VERSION ""

NS_ :

BS_:

BU_: VMCU TECU OBDScanT2 IC3 HPCU EMS ECUspare2 ECUspare1 DACU CIOM BBM

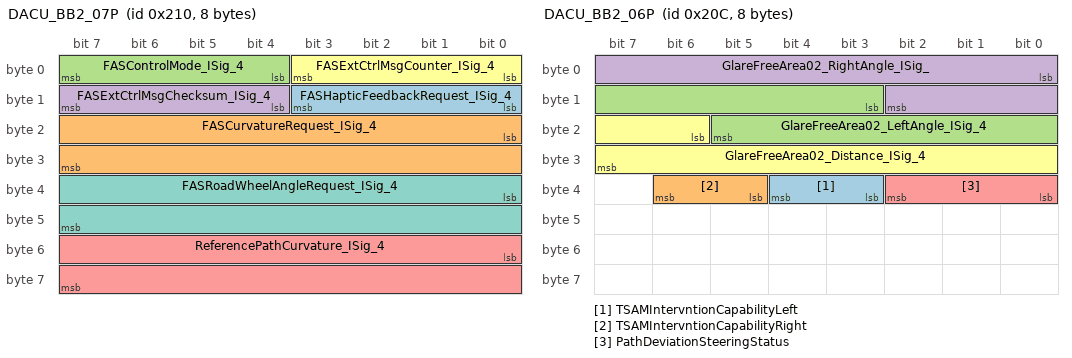
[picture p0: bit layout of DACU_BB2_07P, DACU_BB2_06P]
BO_ 528 DACU_BB2_07P: 8 DACU
 SG_ FASHapticFeedbackRequest_ISig_4 : 8|4@1+ (1,0) [0|0] ""  VMCU
 SG_ FASCurvatureRequest_ISig_4 : 16|16@1+ (7.62939E-006,-0.2472) [-0.2472|0.25279207365] "per_meter"  VMCU
 SG_ FASControlMode_ISig_4 : 4|4@1+ (0.1,0) [0|1.5] ""  VMCU
 SG_ FASExtCtrlMsgChecksum_ISig_4 : 12|4@1+ (1,0) [0|0] ""  VMCU
 SG_ ReferencePathCurvature_ISig_4 : 48|16@1+ (7.62939E-006,-0.2472) [-0.2472|0.25279207365] "per_meter"  VMCU
 SG_ FASExtCtrlMsgCounter_ISig_4 : 0|4@1+ (1,0) [0|0] ""  VMCU
 SG_ FASRoadWheelAngleRequest_ISig_4 : 32|16@1+ (5E-005,-1.6) [-1.6|1.67675] "rad"  VMCU

BO_ 524 DACU_BB2_06P: 8 DACU
 SG_ TSAMIntervntionCapabilityLeft : 35|2@1+ (1,0) [0|0] ""  IC3
 SG_ TSAMIntervntionCapabilityRight : 37|2@1+ (1,0) [0|0] ""  IC3
 SG_ GlareFreeArea02_LeftAngle_ISig_4 : 11|11@1+ (0.0494,-31.65) [-31.65|69.4718] "deg"  VMCU
 SG_ GlareFreeArea02_RightAngle_ISig_ : 0|11@1+ (0.0494,-31.65) [-31.65|69.4718] "deg"  VMCU
 SG_ PathDeviationSteeringStatus : 32|3@1+ (1,0) [0|0] ""  IC3
 SG_ GlareFreeArea02_Distance_ISig_4 : 22|10@1+ (0.5,0) [0|511.5] "m"  VMCU

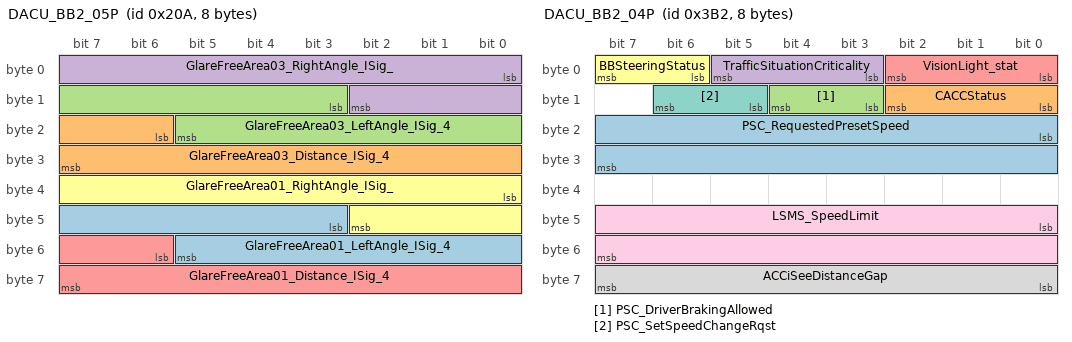
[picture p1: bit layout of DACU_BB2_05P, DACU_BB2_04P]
BO_ 522 DACU_BB2_05P: 8 DACU
 SG_ GlareFreeArea01_LeftAngle_ISig_4 : 43|11@1+ (0.0494,-31.65) [-31.65|69.4718] "deg"  VMCU
 SG_ GlareFreeArea03_Distance_ISig_4 : 22|10@1+ (0.5,0) [0|511.5] "m"  VMCU
 SG_ GlareFreeArea03_LeftAngle_ISig_4 : 11|11@1+ (0.0494,-31.65) [-31.65|69.4718] "deg"  VMCU
 SG_ GlareFreeArea03_RightAngle_ISig_ : 0|11@1+ (0.0494,-31.65) [-31.65|69.4718] "deg"  VMCU
 SG_ GlareFreeArea01_Distance_ISig_4 : 54|10@1+ (0.5,0) [0|511.5] "m"  VMCU
 SG_ GlareFreeArea01_RightAngle_ISig_ : 32|11@1+ (0.0494,-31.65) [-31.65|69.4718] "deg"  VMCU

BO_ 946 DACU_BB2_04P: 8 DACU
 SG_ PSC_RequestedPresetSpeed : 16|16@1+ (0.00390625,0) [0|255.99609375] "Km_per_h"  VMCU
 SG_ CACCStatus : 8|3@1+ (1,0) [0|0] ""  IC3,TECU
 SG_ PSC_DriverBrakingAllowed : 11|2@1+ (1,0) [0|0] ""  VMCU
 SG_ TrafficSituationCriticality : 3|3@1+ (1,0) [0|7] ""  IC3
 SG_ VisionLight_stat : 0|3@1+ (1,0) [0|0] ""  VMCU
 SG_ BBSteeringStatus : 6|2@1+ (1,0) [0|0] ""  BBM
 SG_ PSC_SetSpeedChangeRqst : 13|2@1+ (1,0) [0|0] ""  VMCU
 SG_ ACCiSeeDistanceGap : 56|8@1+ (1,-127) [-127|128] "m"  TECU
 SG_ LSMS_SpeedLimit : 40|16@1+ (0.00390625,0) [0|255.99609375] "Km_per_h"  VMCU

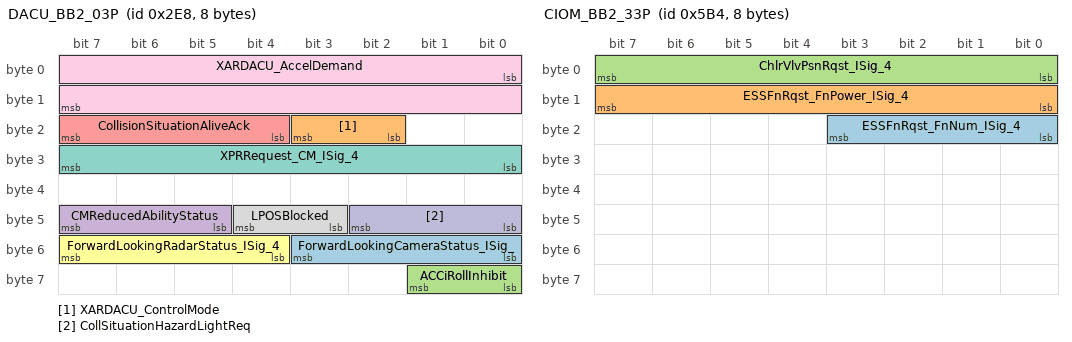
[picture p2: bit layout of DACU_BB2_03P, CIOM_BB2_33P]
BO_ 744 DACU_BB2_03P: 8 DACU
 SG_ ForwardLookingCameraStatus_ISig_ : 48|4@1+ (1,0) [0|0] ""  IC3
 SG_ XARDACU_ControlMode : 18|2@1+ (1,0) [0|0] ""  EMS,TECU
 SG_ ACCiRollInhibit : 56|2@1+ (1,0) [0|0] ""  TECU
 SG_ CMReducedAbilityStatus : 45|3@1+ (1,0) [0|0] ""  IC3
 SG_ CollisionSituationAliveAck : 20|4@1+ (1,0) [0|15] "Count"  VMCU
 SG_ ForwardLookingRadarStatus_ISig_4 : 52|4@1+ (1,0) [0|0] ""  IC3
 SG_ XPRRequest_CM_ISig_4 : 24|8@1+ (1,0) [0|255] "NotApplicable"  VMCU
 SG_ LPOSBlocked : 43|2@1+ (1,0) [0|0] ""  IC3
 SG_ XARDACU_AccelDemand : 0|16@1+ (0.00048828125,-15.687) [-15.687|16.31251171875] "m_per_s_squared"  EMS,TECU
 SG_ CollSituationHazardLightReq : 40|3@1+ (1,0) [0|0] ""  VMCU

BO_ 560 DACU_BB2_02P: 8 DACU
 SG_ PathDeviationDriverAlert : 24|3@1+ (1,0) [0|0] ""  IC3,VMCU
 SG_ CM_DisengageDrivelineRequest : 51|2@1+ (1,0) [0|0] ""  TECU
 SG_ ACCBrakeRequestStatus : 30|2@1+ (1,0) [0|0] ""  VMCU
 SG_ FrontalCollisionDriverAlert_ISig : 19|3@1+ (1,0) [0|0] ""  IC3,VMCU
 SG_ ACC_SGOFaultCondStat_SeatBelt : 59|1@1+ (1,0) [0|0] ""  IC3
 SG_ CM_Status_ISig_4 : 43|3@1+ (1,0) [0|0] ""  CIOM,VMCU,IC3
 SG_ DASApplicationStatus_ISig_4 : 40|3@1+ (1,0) [0|0] ""  IC3,VMCU,CIOM
 SG_ ACC_Status : 16|3@1+ (1,0) [0|0] ""  VMCU,IC3,TECU
 SG_ LKSApplicationStatus_ISig_4 : 27|3@1+ (1,0) [0|0] ""  CIOM,VMCU,IC3
 SG_ LCSSystemStatus : 48|3@1+ (1,0) [0|0] ""  IC3,CIOM
 SG_ ACC_SGOFaultCondStat_SigStat : 60|1@1+ (1,0) [0|0] ""  IC3
 SG_ ACC_SGOFaultCondStat_Target : 58|1@1+ (1,0) [0|0] ""  IC3
 SG_ FCW_Status : 46|2@1+ (1,0) [0|0] ""  IC3,CIOM,VMCU
 SG_ DriverImpairedDriverAlert_ISig_4 : 32|3@1+ (1,0) [0|0] ""  IC3,VMCU
 SG_ DriverVigilanceLevel : 35|3@1+ (1,0) [0|0] ""  IC3,VMCU
 SG_ ACCForwardVehicleSpeed_ISig_4 : 8|8@1+ (1,0) [0|255] "Km_per_h"  TECU,IC3
 SG_ ACC_SGOFaultCondStat_Door : 57|1@1+ (1,0) [0|0] ""  IC3
 SG_ ACCTargetDetected : 22|2@1+ (1,0) [0|0] ""  IC3
 SG_ ACCForwardVehicleDistance_ISig_4 : 0|8@1+ (1,0) [0|255] "m"  IC3,TECU
 SG_ LKSCorrectiveSteeringStatus : 61|3@1+ (1,0) [0|0] ""  IC3,VMCU,CIOM
 SG_ ACC_SGOFaultCondStat_Other : 55|1@1+ (1,0) [0|0] ""  IC3
 SG_ LCSSoundSettingStatus : 53|2@1+ (1,0) [0|0] ""  IC3
 SG_ ACC_SGOFaultCondStat_Speed : 56|1@1+ (1,0) [0|0] ""  IC3

BO_ 1460 CIOM_BB2_33P: 8 CIOM
 SG_ ESSFnRqst_FnNum_ISig_4 : 16|4@1+ (1,0) [0|15] "NotApplicable"  HPCU
 SG_ ESSFnRqst_FnPower_ISig_4 : 8|8@1+ (1,0) [0|255] "Percent"  HPCU
 SG_ ChlrVlvPsnRqst_ISig_4 : 0|8@1+ (1,0) [0|255] "Percent"  HPCU

BO_ 936 CIOM_BB2_32S_FCM: 8 TECU
 SG_ CIOM_BB2_32S_FCS : 0|64@1+ (1,0) [0|0] ""  CIOM

BO_ 935 CIOM_BB2_32S: 16 CIOM
 SG_ EncryptedGBUnlockAuth_stat : 0|128@1+ (1,0) [0|0] ""  TECU

BO_ 1369 CIOM_BB2_31S: 8 CIOM
 SG_ ParkClimTimerStat_Tue_ISig_4 : 15|1@1+ (1,0) [0|0] ""  IC3
 SG_ ParkClimTimerStat_Mon_ISig_4 : 17|1@1+ (1,0) [0|0] ""  IC3
 SG_ ParkClimTimerStat_Hrs_ISig_4 : 31|8@1+ (1,0) [0|255] "h"  IC3
 SG_ ParkClimTimerStat_TotalNoTimers_ : 23|8@1+ (1,0) [0|0] ""  IC3
 SG_ ParkClimTimerStat_Thu_ISig_4 : 16|1@1+ (1,0) [0|0] ""  IC3
 SG_ ParkClimTimerStat_MinRes_ISig_4 : 7|3@1+ (1,0) [0|0] ""  IC3
 SG_ ParkClimTimerStat_Status_ISig_4 : 13|2@1+ (1,0) [0|0] ""  IC3
 SG_ ParkClimTimerStat_Sun_ISig_4 : 20|1@1+ (1,0) [0|0] ""  IC3
 SG_ ParkClimTimerStat_sg_UB_ISig_4 : 63|1@1+ (1,0) [0|0] ""  IC3
 SG_ ParkClimTimerStat_TimerNr_ISig_4 : 39|8@1+ (1,0) [0|0] ""  IC3
 SG_ ParkClimTimerStat_Rec_ISig_4 : 19|1@1+ (1,0) [0|0] ""  IC3
 SG_ ParkClimTimerStat_Wed_ISig_4 : 22|1@1+ (1,0) [0|0] ""  IC3
 SG_ ParkClimTimerStat_Min_ISig_4 : 55|8@1+ (1,0) [0|255] "min"  IC3
 SG_ ParkClimTimerStat_Type_ISig_4 : 10|3@1+ (1,0) [0|0] ""  IC3
 SG_ ParkClimTimerStat_Sat_ISig_4 : 21|1@1+ (1,0) [0|0] ""  IC3
 SG_ ParkClimTimerStat_Temp_ISig_4 : 47|8@1+ (0.5,0) [0|127.5] "DegreeC"  IC3
 SG_ ParkClimTimerStat_Dur_ISig_4 : 0|7@1+ (1,0) [0|127] "min"  IC3
 SG_ ParkClimTimerStat_Fri_ISig_4 : 18|1@1+ (1,0) [0|0] ""  IC3

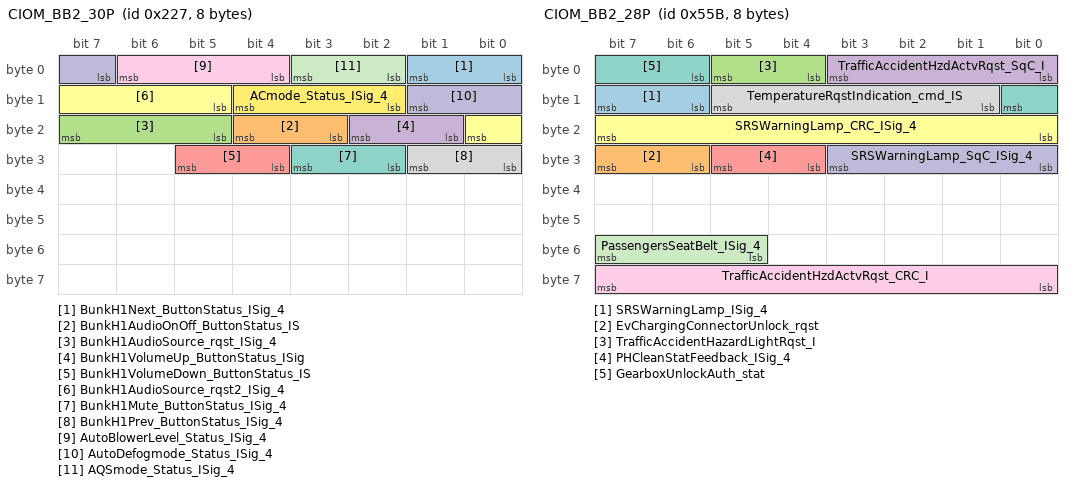
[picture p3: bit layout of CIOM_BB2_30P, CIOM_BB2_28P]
BO_ 551 CIOM_BB2_30P: 8 CIOM
 SG_ BunkH1Next_ButtonStatus_ISig_4 : 0|2@1+ (1,0) [0|0] ""  IC3
 SG_ BunkH1AudioOnOff_ButtonStatus_IS : 19|2@1+ (1,0) [0|0] ""  IC3
 SG_ BunkH1AudioSource_rqst_ISig_4 : 21|3@1+ (1,0) [0|0] ""  IC3
 SG_ BunkH1VolumeUp_ButtonStatus_ISig : 17|2@1+ (1,0) [0|0] ""  IC3
 SG_ BunkH1VolumeDown_ButtonStatus_IS : 28|2@1+ (1,0) [0|0] ""  IC3
 SG_ BunkH1AudioSource_rqst2_ISig_4 : 13|4@1+ (1,0) [0|0] ""  IC3
 SG_ BunkH1Mute_ButtonStatus_ISig_4 : 26|2@1+ (1,0) [0|0] ""  IC3
 SG_ BunkH1Prev_ButtonStatus_ISig_4 : 24|2@1+ (1,0) [0|0] ""  IC3
 SG_ AutoBlowerLevel_Status_ISig_4 : 4|3@1+ (1,0) [0|0] ""  IC3
 SG_ AutoDefogmode_Status_ISig_4 : 7|3@1+ (1,0) [0|0] ""  IC3
 SG_ AQSmode_Status_ISig_4 : 2|2@1+ (1,0) [0|0] ""  IC3
 SG_ ACmode_Status_ISig_4 : 10|3@1+ (1,0) [0|0] ""  IC3

BO_ 550 CIOM_BB2_29P: 8 CIOM
 SG_ LKSCSEnableSwitch_rqst : 0|2@1+ (1,0) [0|0] ""  DACU

BO_ 1371 CIOM_BB2_28P: 8 CIOM
 SG_ SRSWarningLamp_ISig_4 : 14|2@1+ (1,0) [0|0] ""  IC3
 SG_ EvChargingConnectorUnlock_rqst : 30|2@1+ (1,0) [0|0] ""  HPCU
 SG_ TrafficAccidentHazardLightRqst_I : 4|2@1+ (1,0) [0|0] ""  VMCU
 SG_ TrafficAccidentHzdActvRqst_SqC_I : 0|4@1+ (1,0) [0|15] "Count"  VMCU
 SG_ PHCleanStatFeedback_ISig_4 : 28|2@1+ (1,0) [0|0] ""  IC3
 SG_ SRSWarningLamp_CRC_ISig_4 : 16|8@1+ (1,0) [0|255] ""  IC3
 SG_ GearboxUnlockAuth_stat : 6|3@1+ (1,0) [0|0] ""  TECU
 SG_ TemperatureRqstIndication_cmd_IS : 9|5@1+ (1,0) [0|0] ""  IC3
 SG_ TrafficAccidentHzdActvRqst_CRC_I : 56|8@1+ (1,0) [0|255] ""  VMCU
 SG_ SRSWarningLamp_SqC_ISig_4 : 24|4@1+ (1,0) [0|15] "Count"  IC3
 SG_ PassengersSeatBelt_ISig_4 : 53|3@1+ (1,0) [0|0] ""  IC3,BBM,DACU

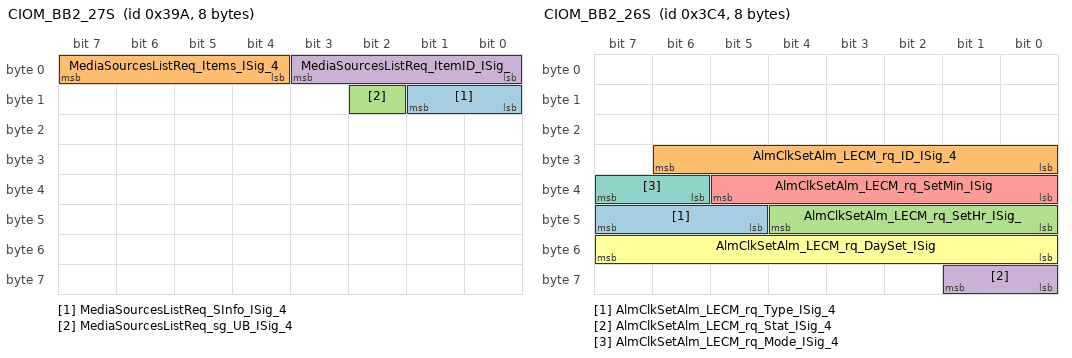
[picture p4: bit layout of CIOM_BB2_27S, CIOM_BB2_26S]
BO_ 922 CIOM_BB2_27S: 8 CIOM
 SG_ MediaSourcesListReq_SInfo_ISig_4 : 8|2@1+ (1,0) [0|0] ""  IC3
 SG_ MediaSourcesListReq_Items_ISig_4 : 4|4@1+ (1,0) [0|0] ""  IC3
 SG_ MediaSourcesListReq_sg_UB_ISig_4 : 10|1@1+ (1,0) [0|0] ""  IC3
 SG_ MediaSourcesListReq_ItemID_ISig_ : 0|4@1+ (1,0) [0|0] ""  IC3

BO_ 964 CIOM_BB2_26S: 8 CIOM
 SG_ AlmClkSetAlm_LECM_rq_Type_ISig_4 : 45|3@1+ (1,0) [0|0] ""  IC3
 SG_ AlmClkSetAlm_LECM_rq_ID_ISig_4 : 24|7@1+ (1,0) [0|0] ""  IC3
 SG_ AlmClkSetAlm_LECM_rq_SetHr_ISig_ : 40|5@1+ (1,0) [0|31] "h"  IC3
 SG_ AlmClkSetAlm_LECM_rq_Stat_ISig_4 : 56|2@1+ (1,0) [0|0] ""  IC3
 SG_ AlmClkSetAlm_LECM_rq_SetMin_ISig : 32|6@1+ (1,0) [0|63] "min"  IC3
 SG_ AlmClkSetAlm_LECM_rq_DaySet_ISig : 48|8@1+ (1,0) [0|255] ""  IC3
 SG_ AlmClkSetAlm_LECM_rq_Mode_ISig_4 : 38|2@1+ (1,0) [0|0] ""  IC3

BO_ 845 CIOM_BB2_25P: 8 CIOM
 SG_ TipperTailGateRequest_UB_ISig_4 : 23|1@1+ (1,0) [0|0] ""  BBM
 SG_ TrafficAccShutDownReq_CRC_ISig_4 : 48|8@1+ (1,0) [0|255] ""  VMCU
 SG_ ExtraHeating_status_ISig_4 : 32|2@1+ (1,0) [0|0] ""  IC3
 SG_ FrontalCollisionAccidentStatus_I : 39|2@1+ (1,0) [0|0] ""  DACU
 SG_ LoadDistributionRequested_UB_ISi : 36|1@1+ (1,0) [0|0] ""  VMCU
 SG_ TipperUpDownRequest_ISig_4 : 17|3@1+ (1,0) [0|0] ""  BBM
 SG_ TipperTarpaulinRequest_UB_ISig_4 : 27|1@1+ (1,0) [0|0] ""  BBM
 SG_ LoadDistributionRequested_ISig_4 : 28|4@1+ (1,0) [0|0] ""  VMCU
 SG_ TipperShakerRequest_UB_ISig_4 : 21|1@1+ (1,0) [0|0] ""  BBM
 SG_ TailLiftMotionRequest_UB_ISig_4 : 20|1@1+ (1,0) [0|0] ""  BBM
 SG_ TipperTailGateRequest_ISig_4 : 8|3@1+ (1,0) [0|0] ""  BBM
 SG_ TipperTippingBodySelection_ISig_ : 6|2@1+ (1,0) [0|0] ""  BBM
 SG_ TipperEmergencyStop_ISig_4 : 0|2@1+ (1,0) [0|0] ""  BBM
 SG_ TipperTippingBodySelection_UB_IS : 26|1@1+ (1,0) [0|0] ""  BBM
 SG_ ExtraBbWrcWatchdog_ISig_4 : 2|2@1+ (1,0) [0|0] ""  BBM
 SG_ TipperEmergencyStop_UB_ISig_4 : 25|1@1+ (1,0) [0|0] ""  BBM
 SG_ AutoFrontWheelDriveDrvReq : 37|2@1+ (1,0) [0|0] ""  VMCU
 SG_ ShortStopHeater_cmd_ISig_4 : 34|2@1+ (1,0) [0|0] ""  VMCU
 SG_ TipperUpDownRequest_UB_ISig_4 : 24|1@1+ (1,0) [0|0] ""  BBM
 SG_ TailLiftMotionRequest_ISig_4 : 14|3@1+ (1,0) [0|0] ""  BBM
 SG_ TipperShakerRequest_ISig_4 : 4|2@1+ (1,0) [0|0] ""  BBM
 SG_ TrafficAccShutDownReq_Rqst_ISig_ : 60|2@1+ (1,0) [0|0] ""  VMCU
 SG_ TipperTarpaulinRequest_ISig_4 : 11|3@1+ (1,0) [0|0] ""  BBM
 SG_ TrafficAccShutDownReq_SqC_ISig_4 : 56|4@1+ (1,0) [0|0] ""  VMCU
 SG_ ExtraBbWrcWatchdog_UB_ISig_4 : 22|1@1+ (1,0) [0|0] ""  BBM
 SG_ ABSInhibitRqstDenied : 41|2@1+ (1,0) [0|0] ""  IC3

BO_ 1074 CIOM_BB2_21S: 8 CIOM
 SG_ DynamicCode_value : 0|32@1+ (1,0) [0|4294967295] "NotApplicable"  IC3

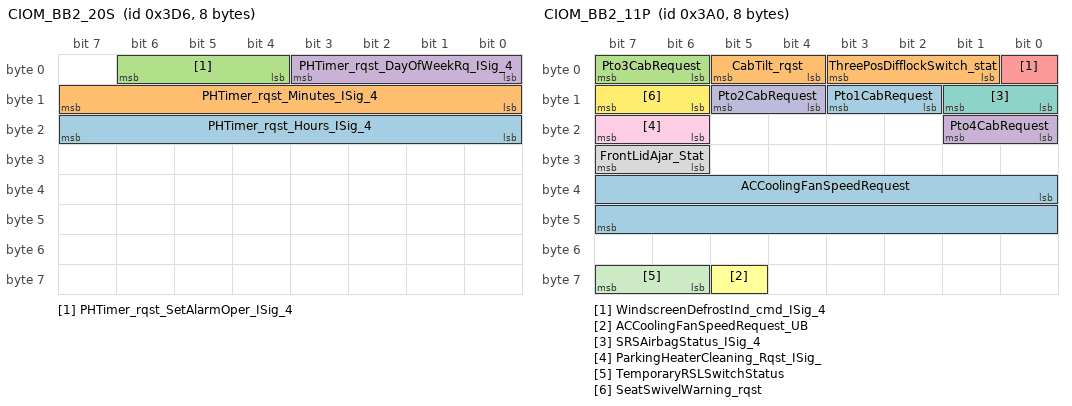
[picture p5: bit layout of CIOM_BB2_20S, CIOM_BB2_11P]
BO_ 982 CIOM_BB2_20S: 8 CIOM
 SG_ PHTimer_rqst_Hours_ISig_4 : 16|8@1+ (1,0) [0|255] "h"  VMCU
 SG_ PHTimer_rqst_Minutes_ISig_4 : 8|8@1+ (1,0) [0|255] "min"  VMCU
 SG_ PHTimer_rqst_SetAlarmOper_ISig_4 : 4|3@1+ (1,0) [0|0] ""  VMCU
 SG_ PHTimer_rqst_DayOfWeekRq_ISig_4 : 0|4@1+ (1,0) [0|0] ""  VMCU

BO_ 943 CIOM_BB2_13S_FCM: 8 EMS
 SG_ CIOM_BB2_13S_FCS : 0|64@1+ (1,0) [0|0] ""  CIOM

BO_ 940 CIOM_BB2_13S: 16 CIOM
 SG_ EngineStartAuth_stat : 0|128@1+ (1,0) [0|0] ""  EMS

BO_ 937 CIOM_BB2_12S_FCM: 8 VMCU
 SG_ CIOM_BB2_12S_FCS : 0|64@1+ (1,0) [0|0] ""  CIOM

BO_ 934 CIOM_BB2_12S: 16 CIOM
 SG_ KeyAuthEncrypted_stat : 0|128@1+ (1,0) [0|0] ""  VMCU

BO_ 928 CIOM_BB2_11P: 8 CIOM
 SG_ ACCoolingFanSpeedRequest : 32|16@1+ (1,0) [0|65535] "rpm"  EMS
 SG_ CabTilt_rqst : 4|2@1+ (1,0) [0|0] ""  VMCU
 SG_ Pto3CabRequest : 6|2@1+ (1,0) [0|0] ""  BBM,VMCU
 SG_ Pto4CabRequest : 16|2@1+ (1,0) [0|0] ""  VMCU,BBM
 SG_ WindscreenDefrostInd_cmd_ISig_4 : 0|1@1+ (1,0) [0|0] ""  BBM
 SG_ ACCoolingFanSpeedRequest_UB : 61|1@1+ (1,0) [0|0] ""  EMS
 SG_ SRSAirbagStatus_ISig_4 : 8|2@1+ (1,0) [0|0] ""  DACU,IC3,VMCU
 SG_ FrontLidAjar_Stat : 30|2@1+ (1,0) [0|0] ""  VMCU
 SG_ ParkingHeaterCleaning_Rqst_ISig_ : 22|2@1+ (1,0) [0|0] ""  IC3
 SG_ Pto2CabRequest : 12|2@1+ (1,0) [0|0] ""  BBM,VMCU
 SG_ TemporaryRSLSwitchStatus : 62|2@1+ (1,0) [0|0] ""  IC3
 SG_ SeatSwivelWarning_rqst : 14|2@1+ (1,0) [0|0] ""  IC3
 SG_ Pto1CabRequest : 10|2@1+ (1,0) [0|0] ""  VMCU,BBM
 SG_ ThreePosDifflockSwitch_stat : 1|3@1+ (1,0) [0|0] ""  IC3

BO_ 857 CIOM_BB2_10P: 8 CIOM
 SG_ LCS_EnableSwitch_rqst : 40|2@1+ (1,0) [0|0] ""  DACU
 SG_ EscCrossCountryActivation_rqst : 52|2@1+ (1,0) [0|0] ""  VMCU
 SG_ StaticCornerLightMode : 54|2@1+ (1,0) [0|0] ""  VMCU
 SG_ SplitBoxDifflockActvnDrvrRqst_IS : 48|2@1+ (1,0) [0|0] ""  EMS,VMCU,IC3,TECU
 SG_ ATCFrontWheelDriveRequest : 61|2@1+ (1,0) [0|0] ""  VMCU
 SG_ ConstructionSwitch_stat : 50|2@1+ (1,0) [0|0] ""  TECU
 SG_ EscCabActionRequest : 8|3@1+ (1,0) [0|0] ""  VMCU
 SG_ AdjustRequestForIdle : 58|3@1+ (1,0) [0|0] ""  VMCU
 SG_ SCL_LogicPowerOutput_stat : 36|2@1+ (1,0) [0|0] ""  VMCU
 SG_ PinCode_validity_time : 0|8@1+ (1,1) [1|256] "h"  IC3
 SG_ StatTrailerBrakeSwitchStatus : 14|2@1+ (1,0) [0|0] ""  VMCU
 SG_ SplitBoxDifflockActvnDrvrRqst_UB : 32|1@1+ (1,0) [0|0] ""  EMS,TECU,VMCU,IC3
 SG_ RoofHatch_HMI_rqst : 16|3@1+ (1,0) [0|0] ""  VMCU
 SG_ EscCabEnable : 38|2@1+ (1,0) [0|0] ""  VMCU
 SG_ ExtraSideMarkers_Rqst : 19|2@1+ (1,0) [0|0] ""  VMCU
 SG_ LevelingThumbwheel_stat : 24|5@1+ (1,0) [0|0] ""  VMCU
 SG_ DASActivation_rqst : 44|2@1+ (1,0) [0|0] ""  DACU
 SG_ DriverSeatBeltSwitch_ISig_4 : 22|2@1+ (1,0) [0|0] ""  VMCU,DACU,BBM,IC3
 SG_ PinCode_stat : 29|3@1+ (1,0) [0|0] ""  IC3
 SG_ WarmUp_Request : 56|2@1+ (1,0) [0|0] ""  EMS
 SG_ LKSEnableSwitch_rqst : 46|2@1+ (1,0) [0|0] ""  DACU

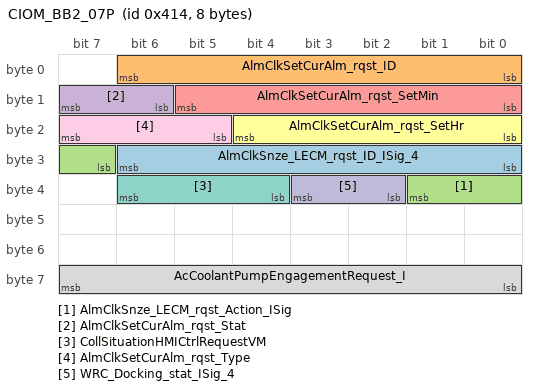
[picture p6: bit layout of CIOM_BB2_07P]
BO_ 1044 CIOM_BB2_07P: 8 CIOM
 SG_ AlmClkSnze_LECM_rqst_ID_ISig_4 : 24|7@1+ (1,0) [0|0] ""  IC3
 SG_ AlmClkSetCurAlm_rqst_ID : 0|7@1+ (1,0) [0|0] ""  VMCU
 SG_ AlmClkSnze_LECM_rqst_Action_ISig : 31|3@1+ (1,0) [0|0] ""  IC3
 SG_ AlmClkSetCurAlm_rqst_Stat : 14|2@1+ (1,0) [0|0] ""  VMCU
 SG_ AlmClkSetCurAlm_rqst_SetMin : 8|6@1+ (1,0) [0|63] "min"  VMCU
 SG_ AlmClkSetCurAlm_rqst_SetHr : 16|5@1+ (1,0) [0|31] "h"  VMCU
 SG_ CollSituationHMICtrlRequestVM : 36|3@1+ (1,0) [0|0] ""  IC3
 SG_ AcCoolantPumpEngagementRequest_I : 56|8@1+ (0.4,0) [0|102] "Percent"  EMS
 SG_ AlmClkSetCurAlm_rqst_Type : 21|3@1+ (1,0) [0|0] ""  VMCU
 SG_ WRC_Docking_stat_ISig_4 : 34|2@1+ (1,0) [0|0] ""  IC3

BO_ 847 CIOM_BB2_06P: 8 CIOM
 SG_ LiftAxle1DirectControl_UB_ISig_4 : 59|1@1+ (1,0) [0|0] ""  VMCU
 SG_ MirrorSelectRightMainBtn_stat_IS : 30|2@1+ (1,0) [0|0] ""  IC3
 SG_ WRCEngineStopRequest_ISig_4 : 38|2@1+ (1,0) [0|0] ""  BBM
 SG_ LiftAxle1DirectControl_ISig_4 : 56|3@1+ (1,0) [0|0] ""  VMCU
 SG_ MirrorSelectRightWideBtn_stat_IS : 6|2@1+ (1,0) [0|0] ""  IC3
 SG_ PanicAlarmFromKeyfob_rqst : 2|2@1+ (1,0) [0|0] ""  VMCU
 SG_ ParkingClimate_IndicationCmd_ISi : 51|3@1+ (1,0) [0|0] ""  IC3
 SG_ MirrorSelectLeftWideBtn_stat_ISi : 4|2@1+ (1,0) [0|0] ""  IC3
 SG_ WRCEngineStartRequest_ISig_4 : 36|2@1+ (1,0) [0|0] ""  BBM
 SG_ PW_Left_DS_SwStatus_ISig_4 : 19|3@1+ (1,0) [0|0] ""  IC3
 SG_ RegenerationSwitchStatus : 48|3@1+ (1,0) [0|0] ""  IC3
 SG_ PW_Right_DS_SwStatus_ISig_4 : 24|3@1+ (1,0) [0|0] ""  IC3
 SG_ DoorLock_stat_ISig_4 : 8|4@1+ (1,0) [0|0] ""  BBM,IC3
 SG_ WRCEngineStartRequest_UB_ISig_4 : 40|1@1+ (1,0) [0|0] ""  BBM
 SG_ LuggageAjar_stat : 32|3@1+ (1,0) [0|0] ""  IC3
 SG_ AlarmStatus_stat_ISig_4 : 44|4@1+ (1,0) [0|0] ""  IC3
 SG_ AlarmTriggeringCause_stat_ISig_4 : 12|4@1+ (1,0) [0|0] ""  BBM,IC3
 SG_ DoorsAjar_stat_UB_ISig_4 : 35|1@1+ (1,0) [0|0] ""  DACU,VMCU,IC3,BBM
 SG_ DoorsAjar_stat_ISig_4 : 16|3@1+ (1,0) [0|0] ""  IC3,VMCU,DACU,BBM
 SG_ WRCEngineStopRequest_UB_ISig_4 : 41|1@1+ (1,0) [0|0] ""  BBM
 SG_ DoorAutoFunction_rqst : 22|2@1+ (1,0) [0|0] ""  VMCU
 SG_ MirrorSelectLeftMainBtn_stat_ISi : 0|2@1+ (1,0) [0|0] ""  IC3

BO_ 841 CIOM_BB2_05P: 8 CIOM
 SG_ FPBRChangeReq_ISig_4 : 52|2@1+ (1,0) [0|0] ""  VMCU
 SG_ HeadLampUpDown_SwitchStatus : 32|3@1+ (1,0) [0|0] ""  VMCU
 SG_ Recirc_ButtonStatus_ISig_4 : 18|2@1+ (1,0) [0|0] ""  IC3
 SG_ Auto_ButtonStatus_ISig_4 : 14|2@1+ (1,0) [0|0] ""  IC3
 SG_ AirFlowSelectionFrontBtn_stat_IS : 35|2@1+ (1,0) [0|0] ""  IC3
 SG_ InteriorLightMode_rqst_IL_Mode : 48|3@1+ (1,0) [0|0] ""  VMCU
 SG_ InteriorLightMode_rqst_EventFlag : 51|1@1+ (1,0) [0|0] ""  VMCU
 SG_ BlackOutConvoyModeSwitchStatus : 24|3@1+ (1,0) [0|0] ""  VMCU
 SG_ Indicator_Lights_Alarm_rqst_ISig : 27|3@1+ (1,0) [0|0] ""  VMCU
 SG_ AirFlowSelectionDownBtn_stat_ISi : 16|2@1+ (1,0) [0|0] ""  IC3
 SG_ ParkingHeater_IndicationCmd_ISig : 39|1@1+ (1,0) [0|0] ""  BBM
 SG_ AirFlowSelectionUpBtn_stat_ISig_ : 10|2@1+ (1,0) [0|0] ""  IC3
 SG_ ApproachLight_HMI_rqst : 44|2@1+ (1,0) [0|0] ""  VMCU
 SG_ Temperature_FreeWheelStatus_ISig : 20|4@1+ (1,0) [0|0] ""  IC3
 SG_ AirBlowerSpeed_FreeWheelStatus_I : 40|4@1+ (1,0) [0|0] ""  IC3
 SG_ CabInteriorTempVentilated_Stat_I : 0|10@1+ (0.125,-40) [-40|87.875] "DegreeC"  BBM
 SG_ PreTrip_ButtonStat3 : 30|2@1+ (1,0) [0|0] ""  IC3
 SG_ ParkHeaterCooler_ButtonStatus_IS : 12|2@1+ (1,0) [0|0] ""  IC3
 SG_ WindscreenDefrost_ButtonStatus_I : 46|2@1+ (1,0) [0|0] ""  IC3
 SG_ AC_ButtonStatus_ISig_4 : 37|2@1+ (1,0) [0|0] ""  IC3

CM_ SG_ 744 XARDACU_AccelDemand "65024 - 65279 Error ; 65280 - 65535 Not available";
CM_ SG_ 560 ACCForwardVehicleSpeed_ISig_4 "254 Error ; 255 Not available";
CM_ SG_ 560 ACCForwardVehicleDistance_ISig_4 "254 Error ; 255 Not Available";
CM_ SG_ 964 AlmClkSetAlm_LECM_rq_SetHr_ISig_ "30 Error ; 31 Not Available";
CM_ SG_ 964 AlmClkSetAlm_LECM_rq_SetMin_ISig "62 Error ; 63 Not Available";
CM_ SG_ 982 PHTimer_rqst_Hours_ISig_4 "254 Error ; 255 Not available";
CM_ SG_ 982 PHTimer_rqst_Minutes_ISig_4 "254 Error ; 255 Not available";
CM_ SG_ 928 ACCoolingFanSpeedRequest "65024 - 65279 Error ; 65280 - 65535 Not available";
CM_ SG_ 841 CabInteriorTempVentilated_Stat_I "1022 Error; 1023 Not Available";
BA_DEF_ BO_  "GenMsgStartDelayTime" INT 0 0;
BA_DEF_ BO_  "GenMsgDelayTime" INT 0 0;
BA_DEF_ BO_  "GenMsgCycleTime" INT 0 0;
BA_DEF_ BO_  "GenMsgSendType" ENUM  "Cyclic","NotUsed","NotUsed","NotUsed","NotUsed","NotUsed","NotUsed","IfActive","NoMsgSendType","NotUsed";
BA_DEF_ SG_  "GenSigStartValue" INT 0 0;
BA_DEF_ SG_  "GenSigCycleTimeActive" INT 0 0;
BA_DEF_ SG_  "GenSigCycleTime" INT 0 0;
BA_DEF_ SG_  "GenSigSendType" ENUM  "Cyclic","OnWrite","OnWriteWithRepetition","OnChange","OnChangeWithRepetition","IfActive","IfActiveWithRepetition","NoSigSendType","NotUsed","NotUsed","NotUsed","NotUsed","NotUsed";
BA_DEF_ BO_  "VFrameFormat" ENUM  "StandardCAN","ExtendedCAN","reserved","J1939PG","reserved","reserved","reserved","reserved","reserved","reserved","reserved","reserved","reserved","reserved","StandardCAN_FD","ExtendedCAN_FD";
BA_DEF_ SG_  "SigType" ENUM  "Default","Range","RangeSigned","ASCII","Discrete","Control","ReferencePGN","DTC","StringDelimiter","StringLength","StringLengthControl";
BA_DEF_ SG_  "SeToolVersion_SIGNAL" STRING ;
BA_DEF_ SG_  "SeToolUniqueID_SIGNAL" STRING ;
BA_DEF_ SG_  "SeToolOwnerSigGroup_SIGNAL" STRING ;
BA_DEF_ SG_  "SeToolOwnerSigGroupID_SIGNAL" STRING ;
BA_DEF_ SG_  "SeToolName_SIGNAL" STRING ;
BA_DEF_ SG_  "SeToolItemID_SIGNAL" STRING ;
BA_DEF_ SG_  "SeToolAncestorID_SIGNAL" STRING ;
BA_DEF_ SG_  "Platform_VMCU1_Sig" ENUM  "No","Yes";
BA_DEF_ SG_  "Platform_FactoryIf_Sig" ENUM  "No","Yes";
BA_DEF_ BO_  "NmAsrMessage" ENUM  "No","Yes";
BA_DEF_ SG_  "NeedsUpdateBit" ENUM  "No","Yes";
BA_DEF_ SG_  "MmAnSignal" ENUM  "No","Yes";
BA_DEF_ SG_  "GenSigMaxLatency" INT 0 65535;
BA_DEF_ SG_  "GenSigILSupport" ENUM  "Yes","No";
BA_DEF_ BO_  "GenMsgILSupport" ENUM  "No","Yes";
BA_DEF_ BO_  "DiagUUDTResponse" ENUM  "No","Yes";
BA_DEF_ BO_  "DiagState" ENUM  "No","Yes";
BA_DEF_ BO_  "DiagResponse" ENUM  "No","Yes";
BA_DEF_ BO_  "DiagRequest" ENUM  "No","Yes";
BA_DEF_ BO_  "DiagConnection" HEX 0 65535;
BA_DEF_ BO_  "CanTpSTmin" INT 0 255;
BA_DEF_ BO_  "CanTpFcFrameId" HEX 0 2147483647;
BA_DEF_ BO_  "CanTpBs" INT 0 255;
BA_DEF_ SG_  "SystemSignalLongSymbol" STRING ;
BA_DEF_REL_ BU_SG_REL_  "GenSigTimeoutTime" INT 0 65535;
BA_DEF_REL_ BU_SG_REL_  "GenSigFirstTimeoutTime" INT 0 65535;
BA_DEF_DEF_  "GenMsgStartDelayTime" 0;
BA_DEF_DEF_  "GenMsgDelayTime" 0;
BA_DEF_DEF_  "GenMsgCycleTime" 0;
BA_DEF_DEF_  "GenMsgSendType" "Cyclic";
BA_DEF_DEF_  "GenSigStartValue" 0;
BA_DEF_DEF_  "GenSigCycleTimeActive" 0;
BA_DEF_DEF_  "GenSigCycleTime" 0;
BA_DEF_DEF_  "GenSigSendType" "Cyclic";
BA_DEF_DEF_  "VFrameFormat" "ExtendedCAN";
BA_DEF_DEF_  "SigType" "Default";
BA_DEF_DEF_  "SeToolVersion_SIGNAL" "";
BA_DEF_DEF_  "SeToolUniqueID_SIGNAL" "";
BA_DEF_DEF_  "SeToolOwnerSigGroup_SIGNAL" "";
BA_DEF_DEF_  "SeToolOwnerSigGroupID_SIGNAL" "";
BA_DEF_DEF_  "SeToolName_SIGNAL" "";
BA_DEF_DEF_  "SeToolItemID_SIGNAL" "";
BA_DEF_DEF_  "SeToolAncestorID_SIGNAL" "";
BA_DEF_DEF_  "Platform_VMCU1_Sig" "No";
BA_DEF_DEF_  "Platform_FactoryIf_Sig" "No";
BA_DEF_DEF_  "NmAsrMessage" "No";
BA_DEF_DEF_  "NeedsUpdateBit" "No";
BA_DEF_DEF_  "MmAnSignal" "No";
BA_DEF_DEF_  "GenSigMaxLatency" 0;
BA_DEF_DEF_  "GenSigILSupport" "Yes";
BA_DEF_DEF_  "GenMsgILSupport" "Yes";
BA_DEF_DEF_  "DiagUUDTResponse" "No";
BA_DEF_DEF_  "DiagState" "No";
BA_DEF_DEF_  "DiagResponse" "No";
BA_DEF_DEF_  "DiagRequest" "No";
BA_DEF_DEF_  "DiagConnection" 0;
BA_DEF_DEF_  "CanTpSTmin" 0;
BA_DEF_DEF_  "CanTpFcFrameId" 2147483647;
BA_DEF_DEF_  "CanTpBs" 255;
BA_DEF_DEF_REL_ "GenSigTimeoutTime" 0;
BA_DEF_DEF_REL_ "GenSigFirstTimeoutTime" 0;
BA_DEF_DEF_  "SystemSignalLongSymbol" "";
BA_ "VFrameFormat" BO_ 528 0;
BA_ "GenMsgCycleTime" BO_ 528 20;
BA_ "GenMsgStartDelayTime" BO_ 528 5;
BA_ "VFrameFormat" BO_ 524 0;
BA_ "GenMsgCycleTime" BO_ 524 20;
BA_ "GenMsgStartDelayTime" BO_ 524 10;
BA_ "VFrameFormat" BO_ 522 0;
BA_ "GenMsgCycleTime" BO_ 522 20;
BA_ "GenMsgStartDelayTime" BO_ 522 10;
BA_ "VFrameFormat" BO_ 946 0;
BA_ "GenMsgCycleTime" BO_ 946 100;
BA_ "GenMsgStartDelayTime" BO_ 946 15;
BA_ "VFrameFormat" BO_ 744 0;
BA_ "GenMsgCycleTime" BO_ 744 40;
BA_ "GenMsgStartDelayTime" BO_ 744 5;
BA_ "VFrameFormat" BO_ 560 0;
BA_ "GenMsgCycleTime" BO_ 560 20;
BA_ "VFrameFormat" BO_ 1460 0;
BA_ "GenMsgCycleTime" BO_ 1460 100;
BA_ "GenMsgStartDelayTime" BO_ 1460 5;
BA_ "GenMsgILSupport" BO_ 936 0;
BA_ "VFrameFormat" BO_ 936 0;
BA_ "GenMsgSendType" BO_ 936 8;
BA_ "CanTpFcFrameId" BO_ 935 936;
BA_ "VFrameFormat" BO_ 935 0;
BA_ "GenMsgSendType" BO_ 935 8;
BA_ "GenMsgDelayTime" BO_ 935 20;
BA_ "VFrameFormat" BO_ 1369 0;
BA_ "GenMsgSendType" BO_ 1369 8;
BA_ "GenMsgDelayTime" BO_ 1369 20;
BA_ "GenMsgStartDelayTime" BO_ 1369 20;
BA_ "VFrameFormat" BO_ 551 0;
BA_ "GenMsgCycleTime" BO_ 551 40;
BA_ "GenMsgStartDelayTime" BO_ 551 30;
BA_ "VFrameFormat" BO_ 550 0;
BA_ "GenMsgCycleTime" BO_ 550 40;
BA_ "GenMsgStartDelayTime" BO_ 550 10;
BA_ "VFrameFormat" BO_ 1371 0;
BA_ "GenMsgCycleTime" BO_ 1371 100;
BA_ "GenMsgStartDelayTime" BO_ 1371 50;
BA_ "VFrameFormat" BO_ 922 0;
BA_ "GenMsgSendType" BO_ 922 8;
BA_ "GenMsgDelayTime" BO_ 922 50;
BA_ "VFrameFormat" BO_ 964 0;
BA_ "GenMsgSendType" BO_ 964 8;
BA_ "GenMsgDelayTime" BO_ 964 75;
BA_ "VFrameFormat" BO_ 845 0;
BA_ "GenMsgCycleTime" BO_ 845 50;
BA_ "GenMsgStartDelayTime" BO_ 845 40;
BA_ "VFrameFormat" BO_ 1074 0;
BA_ "GenMsgSendType" BO_ 1074 8;
BA_ "GenMsgDelayTime" BO_ 1074 100;
BA_ "GenMsgStartDelayTime" BO_ 1074 15;
BA_ "VFrameFormat" BO_ 982 0;
BA_ "GenMsgSendType" BO_ 982 8;
BA_ "GenMsgDelayTime" BO_ 982 75;
BA_ "GenMsgILSupport" BO_ 943 0;
BA_ "VFrameFormat" BO_ 943 0;
BA_ "GenMsgSendType" BO_ 943 8;
BA_ "CanTpFcFrameId" BO_ 940 943;
BA_ "VFrameFormat" BO_ 940 0;
BA_ "GenMsgSendType" BO_ 940 8;
BA_ "GenMsgDelayTime" BO_ 940 20;
BA_ "GenMsgILSupport" BO_ 937 0;
BA_ "VFrameFormat" BO_ 937 0;
BA_ "GenMsgSendType" BO_ 937 8;
BA_ "CanTpFcFrameId" BO_ 934 937;
BA_ "VFrameFormat" BO_ 934 0;
BA_ "GenMsgSendType" BO_ 934 8;
BA_ "GenMsgDelayTime" BO_ 934 20;
BA_ "VFrameFormat" BO_ 928 0;
BA_ "GenMsgCycleTime" BO_ 928 95;
BA_ "GenMsgStartDelayTime" BO_ 928 40;
BA_ "VFrameFormat" BO_ 857 0;
BA_ "GenMsgCycleTime" BO_ 857 55;
BA_ "GenMsgStartDelayTime" BO_ 857 10;
BA_ "VFrameFormat" BO_ 1044 0;
BA_ "GenMsgCycleTime" BO_ 1044 100;
BA_ "GenMsgStartDelayTime" BO_ 1044 15;
BA_ "VFrameFormat" BO_ 847 0;
BA_ "GenMsgCycleTime" BO_ 847 50;
BA_ "GenMsgStartDelayTime" BO_ 847 25;
BA_ "VFrameFormat" BO_ 841 0;
BA_ "GenMsgCycleTime" BO_ 841 20;
BA_ "GenMsgStartDelayTime" BO_ 841 15;
BA_ "GenSigCycleTime" SG_ 528 FASHapticFeedbackRequest_ISig_4 100;
BA_ "GenSigCycleTimeActive" SG_ 528 FASHapticFeedbackRequest_ISig_4 100;
BA_ "GenSigStartValue" SG_ 528 FASHapticFeedbackRequest_ISig_4 15;
BA_ "GenSigMaxLatency" SG_ 528 FASHapticFeedbackRequest_ISig_4 25;
BA_ "GenSigCycleTime" SG_ 528 FASCurvatureRequest_ISig_4 100;
BA_ "GenSigCycleTimeActive" SG_ 528 FASCurvatureRequest_ISig_4 100;
BA_ "GenSigStartValue" SG_ 528 FASCurvatureRequest_ISig_4 65535;
BA_ "GenSigMaxLatency" SG_ 528 FASCurvatureRequest_ISig_4 25;
BA_ "GenSigCycleTime" SG_ 528 FASControlMode_ISig_4 100;
BA_ "GenSigCycleTimeActive" SG_ 528 FASControlMode_ISig_4 100;
BA_ "GenSigStartValue" SG_ 528 FASControlMode_ISig_4 15;
BA_ "GenSigMaxLatency" SG_ 528 FASControlMode_ISig_4 25;
BA_ "GenSigCycleTime" SG_ 528 FASExtCtrlMsgChecksum_ISig_4 100;
BA_ "GenSigCycleTimeActive" SG_ 528 FASExtCtrlMsgChecksum_ISig_4 100;
BA_ "GenSigMaxLatency" SG_ 528 FASExtCtrlMsgChecksum_ISig_4 25;
BA_ "GenSigCycleTime" SG_ 528 ReferencePathCurvature_ISig_4 100;
BA_ "GenSigCycleTimeActive" SG_ 528 ReferencePathCurvature_ISig_4 100;
BA_ "GenSigStartValue" SG_ 528 ReferencePathCurvature_ISig_4 65535;
BA_ "GenSigMaxLatency" SG_ 528 ReferencePathCurvature_ISig_4 25;
BA_ "GenSigCycleTime" SG_ 528 FASExtCtrlMsgCounter_ISig_4 100;
BA_ "GenSigCycleTimeActive" SG_ 528 FASExtCtrlMsgCounter_ISig_4 100;
BA_ "GenSigMaxLatency" SG_ 528 FASExtCtrlMsgCounter_ISig_4 25;
BA_ "GenSigCycleTime" SG_ 528 FASRoadWheelAngleRequest_ISig_4 100;
BA_ "GenSigCycleTimeActive" SG_ 528 FASRoadWheelAngleRequest_ISig_4 100;
BA_ "GenSigStartValue" SG_ 528 FASRoadWheelAngleRequest_ISig_4 65535;
BA_ "GenSigMaxLatency" SG_ 528 FASRoadWheelAngleRequest_ISig_4 25;
BA_ "GenSigCycleTime" SG_ 524 TSAMIntervntionCapabilityLeft 100;
BA_ "GenSigCycleTimeActive" SG_ 524 TSAMIntervntionCapabilityLeft 100;
BA_ "GenSigStartValue" SG_ 524 TSAMIntervntionCapabilityLeft 3;
BA_ "GenSigCycleTime" SG_ 524 TSAMIntervntionCapabilityRight 100;
BA_ "GenSigCycleTimeActive" SG_ 524 TSAMIntervntionCapabilityRight 100;
BA_ "GenSigStartValue" SG_ 524 TSAMIntervntionCapabilityRight 3;
BA_ "GenSigCycleTime" SG_ 524 GlareFreeArea02_LeftAngle_ISig_4 100;
BA_ "GenSigCycleTimeActive" SG_ 524 GlareFreeArea02_LeftAngle_ISig_4 100;
BA_ "GenSigStartValue" SG_ 524 GlareFreeArea02_LeftAngle_ISig_4 2047;
BA_ "GenSigMaxLatency" SG_ 524 GlareFreeArea02_LeftAngle_ISig_4 26;
BA_ "Platform_VMCU1_Sig" SG_ 524 GlareFreeArea02_LeftAngle_ISig_4 1;
BA_ "GenSigCycleTime" SG_ 524 GlareFreeArea02_RightAngle_ISig_ 100;
BA_ "GenSigCycleTimeActive" SG_ 524 GlareFreeArea02_RightAngle_ISig_ 100;
BA_ "GenSigStartValue" SG_ 524 GlareFreeArea02_RightAngle_ISig_ 2047;
BA_ "GenSigMaxLatency" SG_ 524 GlareFreeArea02_RightAngle_ISig_ 26;
BA_ "Platform_VMCU1_Sig" SG_ 524 GlareFreeArea02_RightAngle_ISig_ 1;
BA_ "SystemSignalLongSymbol" SG_ 524 GlareFreeArea02_RightAngle_ISig_ "GlareFreeArea02_RightAngle_ISig_4";
BA_ "GenSigCycleTime" SG_ 524 PathDeviationSteeringStatus 100;
BA_ "GenSigCycleTimeActive" SG_ 524 PathDeviationSteeringStatus 100;
BA_ "GenSigStartValue" SG_ 524 PathDeviationSteeringStatus 7;
BA_ "GenSigCycleTime" SG_ 524 GlareFreeArea02_Distance_ISig_4 100;
BA_ "GenSigCycleTimeActive" SG_ 524 GlareFreeArea02_Distance_ISig_4 100;
BA_ "GenSigStartValue" SG_ 524 GlareFreeArea02_Distance_ISig_4 1023;
BA_ "GenSigMaxLatency" SG_ 524 GlareFreeArea02_Distance_ISig_4 26;
BA_ "Platform_VMCU1_Sig" SG_ 524 GlareFreeArea02_Distance_ISig_4 1;
BA_ "GenSigCycleTime" SG_ 522 GlareFreeArea01_LeftAngle_ISig_4 100;
BA_ "GenSigCycleTimeActive" SG_ 522 GlareFreeArea01_LeftAngle_ISig_4 100;
BA_ "GenSigStartValue" SG_ 522 GlareFreeArea01_LeftAngle_ISig_4 2047;
BA_ "GenSigMaxLatency" SG_ 522 GlareFreeArea01_LeftAngle_ISig_4 25;
BA_ "Platform_VMCU1_Sig" SG_ 522 GlareFreeArea01_LeftAngle_ISig_4 1;
BA_ "GenSigCycleTime" SG_ 522 GlareFreeArea03_Distance_ISig_4 100;
BA_ "GenSigCycleTimeActive" SG_ 522 GlareFreeArea03_Distance_ISig_4 100;
BA_ "GenSigStartValue" SG_ 522 GlareFreeArea03_Distance_ISig_4 1023;
BA_ "GenSigMaxLatency" SG_ 522 GlareFreeArea03_Distance_ISig_4 25;
BA_ "Platform_VMCU1_Sig" SG_ 522 GlareFreeArea03_Distance_ISig_4 1;
BA_ "GenSigCycleTime" SG_ 522 GlareFreeArea03_LeftAngle_ISig_4 100;
BA_ "GenSigCycleTimeActive" SG_ 522 GlareFreeArea03_LeftAngle_ISig_4 100;
BA_ "GenSigStartValue" SG_ 522 GlareFreeArea03_LeftAngle_ISig_4 2047;
BA_ "GenSigMaxLatency" SG_ 522 GlareFreeArea03_LeftAngle_ISig_4 25;
BA_ "Platform_VMCU1_Sig" SG_ 522 GlareFreeArea03_LeftAngle_ISig_4 1;
BA_ "GenSigCycleTime" SG_ 522 GlareFreeArea03_RightAngle_ISig_ 100;
BA_ "GenSigCycleTimeActive" SG_ 522 GlareFreeArea03_RightAngle_ISig_ 100;
BA_ "GenSigStartValue" SG_ 522 GlareFreeArea03_RightAngle_ISig_ 2047;
BA_ "GenSigMaxLatency" SG_ 522 GlareFreeArea03_RightAngle_ISig_ 25;
BA_ "Platform_VMCU1_Sig" SG_ 522 GlareFreeArea03_RightAngle_ISig_ 1;
BA_ "SystemSignalLongSymbol" SG_ 522 GlareFreeArea03_RightAngle_ISig_ "GlareFreeArea03_RightAngle_ISig_4";
BA_ "GenSigCycleTime" SG_ 522 GlareFreeArea01_Distance_ISig_4 100;
BA_ "GenSigCycleTimeActive" SG_ 522 GlareFreeArea01_Distance_ISig_4 100;
BA_ "GenSigStartValue" SG_ 522 GlareFreeArea01_Distance_ISig_4 1023;
BA_ "GenSigMaxLatency" SG_ 522 GlareFreeArea01_Distance_ISig_4 25;
BA_ "Platform_VMCU1_Sig" SG_ 522 GlareFreeArea01_Distance_ISig_4 1;
BA_ "GenSigCycleTime" SG_ 522 GlareFreeArea01_RightAngle_ISig_ 100;
BA_ "GenSigCycleTimeActive" SG_ 522 GlareFreeArea01_RightAngle_ISig_ 100;
BA_ "GenSigStartValue" SG_ 522 GlareFreeArea01_RightAngle_ISig_ 2047;
BA_ "GenSigMaxLatency" SG_ 522 GlareFreeArea01_RightAngle_ISig_ 25;
BA_ "Platform_VMCU1_Sig" SG_ 522 GlareFreeArea01_RightAngle_ISig_ 1;
BA_ "SystemSignalLongSymbol" SG_ 522 GlareFreeArea01_RightAngle_ISig_ "GlareFreeArea01_RightAngle_ISig_4";
BA_ "GenSigCycleTime" SG_ 946 PSC_RequestedPresetSpeed 100;
BA_ "GenSigCycleTimeActive" SG_ 946 PSC_RequestedPresetSpeed 100;
BA_ "GenSigStartValue" SG_ 946 PSC_RequestedPresetSpeed 65535;
BA_ "GenSigCycleTime" SG_ 946 CACCStatus 100;
BA_ "GenSigCycleTimeActive" SG_ 946 CACCStatus 100;
BA_ "GenSigStartValue" SG_ 946 CACCStatus 7;
BA_ "GenSigCycleTime" SG_ 946 PSC_DriverBrakingAllowed 100;
BA_ "GenSigCycleTimeActive" SG_ 946 PSC_DriverBrakingAllowed 100;
BA_ "GenSigStartValue" SG_ 946 PSC_DriverBrakingAllowed 3;
BA_ "GenSigCycleTime" SG_ 946 TrafficSituationCriticality 100;
BA_ "GenSigCycleTimeActive" SG_ 946 TrafficSituationCriticality 100;
BA_ "GenSigStartValue" SG_ 946 TrafficSituationCriticality 7;
BA_ "GenSigCycleTime" SG_ 946 VisionLight_stat 100;
BA_ "GenSigCycleTimeActive" SG_ 946 VisionLight_stat 100;
BA_ "GenSigStartValue" SG_ 946 VisionLight_stat 7;
BA_ "Platform_VMCU1_Sig" SG_ 946 VisionLight_stat 1;
BA_ "GenSigCycleTime" SG_ 946 BBSteeringStatus 100;
BA_ "GenSigCycleTimeActive" SG_ 946 BBSteeringStatus 100;
BA_ "GenSigStartValue" SG_ 946 BBSteeringStatus 3;
BA_ "GenSigCycleTime" SG_ 946 PSC_SetSpeedChangeRqst 100;
BA_ "GenSigCycleTimeActive" SG_ 946 PSC_SetSpeedChangeRqst 100;
BA_ "GenSigStartValue" SG_ 946 PSC_SetSpeedChangeRqst 3;
BA_ "GenSigCycleTime" SG_ 946 ACCiSeeDistanceGap 100;
BA_ "GenSigCycleTimeActive" SG_ 946 ACCiSeeDistanceGap 100;
BA_ "GenSigStartValue" SG_ 946 ACCiSeeDistanceGap 255;
BA_ "Platform_VMCU1_Sig" SG_ 946 ACCiSeeDistanceGap 1;
BA_ "GenSigCycleTime" SG_ 946 LSMS_SpeedLimit 100;
BA_ "GenSigCycleTimeActive" SG_ 946 LSMS_SpeedLimit 100;
BA_ "GenSigStartValue" SG_ 946 LSMS_SpeedLimit 65535;
BA_ "GenSigCycleTime" SG_ 744 ForwardLookingCameraStatus_ISig_ 100;
BA_ "GenSigCycleTimeActive" SG_ 744 ForwardLookingCameraStatus_ISig_ 100;
BA_ "GenSigStartValue" SG_ 744 ForwardLookingCameraStatus_ISig_ 15;
BA_ "GenSigMaxLatency" SG_ 744 ForwardLookingCameraStatus_ISig_ 40;
BA_ "Platform_VMCU1_Sig" SG_ 744 ForwardLookingCameraStatus_ISig_ 1;
BA_ "SystemSignalLongSymbol" SG_ 744 ForwardLookingCameraStatus_ISig_ "ForwardLookingCameraStatus_ISig_4";
BA_ "GenSigCycleTime" SG_ 744 XARDACU_ControlMode 100;
BA_ "GenSigCycleTimeActive" SG_ 744 XARDACU_ControlMode 100;
BA_ "GenSigStartValue" SG_ 744 XARDACU_ControlMode 3;
BA_ "GenSigMaxLatency" SG_ 744 XARDACU_ControlMode 50;
BA_ "Platform_VMCU1_Sig" SG_ 744 XARDACU_ControlMode 1;
BA_ "SeToolAncestorID_SIGNAL" SG_ 744 XARDACU_ControlMode "x0000001D0425403E";
BA_ "SeToolItemID_SIGNAL" SG_ 744 XARDACU_ControlMode "x0000001D0425403E";
BA_ "SeToolName_SIGNAL" SG_ 744 XARDACU_ControlMode "ControlMode";
BA_ "SeToolOwnerSigGroupID_SIGNAL" SG_ 744 XARDACU_ControlMode "x0000001D043FB722";
BA_ "SeToolOwnerSigGroup_SIGNAL" SG_ 744 XARDACU_ControlMode "XARDACU";
BA_ "SeToolVersion_SIGNAL" SG_ 744 XARDACU_ControlMode "1";
BA_ "GenSigCycleTime" SG_ 744 ACCiRollInhibit 100;
BA_ "GenSigCycleTimeActive" SG_ 744 ACCiRollInhibit 100;
BA_ "GenSigStartValue" SG_ 744 ACCiRollInhibit 3;
BA_ "Platform_VMCU1_Sig" SG_ 744 ACCiRollInhibit 1;
BA_ "GenSigCycleTime" SG_ 744 CMReducedAbilityStatus 100;
BA_ "GenSigCycleTimeActive" SG_ 744 CMReducedAbilityStatus 100;
BA_ "GenSigStartValue" SG_ 744 CMReducedAbilityStatus 7;
BA_ "Platform_VMCU1_Sig" SG_ 744 CMReducedAbilityStatus 1;
BA_ "GenSigCycleTime" SG_ 744 CollisionSituationAliveAck 100;
BA_ "GenSigCycleTimeActive" SG_ 744 CollisionSituationAliveAck 100;
BA_ "GenSigStartValue" SG_ 744 CollisionSituationAliveAck 15;
BA_ "Platform_VMCU1_Sig" SG_ 744 CollisionSituationAliveAck 1;
BA_ "GenSigCycleTime" SG_ 744 ForwardLookingRadarStatus_ISig_4 100;
BA_ "GenSigCycleTimeActive" SG_ 744 ForwardLookingRadarStatus_ISig_4 100;
BA_ "GenSigStartValue" SG_ 744 ForwardLookingRadarStatus_ISig_4 15;
BA_ "GenSigMaxLatency" SG_ 744 ForwardLookingRadarStatus_ISig_4 40;
BA_ "Platform_VMCU1_Sig" SG_ 744 ForwardLookingRadarStatus_ISig_4 1;
BA_ "GenSigCycleTime" SG_ 744 XPRRequest_CM_ISig_4 100;
BA_ "GenSigCycleTimeActive" SG_ 744 XPRRequest_CM_ISig_4 100;
BA_ "GenSigStartValue" SG_ 744 XPRRequest_CM_ISig_4 255;
BA_ "Platform_VMCU1_Sig" SG_ 744 XPRRequest_CM_ISig_4 1;
BA_ "GenSigCycleTime" SG_ 744 LPOSBlocked 100;
BA_ "GenSigCycleTimeActive" SG_ 744 LPOSBlocked 100;
BA_ "GenSigStartValue" SG_ 744 LPOSBlocked 3;
BA_ "GenSigCycleTime" SG_ 744 XARDACU_AccelDemand 100;
BA_ "GenSigCycleTimeActive" SG_ 744 XARDACU_AccelDemand 100;
BA_ "GenSigStartValue" SG_ 744 XARDACU_AccelDemand 65535;
BA_ "GenSigMaxLatency" SG_ 744 XARDACU_AccelDemand 50;
BA_ "Platform_VMCU1_Sig" SG_ 744 XARDACU_AccelDemand 1;
BA_ "SeToolAncestorID_SIGNAL" SG_ 744 XARDACU_AccelDemand "x0000001D04254042";
BA_ "SeToolItemID_SIGNAL" SG_ 744 XARDACU_AccelDemand "x0000001D04254042";
BA_ "SeToolName_SIGNAL" SG_ 744 XARDACU_AccelDemand "AccelDemand";
BA_ "SeToolOwnerSigGroupID_SIGNAL" SG_ 744 XARDACU_AccelDemand "x0000001D043FB722";
BA_ "SeToolOwnerSigGroup_SIGNAL" SG_ 744 XARDACU_AccelDemand "XARDACU";
BA_ "SeToolVersion_SIGNAL" SG_ 744 XARDACU_AccelDemand "1";
BA_ "GenSigCycleTime" SG_ 744 CollSituationHazardLightReq 100;
BA_ "GenSigCycleTimeActive" SG_ 744 CollSituationHazardLightReq 100;
BA_ "GenSigStartValue" SG_ 744 CollSituationHazardLightReq 7;
BA_ "Platform_VMCU1_Sig" SG_ 744 CollSituationHazardLightReq 1;
BA_ "GenSigCycleTime" SG_ 560 PathDeviationDriverAlert 100;
BA_ "GenSigCycleTimeActive" SG_ 560 PathDeviationDriverAlert 100;
BA_ "GenSigStartValue" SG_ 560 PathDeviationDriverAlert 7;
BA_ "GenSigMaxLatency" SG_ 560 PathDeviationDriverAlert 48;
BA_ "Platform_VMCU1_Sig" SG_ 560 PathDeviationDriverAlert 1;
BA_ "SeToolAncestorID_SIGNAL" SG_ 560 PathDeviationDriverAlert "x0000001D04168B9E";
BA_ "SeToolItemID_SIGNAL" SG_ 560 PathDeviationDriverAlert "x0000001D043EF492";
BA_ "SeToolName_SIGNAL" SG_ 560 PathDeviationDriverAlert "LKSDepartureWarningStatus";
BA_ "SeToolVersion_SIGNAL" SG_ 560 PathDeviationDriverAlert "2";
BA_ "GenSigCycleTime" SG_ 560 CM_DisengageDrivelineRequest 100;
BA_ "GenSigCycleTimeActive" SG_ 560 CM_DisengageDrivelineRequest 100;
BA_ "GenSigStartValue" SG_ 560 CM_DisengageDrivelineRequest 3;
BA_ "GenSigMaxLatency" SG_ 560 CM_DisengageDrivelineRequest 48;
BA_ "Platform_VMCU1_Sig" SG_ 560 CM_DisengageDrivelineRequest 1;
BA_ "SeToolAncestorID_SIGNAL" SG_ 560 CM_DisengageDrivelineRequest "x0000001D0417E893";
BA_ "SeToolItemID_SIGNAL" SG_ 560 CM_DisengageDrivelineRequest "x0000001D0435A0FF";
BA_ "SeToolName_SIGNAL" SG_ 560 CM_DisengageDrivelineRequest "CM_DisengageDrivelineRequest";
BA_ "SeToolVersion_SIGNAL" SG_ 560 CM_DisengageDrivelineRequest "2";
BA_ "GenSigCycleTime" SG_ 560 ACCBrakeRequestStatus 100;
BA_ "GenSigCycleTimeActive" SG_ 560 ACCBrakeRequestStatus 100;
BA_ "GenSigStartValue" SG_ 560 ACCBrakeRequestStatus 3;
BA_ "GenSigMaxLatency" SG_ 560 ACCBrakeRequestStatus 48;
BA_ "Platform_VMCU1_Sig" SG_ 560 ACCBrakeRequestStatus 1;
BA_ "GenSigCycleTime" SG_ 560 FrontalCollisionDriverAlert_ISig 100;
BA_ "GenSigCycleTimeActive" SG_ 560 FrontalCollisionDriverAlert_ISig 100;
BA_ "GenSigStartValue" SG_ 560 FrontalCollisionDriverAlert_ISig 7;
BA_ "GenSigMaxLatency" SG_ 560 FrontalCollisionDriverAlert_ISig 48;
BA_ "Platform_VMCU1_Sig" SG_ 560 FrontalCollisionDriverAlert_ISig 1;
BA_ "SeToolAncestorID_SIGNAL" SG_ 560 FrontalCollisionDriverAlert_ISig "x0000001D0416642E";
BA_ "SeToolItemID_SIGNAL" SG_ 560 FrontalCollisionDriverAlert_ISig "x0000001D0428BE70";
BA_ "SeToolName_SIGNAL" SG_ 560 FrontalCollisionDriverAlert_ISig "FCW_Warning";
BA_ "SeToolVersion_SIGNAL" SG_ 560 FrontalCollisionDriverAlert_ISig "2";
BA_ "SystemSignalLongSymbol" SG_ 560 FrontalCollisionDriverAlert_ISig "FrontalCollisionDriverAlert_ISig_4";
BA_ "GenSigCycleTime" SG_ 560 ACC_SGOFaultCondStat_SeatBelt 100;
BA_ "GenSigCycleTimeActive" SG_ 560 ACC_SGOFaultCondStat_SeatBelt 100;
BA_ "Platform_VMCU1_Sig" SG_ 560 ACC_SGOFaultCondStat_SeatBelt 1;
BA_ "GenSigCycleTime" SG_ 560 CM_Status_ISig_4 100;
BA_ "GenSigCycleTimeActive" SG_ 560 CM_Status_ISig_4 100;
BA_ "GenSigStartValue" SG_ 560 CM_Status_ISig_4 7;
BA_ "GenSigMaxLatency" SG_ 560 CM_Status_ISig_4 48;
BA_ "Platform_VMCU1_Sig" SG_ 560 CM_Status_ISig_4 1;
BA_ "SeToolAncestorID_SIGNAL" SG_ 560 CM_Status_ISig_4 "x0000001D0417D4DA";
BA_ "SeToolItemID_SIGNAL" SG_ 560 CM_Status_ISig_4 "x0000001D0428BE35";
BA_ "SeToolName_SIGNAL" SG_ 560 CM_Status_ISig_4 "CM_Status";
BA_ "SeToolVersion_SIGNAL" SG_ 560 CM_Status_ISig_4 "2";
BA_ "GenSigCycleTime" SG_ 560 DASApplicationStatus_ISig_4 100;
BA_ "GenSigCycleTimeActive" SG_ 560 DASApplicationStatus_ISig_4 100;
BA_ "GenSigStartValue" SG_ 560 DASApplicationStatus_ISig_4 7;
BA_ "GenSigMaxLatency" SG_ 560 DASApplicationStatus_ISig_4 48;
BA_ "Platform_VMCU1_Sig" SG_ 560 DASApplicationStatus_ISig_4 1;
BA_ "SeToolAncestorID_SIGNAL" SG_ 560 DASApplicationStatus_ISig_4 "x0000001D04169A83";
BA_ "SeToolItemID_SIGNAL" SG_ 560 DASApplicationStatus_ISig_4 "x0000001D04253A46";
BA_ "SeToolName_SIGNAL" SG_ 560 DASApplicationStatus_ISig_4 "DASSystemStatus";
BA_ "SeToolVersion_SIGNAL" SG_ 560 DASApplicationStatus_ISig_4 "2";
BA_ "GenSigCycleTime" SG_ 560 ACC_Status 100;
BA_ "GenSigCycleTimeActive" SG_ 560 ACC_Status 100;
BA_ "GenSigStartValue" SG_ 560 ACC_Status 7;
BA_ "GenSigMaxLatency" SG_ 560 ACC_Status 48;
BA_ "Platform_VMCU1_Sig" SG_ 560 ACC_Status 1;
BA_ "SeToolAncestorID_SIGNAL" SG_ 560 ACC_Status "x0000001D041F8BDE";
BA_ "SeToolItemID_SIGNAL" SG_ 560 ACC_Status "x0000001D0427537B";
BA_ "SeToolName_SIGNAL" SG_ 560 ACC_Status "ACC_Status";
BA_ "SeToolVersion_SIGNAL" SG_ 560 ACC_Status "2";
BA_ "GenSigCycleTime" SG_ 560 LKSApplicationStatus_ISig_4 100;
BA_ "GenSigCycleTimeActive" SG_ 560 LKSApplicationStatus_ISig_4 100;
BA_ "GenSigStartValue" SG_ 560 LKSApplicationStatus_ISig_4 7;
BA_ "GenSigMaxLatency" SG_ 560 LKSApplicationStatus_ISig_4 48;
BA_ "Platform_VMCU1_Sig" SG_ 560 LKSApplicationStatus_ISig_4 1;
BA_ "SeToolAncestorID_SIGNAL" SG_ 560 LKSApplicationStatus_ISig_4 "x0000001D04168BAE";
BA_ "SeToolItemID_SIGNAL" SG_ 560 LKSApplicationStatus_ISig_4 "x0000001D043BCC5C";
BA_ "SeToolName_SIGNAL" SG_ 560 LKSApplicationStatus_ISig_4 "LKSStatus";
BA_ "SeToolVersion_SIGNAL" SG_ 560 LKSApplicationStatus_ISig_4 "3";
BA_ "GenSigCycleTime" SG_ 560 LCSSystemStatus 100;
BA_ "GenSigCycleTimeActive" SG_ 560 LCSSystemStatus 100;
BA_ "GenSigStartValue" SG_ 560 LCSSystemStatus 7;
BA_ "GenSigMaxLatency" SG_ 560 LCSSystemStatus 48;
BA_ "Platform_VMCU1_Sig" SG_ 560 LCSSystemStatus 1;
BA_ "SeToolAncestorID_SIGNAL" SG_ 560 LCSSystemStatus "x0000001D043A89E4";
BA_ "SeToolItemID_SIGNAL" SG_ 560 LCSSystemStatus "x0000001D043A89E4";
BA_ "SeToolName_SIGNAL" SG_ 560 LCSSystemStatus "LCSSystemStatus";
BA_ "SeToolVersion_SIGNAL" SG_ 560 LCSSystemStatus "1";
BA_ "GenSigCycleTime" SG_ 560 ACC_SGOFaultCondStat_SigStat 100;
BA_ "GenSigCycleTimeActive" SG_ 560 ACC_SGOFaultCondStat_SigStat 100;
BA_ "Platform_VMCU1_Sig" SG_ 560 ACC_SGOFaultCondStat_SigStat 1;
BA_ "GenSigCycleTime" SG_ 560 ACC_SGOFaultCondStat_Target 100;
BA_ "GenSigCycleTimeActive" SG_ 560 ACC_SGOFaultCondStat_Target 100;
BA_ "Platform_VMCU1_Sig" SG_ 560 ACC_SGOFaultCondStat_Target 1;
BA_ "GenSigCycleTime" SG_ 560 FCW_Status 100;
BA_ "GenSigCycleTimeActive" SG_ 560 FCW_Status 100;
BA_ "GenSigStartValue" SG_ 560 FCW_Status 3;
BA_ "GenSigMaxLatency" SG_ 560 FCW_Status 48;
BA_ "Platform_VMCU1_Sig" SG_ 560 FCW_Status 1;
BA_ "SeToolAncestorID_SIGNAL" SG_ 560 FCW_Status "x0000001D04166451";
BA_ "SeToolItemID_SIGNAL" SG_ 560 FCW_Status "x0000001D04166451";
BA_ "SeToolName_SIGNAL" SG_ 560 FCW_Status "FCW_Status";
BA_ "SeToolVersion_SIGNAL" SG_ 560 FCW_Status "1";
BA_ "GenSigCycleTime" SG_ 560 DriverImpairedDriverAlert_ISig_4 100;
BA_ "GenSigCycleTimeActive" SG_ 560 DriverImpairedDriverAlert_ISig_4 100;
BA_ "GenSigStartValue" SG_ 560 DriverImpairedDriverAlert_ISig_4 7;
BA_ "GenSigMaxLatency" SG_ 560 DriverImpairedDriverAlert_ISig_4 48;
BA_ "Platform_VMCU1_Sig" SG_ 560 DriverImpairedDriverAlert_ISig_4 1;
BA_ "SeToolAncestorID_SIGNAL" SG_ 560 DriverImpairedDriverAlert_ISig_4 "x0000001D04169AB3";
BA_ "SeToolItemID_SIGNAL" SG_ 560 DriverImpairedDriverAlert_ISig_4 "x0000001D04169AB3";
BA_ "SeToolName_SIGNAL" SG_ 560 DriverImpairedDriverAlert_ISig_4 "DASImpairmentWarningStatus";
BA_ "SeToolVersion_SIGNAL" SG_ 560 DriverImpairedDriverAlert_ISig_4 "1";
BA_ "GenSigCycleTime" SG_ 560 DriverVigilanceLevel 100;
BA_ "GenSigCycleTimeActive" SG_ 560 DriverVigilanceLevel 100;
BA_ "GenSigStartValue" SG_ 560 DriverVigilanceLevel 7;
BA_ "GenSigMaxLatency" SG_ 560 DriverVigilanceLevel 48;
BA_ "Platform_VMCU1_Sig" SG_ 560 DriverVigilanceLevel 1;
BA_ "SeToolAncestorID_SIGNAL" SG_ 560 DriverVigilanceLevel "x0000001D04169ABA";
BA_ "SeToolItemID_SIGNAL" SG_ 560 DriverVigilanceLevel "x0000001D043EBF2F";
BA_ "SeToolName_SIGNAL" SG_ 560 DriverVigilanceLevel "DASVigilanceLevelStatus";
BA_ "SeToolVersion_SIGNAL" SG_ 560 DriverVigilanceLevel "2";
BA_ "GenSigCycleTime" SG_ 560 ACCForwardVehicleSpeed_ISig_4 100;
BA_ "GenSigCycleTimeActive" SG_ 560 ACCForwardVehicleSpeed_ISig_4 100;
BA_ "GenSigStartValue" SG_ 560 ACCForwardVehicleSpeed_ISig_4 255;
BA_ "GenSigMaxLatency" SG_ 560 ACCForwardVehicleSpeed_ISig_4 48;
BA_ "Platform_VMCU1_Sig" SG_ 560 ACCForwardVehicleSpeed_ISig_4 1;
BA_ "SeToolAncestorID_SIGNAL" SG_ 560 ACCForwardVehicleSpeed_ISig_4 "x0000001D04147192";
BA_ "SeToolItemID_SIGNAL" SG_ 560 ACCForwardVehicleSpeed_ISig_4 "x0000001D04147192";
BA_ "SeToolName_SIGNAL" SG_ 560 ACCForwardVehicleSpeed_ISig_4 "ACCForwardVehicleSpeed";
BA_ "SeToolVersion_SIGNAL" SG_ 560 ACCForwardVehicleSpeed_ISig_4 "1";
BA_ "GenSigCycleTime" SG_ 560 ACC_SGOFaultCondStat_Door 100;
BA_ "GenSigCycleTimeActive" SG_ 560 ACC_SGOFaultCondStat_Door 100;
BA_ "Platform_VMCU1_Sig" SG_ 560 ACC_SGOFaultCondStat_Door 1;
BA_ "GenSigCycleTime" SG_ 560 ACCTargetDetected 100;
BA_ "GenSigCycleTimeActive" SG_ 560 ACCTargetDetected 100;
BA_ "GenSigStartValue" SG_ 560 ACCTargetDetected 3;
BA_ "GenSigMaxLatency" SG_ 560 ACCTargetDetected 48;
BA_ "Platform_VMCU1_Sig" SG_ 560 ACCTargetDetected 1;
BA_ "SeToolAncestorID_SIGNAL" SG_ 560 ACCTargetDetected "x0000001D04146FC9";
BA_ "SeToolItemID_SIGNAL" SG_ 560 ACCTargetDetected "x0000001D04146FC9";
BA_ "SeToolName_SIGNAL" SG_ 560 ACCTargetDetected "ACCTargetDetected";
BA_ "SeToolVersion_SIGNAL" SG_ 560 ACCTargetDetected "1";
BA_ "GenSigCycleTime" SG_ 560 ACCForwardVehicleDistance_ISig_4 100;
BA_ "GenSigCycleTimeActive" SG_ 560 ACCForwardVehicleDistance_ISig_4 100;
BA_ "GenSigStartValue" SG_ 560 ACCForwardVehicleDistance_ISig_4 255;
BA_ "GenSigMaxLatency" SG_ 560 ACCForwardVehicleDistance_ISig_4 48;
BA_ "Platform_VMCU1_Sig" SG_ 560 ACCForwardVehicleDistance_ISig_4 1;
BA_ "SeToolAncestorID_SIGNAL" SG_ 560 ACCForwardVehicleDistance_ISig_4 "x0000001D04147189";
BA_ "SeToolItemID_SIGNAL" SG_ 560 ACCForwardVehicleDistance_ISig_4 "x0000001D04147189";
BA_ "SeToolName_SIGNAL" SG_ 560 ACCForwardVehicleDistance_ISig_4 "ACCForwardVehicleDistance";
BA_ "SeToolVersion_SIGNAL" SG_ 560 ACCForwardVehicleDistance_ISig_4 "1";
BA_ "GenSigCycleTime" SG_ 560 LKSCorrectiveSteeringStatus 100;
BA_ "GenSigCycleTimeActive" SG_ 560 LKSCorrectiveSteeringStatus 100;
BA_ "GenSigStartValue" SG_ 560 LKSCorrectiveSteeringStatus 7;
BA_ "GenSigMaxLatency" SG_ 560 LKSCorrectiveSteeringStatus 48;
BA_ "GenSigCycleTime" SG_ 560 ACC_SGOFaultCondStat_Other 100;
BA_ "GenSigCycleTimeActive" SG_ 560 ACC_SGOFaultCondStat_Other 100;
BA_ "Platform_VMCU1_Sig" SG_ 560 ACC_SGOFaultCondStat_Other 1;
BA_ "GenSigCycleTime" SG_ 560 LCSSoundSettingStatus 100;
BA_ "GenSigCycleTimeActive" SG_ 560 LCSSoundSettingStatus 100;
BA_ "GenSigStartValue" SG_ 560 LCSSoundSettingStatus 3;
BA_ "Platform_VMCU1_Sig" SG_ 560 LCSSoundSettingStatus 1;
BA_ "GenSigCycleTime" SG_ 560 ACC_SGOFaultCondStat_Speed 100;
BA_ "GenSigCycleTimeActive" SG_ 560 ACC_SGOFaultCondStat_Speed 100;
BA_ "Platform_VMCU1_Sig" SG_ 560 ACC_SGOFaultCondStat_Speed 1;
BA_ "GenSigCycleTime" SG_ 1460 ESSFnRqst_FnNum_ISig_4 100;
BA_ "GenSigCycleTimeActive" SG_ 1460 ESSFnRqst_FnNum_ISig_4 100;
BA_ "GenSigStartValue" SG_ 1460 ESSFnRqst_FnNum_ISig_4 15;
BA_ "GenSigCycleTime" SG_ 1460 ESSFnRqst_FnPower_ISig_4 100;
BA_ "GenSigCycleTimeActive" SG_ 1460 ESSFnRqst_FnPower_ISig_4 100;
BA_ "GenSigStartValue" SG_ 1460 ESSFnRqst_FnPower_ISig_4 255;
BA_ "GenSigCycleTime" SG_ 1460 ChlrVlvPsnRqst_ISig_4 100;
BA_ "GenSigCycleTimeActive" SG_ 1460 ChlrVlvPsnRqst_ISig_4 100;
BA_ "GenSigStartValue" SG_ 1460 ChlrVlvPsnRqst_ISig_4 255;
BA_ "GenSigSendType" SG_ 936 CIOM_BB2_32S_FCS 7;
BA_ "GenSigSendType" SG_ 935 EncryptedGBUnlockAuth_stat 1;
BA_ "GenSigMaxLatency" SG_ 935 EncryptedGBUnlockAuth_stat 1000;
BA_ "GenSigSendType" SG_ 1369 ParkClimTimerStat_Tue_ISig_4 1;
BA_ "NeedsUpdateBit" SG_ 1369 ParkClimTimerStat_Tue_ISig_4 1;
BA_ "GenSigSendType" SG_ 1369 ParkClimTimerStat_Mon_ISig_4 1;
BA_ "NeedsUpdateBit" SG_ 1369 ParkClimTimerStat_Mon_ISig_4 1;
BA_ "GenSigSendType" SG_ 1369 ParkClimTimerStat_Hrs_ISig_4 1;
BA_ "GenSigStartValue" SG_ 1369 ParkClimTimerStat_Hrs_ISig_4 255;
BA_ "NeedsUpdateBit" SG_ 1369 ParkClimTimerStat_Hrs_ISig_4 1;
BA_ "GenSigSendType" SG_ 1369 ParkClimTimerStat_TotalNoTimers_ 1;
BA_ "GenSigStartValue" SG_ 1369 ParkClimTimerStat_TotalNoTimers_ 255;
BA_ "NeedsUpdateBit" SG_ 1369 ParkClimTimerStat_TotalNoTimers_ 1;
BA_ "SystemSignalLongSymbol" SG_ 1369 ParkClimTimerStat_TotalNoTimers_ "ParkClimTimerStat_TotalNoTimers_ISig_4";
BA_ "GenSigSendType" SG_ 1369 ParkClimTimerStat_Thu_ISig_4 1;
BA_ "NeedsUpdateBit" SG_ 1369 ParkClimTimerStat_Thu_ISig_4 1;
BA_ "GenSigSendType" SG_ 1369 ParkClimTimerStat_MinRes_ISig_4 1;
BA_ "GenSigStartValue" SG_ 1369 ParkClimTimerStat_MinRes_ISig_4 7;
BA_ "NeedsUpdateBit" SG_ 1369 ParkClimTimerStat_MinRes_ISig_4 1;
BA_ "GenSigSendType" SG_ 1369 ParkClimTimerStat_Status_ISig_4 1;
BA_ "GenSigStartValue" SG_ 1369 ParkClimTimerStat_Status_ISig_4 3;
BA_ "NeedsUpdateBit" SG_ 1369 ParkClimTimerStat_Status_ISig_4 1;
BA_ "GenSigSendType" SG_ 1369 ParkClimTimerStat_Sun_ISig_4 1;
BA_ "NeedsUpdateBit" SG_ 1369 ParkClimTimerStat_Sun_ISig_4 1;
BA_ "GenSigSendType" SG_ 1369 ParkClimTimerStat_sg_UB_ISig_4 7;
BA_ "GenSigSendType" SG_ 1369 ParkClimTimerStat_TimerNr_ISig_4 1;
BA_ "GenSigStartValue" SG_ 1369 ParkClimTimerStat_TimerNr_ISig_4 255;
BA_ "NeedsUpdateBit" SG_ 1369 ParkClimTimerStat_TimerNr_ISig_4 1;
BA_ "GenSigSendType" SG_ 1369 ParkClimTimerStat_Rec_ISig_4 1;
BA_ "NeedsUpdateBit" SG_ 1369 ParkClimTimerStat_Rec_ISig_4 1;
BA_ "GenSigSendType" SG_ 1369 ParkClimTimerStat_Wed_ISig_4 1;
BA_ "NeedsUpdateBit" SG_ 1369 ParkClimTimerStat_Wed_ISig_4 1;
BA_ "GenSigSendType" SG_ 1369 ParkClimTimerStat_Min_ISig_4 1;
BA_ "GenSigStartValue" SG_ 1369 ParkClimTimerStat_Min_ISig_4 255;
BA_ "NeedsUpdateBit" SG_ 1369 ParkClimTimerStat_Min_ISig_4 1;
BA_ "GenSigSendType" SG_ 1369 ParkClimTimerStat_Type_ISig_4 1;
BA_ "GenSigStartValue" SG_ 1369 ParkClimTimerStat_Type_ISig_4 7;
BA_ "NeedsUpdateBit" SG_ 1369 ParkClimTimerStat_Type_ISig_4 1;
BA_ "GenSigSendType" SG_ 1369 ParkClimTimerStat_Sat_ISig_4 1;
BA_ "NeedsUpdateBit" SG_ 1369 ParkClimTimerStat_Sat_ISig_4 1;
BA_ "GenSigSendType" SG_ 1369 ParkClimTimerStat_Temp_ISig_4 1;
BA_ "GenSigStartValue" SG_ 1369 ParkClimTimerStat_Temp_ISig_4 255;
BA_ "NeedsUpdateBit" SG_ 1369 ParkClimTimerStat_Temp_ISig_4 1;
BA_ "GenSigSendType" SG_ 1369 ParkClimTimerStat_Dur_ISig_4 1;
BA_ "GenSigStartValue" SG_ 1369 ParkClimTimerStat_Dur_ISig_4 127;
BA_ "NeedsUpdateBit" SG_ 1369 ParkClimTimerStat_Dur_ISig_4 1;
BA_ "GenSigSendType" SG_ 1369 ParkClimTimerStat_Fri_ISig_4 1;
BA_ "NeedsUpdateBit" SG_ 1369 ParkClimTimerStat_Fri_ISig_4 1;
BA_ "GenSigCycleTime" SG_ 551 BunkH1Next_ButtonStatus_ISig_4 100;
BA_ "GenSigCycleTimeActive" SG_ 551 BunkH1Next_ButtonStatus_ISig_4 100;
BA_ "GenSigStartValue" SG_ 551 BunkH1Next_ButtonStatus_ISig_4 3;
BA_ "GenSigCycleTime" SG_ 551 BunkH1AudioOnOff_ButtonStatus_IS 100;
BA_ "GenSigCycleTimeActive" SG_ 551 BunkH1AudioOnOff_ButtonStatus_IS 100;
BA_ "GenSigStartValue" SG_ 551 BunkH1AudioOnOff_ButtonStatus_IS 3;
BA_ "SystemSignalLongSymbol" SG_ 551 BunkH1AudioOnOff_ButtonStatus_IS "BunkH1AudioOnOff_ButtonStatus_ISig_4";
BA_ "GenSigCycleTime" SG_ 551 BunkH1AudioSource_rqst_ISig_4 100;
BA_ "GenSigCycleTimeActive" SG_ 551 BunkH1AudioSource_rqst_ISig_4 100;
BA_ "GenSigStartValue" SG_ 551 BunkH1AudioSource_rqst_ISig_4 7;
BA_ "GenSigCycleTime" SG_ 551 BunkH1VolumeUp_ButtonStatus_ISig 100;
BA_ "GenSigCycleTimeActive" SG_ 551 BunkH1VolumeUp_ButtonStatus_ISig 100;
BA_ "GenSigStartValue" SG_ 551 BunkH1VolumeUp_ButtonStatus_ISig 3;
BA_ "SystemSignalLongSymbol" SG_ 551 BunkH1VolumeUp_ButtonStatus_ISig "BunkH1VolumeUp_ButtonStatus_ISig_4";
BA_ "GenSigCycleTime" SG_ 551 BunkH1VolumeDown_ButtonStatus_IS 100;
BA_ "GenSigCycleTimeActive" SG_ 551 BunkH1VolumeDown_ButtonStatus_IS 100;
BA_ "GenSigStartValue" SG_ 551 BunkH1VolumeDown_ButtonStatus_IS 3;
BA_ "SystemSignalLongSymbol" SG_ 551 BunkH1VolumeDown_ButtonStatus_IS "BunkH1VolumeDown_ButtonStatus_ISig_4";
BA_ "GenSigCycleTime" SG_ 551 BunkH1AudioSource_rqst2_ISig_4 100;
BA_ "GenSigCycleTimeActive" SG_ 551 BunkH1AudioSource_rqst2_ISig_4 100;
BA_ "GenSigStartValue" SG_ 551 BunkH1AudioSource_rqst2_ISig_4 15;
BA_ "GenSigCycleTime" SG_ 551 BunkH1Mute_ButtonStatus_ISig_4 100;
BA_ "GenSigCycleTimeActive" SG_ 551 BunkH1Mute_ButtonStatus_ISig_4 100;
BA_ "GenSigStartValue" SG_ 551 BunkH1Mute_ButtonStatus_ISig_4 3;
BA_ "GenSigCycleTime" SG_ 551 BunkH1Prev_ButtonStatus_ISig_4 100;
BA_ "GenSigCycleTimeActive" SG_ 551 BunkH1Prev_ButtonStatus_ISig_4 100;
BA_ "GenSigStartValue" SG_ 551 BunkH1Prev_ButtonStatus_ISig_4 3;
BA_ "GenSigCycleTime" SG_ 551 AutoBlowerLevel_Status_ISig_4 100;
BA_ "GenSigCycleTimeActive" SG_ 551 AutoBlowerLevel_Status_ISig_4 100;
BA_ "GenSigStartValue" SG_ 551 AutoBlowerLevel_Status_ISig_4 7;
BA_ "GenSigCycleTime" SG_ 551 AutoDefogmode_Status_ISig_4 100;
BA_ "GenSigCycleTimeActive" SG_ 551 AutoDefogmode_Status_ISig_4 100;
BA_ "GenSigStartValue" SG_ 551 AutoDefogmode_Status_ISig_4 7;
BA_ "GenSigCycleTime" SG_ 551 AQSmode_Status_ISig_4 100;
BA_ "GenSigCycleTimeActive" SG_ 551 AQSmode_Status_ISig_4 100;
BA_ "GenSigStartValue" SG_ 551 AQSmode_Status_ISig_4 3;
BA_ "GenSigCycleTime" SG_ 551 ACmode_Status_ISig_4 100;
BA_ "GenSigCycleTimeActive" SG_ 551 ACmode_Status_ISig_4 100;
BA_ "GenSigStartValue" SG_ 551 ACmode_Status_ISig_4 7;
BA_ "GenSigCycleTime" SG_ 550 LKSCSEnableSwitch_rqst 100;
BA_ "GenSigCycleTimeActive" SG_ 550 LKSCSEnableSwitch_rqst 100;
BA_ "GenSigStartValue" SG_ 550 LKSCSEnableSwitch_rqst 3;
BA_ "GenSigMaxLatency" SG_ 550 LKSCSEnableSwitch_rqst 48;
BA_ "GenSigCycleTime" SG_ 1371 SRSWarningLamp_ISig_4 100;
BA_ "GenSigCycleTimeActive" SG_ 1371 SRSWarningLamp_ISig_4 100;
BA_ "GenSigStartValue" SG_ 1371 SRSWarningLamp_ISig_4 3;
BA_ "GenSigCycleTime" SG_ 1371 EvChargingConnectorUnlock_rqst 100;
BA_ "GenSigCycleTimeActive" SG_ 1371 EvChargingConnectorUnlock_rqst 100;
BA_ "GenSigStartValue" SG_ 1371 EvChargingConnectorUnlock_rqst 3;
BA_ "GenSigCycleTime" SG_ 1371 TrafficAccidentHazardLightRqst_I 100;
BA_ "GenSigCycleTimeActive" SG_ 1371 TrafficAccidentHazardLightRqst_I 100;
BA_ "GenSigStartValue" SG_ 1371 TrafficAccidentHazardLightRqst_I 3;
BA_ "SystemSignalLongSymbol" SG_ 1371 TrafficAccidentHazardLightRqst_I "TrafficAccidentHazardLightRqst_ISig_4";
BA_ "GenSigCycleTime" SG_ 1371 TrafficAccidentHzdActvRqst_SqC_I 100;
BA_ "GenSigCycleTimeActive" SG_ 1371 TrafficAccidentHzdActvRqst_SqC_I 100;
BA_ "GenSigStartValue" SG_ 1371 TrafficAccidentHzdActvRqst_SqC_I 15;
BA_ "SystemSignalLongSymbol" SG_ 1371 TrafficAccidentHzdActvRqst_SqC_I "TrafficAccidentHzdActvRqst_SqC_ISig_4";
BA_ "GenSigCycleTime" SG_ 1371 PHCleanStatFeedback_ISig_4 100;
BA_ "GenSigCycleTimeActive" SG_ 1371 PHCleanStatFeedback_ISig_4 100;
BA_ "GenSigStartValue" SG_ 1371 PHCleanStatFeedback_ISig_4 3;
BA_ "GenSigCycleTime" SG_ 1371 SRSWarningLamp_CRC_ISig_4 100;
BA_ "GenSigCycleTimeActive" SG_ 1371 SRSWarningLamp_CRC_ISig_4 100;
BA_ "GenSigStartValue" SG_ 1371 SRSWarningLamp_CRC_ISig_4 255;
BA_ "GenSigCycleTime" SG_ 1371 GearboxUnlockAuth_stat 100;
BA_ "GenSigCycleTimeActive" SG_ 1371 GearboxUnlockAuth_stat 100;
BA_ "GenSigStartValue" SG_ 1371 GearboxUnlockAuth_stat 7;
BA_ "GenSigCycleTime" SG_ 1371 TemperatureRqstIndication_cmd_IS 100;
BA_ "GenSigCycleTimeActive" SG_ 1371 TemperatureRqstIndication_cmd_IS 100;
BA_ "GenSigStartValue" SG_ 1371 TemperatureRqstIndication_cmd_IS 31;
BA_ "SeToolAncestorID_SIGNAL" SG_ 1371 TemperatureRqstIndication_cmd_IS "x0000001D04150607";
BA_ "SeToolItemID_SIGNAL" SG_ 1371 TemperatureRqstIndication_cmd_IS "x0000001D043FAF4A";
BA_ "SeToolName_SIGNAL" SG_ 1371 TemperatureRqstIndication_cmd_IS "TemperatureRqstIndication_cmd ";
BA_ "SeToolVersion_SIGNAL" SG_ 1371 TemperatureRqstIndication_cmd_IS "4";
BA_ "SystemSignalLongSymbol" SG_ 1371 TemperatureRqstIndication_cmd_IS "TemperatureRqstIndication_cmd_ISig_4";
BA_ "GenSigCycleTime" SG_ 1371 TrafficAccidentHzdActvRqst_CRC_I 100;
BA_ "GenSigCycleTimeActive" SG_ 1371 TrafficAccidentHzdActvRqst_CRC_I 100;
BA_ "GenSigStartValue" SG_ 1371 TrafficAccidentHzdActvRqst_CRC_I 255;
BA_ "SystemSignalLongSymbol" SG_ 1371 TrafficAccidentHzdActvRqst_CRC_I "TrafficAccidentHzdActvRqst_CRC_ISig_4";
BA_ "GenSigCycleTime" SG_ 1371 SRSWarningLamp_SqC_ISig_4 100;
BA_ "GenSigCycleTimeActive" SG_ 1371 SRSWarningLamp_SqC_ISig_4 100;
BA_ "GenSigStartValue" SG_ 1371 SRSWarningLamp_SqC_ISig_4 15;
BA_ "GenSigCycleTime" SG_ 1371 PassengersSeatBelt_ISig_4 100;
BA_ "GenSigCycleTimeActive" SG_ 1371 PassengersSeatBelt_ISig_4 100;
BA_ "GenSigStartValue" SG_ 1371 PassengersSeatBelt_ISig_4 7;
BA_ "GenSigSendType" SG_ 922 MediaSourcesListReq_SInfo_ISig_4 1;
BA_ "GenSigStartValue" SG_ 922 MediaSourcesListReq_SInfo_ISig_4 3;
BA_ "GenSigMaxLatency" SG_ 922 MediaSourcesListReq_SInfo_ISig_4 50;
BA_ "NeedsUpdateBit" SG_ 922 MediaSourcesListReq_SInfo_ISig_4 1;
BA_ "Platform_VMCU1_Sig" SG_ 922 MediaSourcesListReq_SInfo_ISig_4 1;
BA_ "GenSigSendType" SG_ 922 MediaSourcesListReq_Items_ISig_4 1;
BA_ "GenSigMaxLatency" SG_ 922 MediaSourcesListReq_Items_ISig_4 50;
BA_ "NeedsUpdateBit" SG_ 922 MediaSourcesListReq_Items_ISig_4 1;
BA_ "Platform_VMCU1_Sig" SG_ 922 MediaSourcesListReq_Items_ISig_4 1;
BA_ "GenSigSendType" SG_ 922 MediaSourcesListReq_sg_UB_ISig_4 7;
BA_ "Platform_VMCU1_Sig" SG_ 922 MediaSourcesListReq_sg_UB_ISig_4 1;
BA_ "GenSigSendType" SG_ 922 MediaSourcesListReq_ItemID_ISig_ 1;
BA_ "GenSigMaxLatency" SG_ 922 MediaSourcesListReq_ItemID_ISig_ 50;
BA_ "NeedsUpdateBit" SG_ 922 MediaSourcesListReq_ItemID_ISig_ 1;
BA_ "Platform_VMCU1_Sig" SG_ 922 MediaSourcesListReq_ItemID_ISig_ 1;
BA_ "SystemSignalLongSymbol" SG_ 922 MediaSourcesListReq_ItemID_ISig_ "MediaSourcesListReq_ItemID_ISig_4";
BA_ "GenSigSendType" SG_ 964 AlmClkSetAlm_LECM_rq_Type_ISig_4 1;
BA_ "GenSigStartValue" SG_ 964 AlmClkSetAlm_LECM_rq_Type_ISig_4 7;
BA_ "GenSigMaxLatency" SG_ 964 AlmClkSetAlm_LECM_rq_Type_ISig_4 126;
BA_ "Platform_VMCU1_Sig" SG_ 964 AlmClkSetAlm_LECM_rq_Type_ISig_4 1;
BA_ "GenSigSendType" SG_ 964 AlmClkSetAlm_LECM_rq_ID_ISig_4 1;
BA_ "GenSigStartValue" SG_ 964 AlmClkSetAlm_LECM_rq_ID_ISig_4 127;
BA_ "GenSigMaxLatency" SG_ 964 AlmClkSetAlm_LECM_rq_ID_ISig_4 126;
BA_ "Platform_VMCU1_Sig" SG_ 964 AlmClkSetAlm_LECM_rq_ID_ISig_4 1;
BA_ "GenSigSendType" SG_ 964 AlmClkSetAlm_LECM_rq_SetHr_ISig_ 1;
BA_ "GenSigStartValue" SG_ 964 AlmClkSetAlm_LECM_rq_SetHr_ISig_ 31;
BA_ "GenSigMaxLatency" SG_ 964 AlmClkSetAlm_LECM_rq_SetHr_ISig_ 126;
BA_ "Platform_VMCU1_Sig" SG_ 964 AlmClkSetAlm_LECM_rq_SetHr_ISig_ 1;
BA_ "SystemSignalLongSymbol" SG_ 964 AlmClkSetAlm_LECM_rq_SetHr_ISig_ "AlmClkSetAlm_LECM_rq_SetHr_ISig_4";
BA_ "GenSigSendType" SG_ 964 AlmClkSetAlm_LECM_rq_Stat_ISig_4 1;
BA_ "GenSigMaxLatency" SG_ 964 AlmClkSetAlm_LECM_rq_Stat_ISig_4 126;
BA_ "Platform_VMCU1_Sig" SG_ 964 AlmClkSetAlm_LECM_rq_Stat_ISig_4 1;
BA_ "GenSigSendType" SG_ 964 AlmClkSetAlm_LECM_rq_SetMin_ISig 1;
BA_ "GenSigStartValue" SG_ 964 AlmClkSetAlm_LECM_rq_SetMin_ISig 63;
BA_ "GenSigMaxLatency" SG_ 964 AlmClkSetAlm_LECM_rq_SetMin_ISig 126;
BA_ "Platform_VMCU1_Sig" SG_ 964 AlmClkSetAlm_LECM_rq_SetMin_ISig 1;
BA_ "SystemSignalLongSymbol" SG_ 964 AlmClkSetAlm_LECM_rq_SetMin_ISig "AlmClkSetAlm_LECM_rq_SetMin_ISig_4";
BA_ "GenSigSendType" SG_ 964 AlmClkSetAlm_LECM_rq_DaySet_ISig 1;
BA_ "GenSigMaxLatency" SG_ 964 AlmClkSetAlm_LECM_rq_DaySet_ISig 126;
BA_ "Platform_VMCU1_Sig" SG_ 964 AlmClkSetAlm_LECM_rq_DaySet_ISig 1;
BA_ "SystemSignalLongSymbol" SG_ 964 AlmClkSetAlm_LECM_rq_DaySet_ISig "AlmClkSetAlm_LECM_rq_DaySet_ISig_4";
BA_ "GenSigSendType" SG_ 964 AlmClkSetAlm_LECM_rq_Mode_ISig_4 1;
BA_ "GenSigMaxLatency" SG_ 964 AlmClkSetAlm_LECM_rq_Mode_ISig_4 126;
BA_ "Platform_VMCU1_Sig" SG_ 964 AlmClkSetAlm_LECM_rq_Mode_ISig_4 1;
BA_ "GenSigSendType" SG_ 845 TipperTailGateRequest_UB_ISig_4 7;
BA_ "Platform_VMCU1_Sig" SG_ 845 TipperTailGateRequest_UB_ISig_4 1;
BA_ "GenSigCycleTime" SG_ 845 TrafficAccShutDownReq_CRC_ISig_4 100;
BA_ "GenSigCycleTimeActive" SG_ 845 TrafficAccShutDownReq_CRC_ISig_4 100;
BA_ "GenSigCycleTime" SG_ 845 ExtraHeating_status_ISig_4 100;
BA_ "GenSigCycleTimeActive" SG_ 845 ExtraHeating_status_ISig_4 100;
BA_ "GenSigStartValue" SG_ 845 ExtraHeating_status_ISig_4 3;
BA_ "GenSigCycleTime" SG_ 845 FrontalCollisionAccidentStatus_I 100;
BA_ "GenSigCycleTimeActive" SG_ 845 FrontalCollisionAccidentStatus_I 100;
BA_ "GenSigStartValue" SG_ 845 FrontalCollisionAccidentStatus_I 3;
BA_ "SystemSignalLongSymbol" SG_ 845 FrontalCollisionAccidentStatus_I "FrontalCollisionAccidentStatus_ISig_4";
BA_ "GenSigSendType" SG_ 845 LoadDistributionRequested_UB_ISi 7;
BA_ "Platform_VMCU1_Sig" SG_ 845 LoadDistributionRequested_UB_ISi 1;
BA_ "SystemSignalLongSymbol" SG_ 845 LoadDistributionRequested_UB_ISi "LoadDistributionRequested_UB_ISig_4";
BA_ "GenSigCycleTime" SG_ 845 TipperUpDownRequest_ISig_4 100;
BA_ "GenSigCycleTimeActive" SG_ 845 TipperUpDownRequest_ISig_4 100;
BA_ "GenSigStartValue" SG_ 845 TipperUpDownRequest_ISig_4 7;
BA_ "GenSigMaxLatency" SG_ 845 TipperUpDownRequest_ISig_4 75;
BA_ "NeedsUpdateBit" SG_ 845 TipperUpDownRequest_ISig_4 1;
BA_ "Platform_VMCU1_Sig" SG_ 845 TipperUpDownRequest_ISig_4 1;
BA_ "GenSigSendType" SG_ 845 TipperTarpaulinRequest_UB_ISig_4 7;
BA_ "Platform_VMCU1_Sig" SG_ 845 TipperTarpaulinRequest_UB_ISig_4 1;
BA_ "GenSigCycleTime" SG_ 845 LoadDistributionRequested_ISig_4 100;
BA_ "GenSigCycleTimeActive" SG_ 845 LoadDistributionRequested_ISig_4 100;
BA_ "GenSigStartValue" SG_ 845 LoadDistributionRequested_ISig_4 15;
BA_ "NeedsUpdateBit" SG_ 845 LoadDistributionRequested_ISig_4 1;
BA_ "Platform_VMCU1_Sig" SG_ 845 LoadDistributionRequested_ISig_4 1;
BA_ "GenSigSendType" SG_ 845 TipperShakerRequest_UB_ISig_4 7;
BA_ "Platform_VMCU1_Sig" SG_ 845 TipperShakerRequest_UB_ISig_4 1;
BA_ "GenSigSendType" SG_ 845 TailLiftMotionRequest_UB_ISig_4 7;
BA_ "Platform_VMCU1_Sig" SG_ 845 TailLiftMotionRequest_UB_ISig_4 1;
BA_ "GenSigCycleTime" SG_ 845 TipperTailGateRequest_ISig_4 100;
BA_ "GenSigCycleTimeActive" SG_ 845 TipperTailGateRequest_ISig_4 100;
BA_ "GenSigStartValue" SG_ 845 TipperTailGateRequest_ISig_4 7;
BA_ "GenSigMaxLatency" SG_ 845 TipperTailGateRequest_ISig_4 75;
BA_ "NeedsUpdateBit" SG_ 845 TipperTailGateRequest_ISig_4 1;
BA_ "Platform_VMCU1_Sig" SG_ 845 TipperTailGateRequest_ISig_4 1;
BA_ "GenSigCycleTime" SG_ 845 TipperTippingBodySelection_ISig_ 100;
BA_ "GenSigCycleTimeActive" SG_ 845 TipperTippingBodySelection_ISig_ 100;
BA_ "GenSigStartValue" SG_ 845 TipperTippingBodySelection_ISig_ 3;
BA_ "GenSigMaxLatency" SG_ 845 TipperTippingBodySelection_ISig_ 75;
BA_ "NeedsUpdateBit" SG_ 845 TipperTippingBodySelection_ISig_ 1;
BA_ "Platform_VMCU1_Sig" SG_ 845 TipperTippingBodySelection_ISig_ 1;
BA_ "SystemSignalLongSymbol" SG_ 845 TipperTippingBodySelection_ISig_ "TipperTippingBodySelection_ISig_4";
BA_ "GenSigCycleTime" SG_ 845 TipperEmergencyStop_ISig_4 100;
BA_ "GenSigCycleTimeActive" SG_ 845 TipperEmergencyStop_ISig_4 100;
BA_ "GenSigStartValue" SG_ 845 TipperEmergencyStop_ISig_4 3;
BA_ "GenSigMaxLatency" SG_ 845 TipperEmergencyStop_ISig_4 75;
BA_ "NeedsUpdateBit" SG_ 845 TipperEmergencyStop_ISig_4 1;
BA_ "Platform_VMCU1_Sig" SG_ 845 TipperEmergencyStop_ISig_4 1;
BA_ "GenSigSendType" SG_ 845 TipperTippingBodySelection_UB_IS 7;
BA_ "Platform_VMCU1_Sig" SG_ 845 TipperTippingBodySelection_UB_IS 1;
BA_ "SystemSignalLongSymbol" SG_ 845 TipperTippingBodySelection_UB_IS "TipperTippingBodySelection_UB_ISig_4";
BA_ "GenSigCycleTime" SG_ 845 ExtraBbWrcWatchdog_ISig_4 100;
BA_ "GenSigCycleTimeActive" SG_ 845 ExtraBbWrcWatchdog_ISig_4 100;
BA_ "GenSigStartValue" SG_ 845 ExtraBbWrcWatchdog_ISig_4 3;
BA_ "GenSigMaxLatency" SG_ 845 ExtraBbWrcWatchdog_ISig_4 75;
BA_ "NeedsUpdateBit" SG_ 845 ExtraBbWrcWatchdog_ISig_4 1;
BA_ "Platform_VMCU1_Sig" SG_ 845 ExtraBbWrcWatchdog_ISig_4 1;
BA_ "GenSigSendType" SG_ 845 TipperEmergencyStop_UB_ISig_4 7;
BA_ "Platform_VMCU1_Sig" SG_ 845 TipperEmergencyStop_UB_ISig_4 1;
BA_ "GenSigCycleTime" SG_ 845 AutoFrontWheelDriveDrvReq 100;
BA_ "GenSigCycleTimeActive" SG_ 845 AutoFrontWheelDriveDrvReq 100;
BA_ "GenSigStartValue" SG_ 845 AutoFrontWheelDriveDrvReq 3;
BA_ "Platform_VMCU1_Sig" SG_ 845 AutoFrontWheelDriveDrvReq 1;
BA_ "GenSigCycleTime" SG_ 845 ShortStopHeater_cmd_ISig_4 100;
BA_ "GenSigCycleTimeActive" SG_ 845 ShortStopHeater_cmd_ISig_4 100;
BA_ "GenSigStartValue" SG_ 845 ShortStopHeater_cmd_ISig_4 3;
BA_ "Platform_VMCU1_Sig" SG_ 845 ShortStopHeater_cmd_ISig_4 1;
BA_ "GenSigSendType" SG_ 845 TipperUpDownRequest_UB_ISig_4 7;
BA_ "Platform_VMCU1_Sig" SG_ 845 TipperUpDownRequest_UB_ISig_4 1;
BA_ "GenSigCycleTime" SG_ 845 TailLiftMotionRequest_ISig_4 100;
BA_ "GenSigCycleTimeActive" SG_ 845 TailLiftMotionRequest_ISig_4 100;
BA_ "GenSigStartValue" SG_ 845 TailLiftMotionRequest_ISig_4 7;
BA_ "GenSigMaxLatency" SG_ 845 TailLiftMotionRequest_ISig_4 75;
BA_ "NeedsUpdateBit" SG_ 845 TailLiftMotionRequest_ISig_4 1;
BA_ "Platform_VMCU1_Sig" SG_ 845 TailLiftMotionRequest_ISig_4 1;
BA_ "GenSigCycleTime" SG_ 845 TipperShakerRequest_ISig_4 100;
BA_ "GenSigCycleTimeActive" SG_ 845 TipperShakerRequest_ISig_4 100;
BA_ "GenSigStartValue" SG_ 845 TipperShakerRequest_ISig_4 3;
BA_ "GenSigMaxLatency" SG_ 845 TipperShakerRequest_ISig_4 75;
BA_ "NeedsUpdateBit" SG_ 845 TipperShakerRequest_ISig_4 1;
BA_ "Platform_VMCU1_Sig" SG_ 845 TipperShakerRequest_ISig_4 1;
BA_ "GenSigCycleTime" SG_ 845 TrafficAccShutDownReq_Rqst_ISig_ 100;
BA_ "GenSigCycleTimeActive" SG_ 845 TrafficAccShutDownReq_Rqst_ISig_ 100;
BA_ "GenSigStartValue" SG_ 845 TrafficAccShutDownReq_Rqst_ISig_ 3;
BA_ "SystemSignalLongSymbol" SG_ 845 TrafficAccShutDownReq_Rqst_ISig_ "TrafficAccShutDownReq_Rqst_ISig_4";
BA_ "GenSigCycleTime" SG_ 845 TipperTarpaulinRequest_ISig_4 100;
BA_ "GenSigCycleTimeActive" SG_ 845 TipperTarpaulinRequest_ISig_4 100;
BA_ "GenSigStartValue" SG_ 845 TipperTarpaulinRequest_ISig_4 7;
BA_ "GenSigMaxLatency" SG_ 845 TipperTarpaulinRequest_ISig_4 75;
BA_ "NeedsUpdateBit" SG_ 845 TipperTarpaulinRequest_ISig_4 1;
BA_ "Platform_VMCU1_Sig" SG_ 845 TipperTarpaulinRequest_ISig_4 1;
BA_ "GenSigCycleTime" SG_ 845 TrafficAccShutDownReq_SqC_ISig_4 100;
BA_ "GenSigCycleTimeActive" SG_ 845 TrafficAccShutDownReq_SqC_ISig_4 100;
BA_ "GenSigSendType" SG_ 845 ExtraBbWrcWatchdog_UB_ISig_4 7;
BA_ "Platform_VMCU1_Sig" SG_ 845 ExtraBbWrcWatchdog_UB_ISig_4 1;
BA_ "GenSigCycleTime" SG_ 845 ABSInhibitRqstDenied 100;
BA_ "GenSigCycleTimeActive" SG_ 845 ABSInhibitRqstDenied 100;
BA_ "GenSigStartValue" SG_ 845 ABSInhibitRqstDenied 3;
BA_ "GenSigSendType" SG_ 1074 DynamicCode_value 1;
BA_ "GenSigStartValue" SG_ 1074 DynamicCode_value 4294967295;
BA_ "Platform_VMCU1_Sig" SG_ 1074 DynamicCode_value 1;
BA_ "GenSigSendType" SG_ 982 PHTimer_rqst_Hours_ISig_4 1;
BA_ "GenSigCycleTime" SG_ 982 PHTimer_rqst_Hours_ISig_4 100;
BA_ "GenSigCycleTimeActive" SG_ 982 PHTimer_rqst_Hours_ISig_4 100;
BA_ "GenSigStartValue" SG_ 982 PHTimer_rqst_Hours_ISig_4 255;
BA_ "Platform_VMCU1_Sig" SG_ 982 PHTimer_rqst_Hours_ISig_4 1;
BA_ "GenSigSendType" SG_ 982 PHTimer_rqst_Minutes_ISig_4 1;
BA_ "GenSigCycleTime" SG_ 982 PHTimer_rqst_Minutes_ISig_4 100;
BA_ "GenSigCycleTimeActive" SG_ 982 PHTimer_rqst_Minutes_ISig_4 100;
BA_ "GenSigStartValue" SG_ 982 PHTimer_rqst_Minutes_ISig_4 255;
BA_ "Platform_VMCU1_Sig" SG_ 982 PHTimer_rqst_Minutes_ISig_4 1;
BA_ "GenSigSendType" SG_ 982 PHTimer_rqst_SetAlarmOper_ISig_4 1;
BA_ "GenSigCycleTime" SG_ 982 PHTimer_rqst_SetAlarmOper_ISig_4 100;
BA_ "GenSigCycleTimeActive" SG_ 982 PHTimer_rqst_SetAlarmOper_ISig_4 100;
BA_ "GenSigStartValue" SG_ 982 PHTimer_rqst_SetAlarmOper_ISig_4 7;
BA_ "Platform_VMCU1_Sig" SG_ 982 PHTimer_rqst_SetAlarmOper_ISig_4 1;
BA_ "GenSigSendType" SG_ 982 PHTimer_rqst_DayOfWeekRq_ISig_4 1;
BA_ "GenSigCycleTime" SG_ 982 PHTimer_rqst_DayOfWeekRq_ISig_4 100;
BA_ "GenSigCycleTimeActive" SG_ 982 PHTimer_rqst_DayOfWeekRq_ISig_4 100;
BA_ "GenSigStartValue" SG_ 982 PHTimer_rqst_DayOfWeekRq_ISig_4 15;
BA_ "Platform_VMCU1_Sig" SG_ 982 PHTimer_rqst_DayOfWeekRq_ISig_4 1;
BA_ "GenSigSendType" SG_ 943 CIOM_BB2_13S_FCS 7;
BA_ "Platform_VMCU1_Sig" SG_ 943 CIOM_BB2_13S_FCS 1;
BA_ "GenSigSendType" SG_ 940 EngineStartAuth_stat 1;
BA_ "GenSigMaxLatency" SG_ 940 EngineStartAuth_stat 100;
BA_ "Platform_VMCU1_Sig" SG_ 940 EngineStartAuth_stat 1;
BA_ "GenSigSendType" SG_ 937 CIOM_BB2_12S_FCS 7;
BA_ "Platform_VMCU1_Sig" SG_ 937 CIOM_BB2_12S_FCS 1;
BA_ "GenSigSendType" SG_ 934 KeyAuthEncrypted_stat 1;
BA_ "GenSigMaxLatency" SG_ 934 KeyAuthEncrypted_stat 100;
BA_ "Platform_VMCU1_Sig" SG_ 934 KeyAuthEncrypted_stat 1;
BA_ "GenSigCycleTime" SG_ 928 ACCoolingFanSpeedRequest 100;
BA_ "GenSigCycleTimeActive" SG_ 928 ACCoolingFanSpeedRequest 100;
BA_ "GenSigStartValue" SG_ 928 ACCoolingFanSpeedRequest 65535;
BA_ "GenSigMaxLatency" SG_ 928 ACCoolingFanSpeedRequest 110;
BA_ "NeedsUpdateBit" SG_ 928 ACCoolingFanSpeedRequest 1;
BA_ "Platform_VMCU1_Sig" SG_ 928 ACCoolingFanSpeedRequest 1;
BA_ "SeToolAncestorID_SIGNAL" SG_ 928 ACCoolingFanSpeedRequest "x0000001D0425B656";
BA_ "SeToolItemID_SIGNAL" SG_ 928 ACCoolingFanSpeedRequest "x0000001D043C814A";
BA_ "SeToolName_SIGNAL" SG_ 928 ACCoolingFanSpeedRequest "ACCoolingFanSpeedRequest";
BA_ "SeToolVersion_SIGNAL" SG_ 928 ACCoolingFanSpeedRequest "2";
BA_ "GenSigCycleTime" SG_ 928 CabTilt_rqst 100;
BA_ "GenSigCycleTimeActive" SG_ 928 CabTilt_rqst 100;
BA_ "GenSigStartValue" SG_ 928 CabTilt_rqst 3;
BA_ "GenSigMaxLatency" SG_ 928 CabTilt_rqst 110;
BA_ "Platform_VMCU1_Sig" SG_ 928 CabTilt_rqst 1;
BA_ "SeToolAncestorID_SIGNAL" SG_ 928 CabTilt_rqst "x0000001D0416FC9A";
BA_ "SeToolItemID_SIGNAL" SG_ 928 CabTilt_rqst "x0000001D0416FC9A";
BA_ "SeToolName_SIGNAL" SG_ 928 CabTilt_rqst "CabTilt_rqst";
BA_ "SeToolVersion_SIGNAL" SG_ 928 CabTilt_rqst "1";
BA_ "GenSigCycleTime" SG_ 928 Pto3CabRequest 100;
BA_ "GenSigCycleTimeActive" SG_ 928 Pto3CabRequest 100;
BA_ "GenSigStartValue" SG_ 928 Pto3CabRequest 3;
BA_ "GenSigMaxLatency" SG_ 928 Pto3CabRequest 110;
BA_ "Platform_VMCU1_Sig" SG_ 928 Pto3CabRequest 1;
BA_ "SeToolAncestorID_SIGNAL" SG_ 928 Pto3CabRequest "x0000001D0439DD78";
BA_ "SeToolItemID_SIGNAL" SG_ 928 Pto3CabRequest "x0000001D0439DD78";
BA_ "SeToolName_SIGNAL" SG_ 928 Pto3CabRequest "Pto3CabRequest";
BA_ "SeToolVersion_SIGNAL" SG_ 928 Pto3CabRequest "1";
BA_ "GenSigCycleTime" SG_ 928 Pto4CabRequest 100;
BA_ "GenSigCycleTimeActive" SG_ 928 Pto4CabRequest 100;
BA_ "GenSigStartValue" SG_ 928 Pto4CabRequest 3;
BA_ "GenSigMaxLatency" SG_ 928 Pto4CabRequest 110;
BA_ "Platform_VMCU1_Sig" SG_ 928 Pto4CabRequest 1;
BA_ "SeToolAncestorID_SIGNAL" SG_ 928 Pto4CabRequest "x0000001D0439DD7A";
BA_ "SeToolItemID_SIGNAL" SG_ 928 Pto4CabRequest "x0000001D0439DD7A";
BA_ "SeToolName_SIGNAL" SG_ 928 Pto4CabRequest "Pto4CabRequest";
BA_ "SeToolVersion_SIGNAL" SG_ 928 Pto4CabRequest "1";
BA_ "GenSigCycleTime" SG_ 928 WindscreenDefrostInd_cmd_ISig_4 100;
BA_ "GenSigCycleTimeActive" SG_ 928 WindscreenDefrostInd_cmd_ISig_4 100;
BA_ "SeToolAncestorID_SIGNAL" SG_ 928 WindscreenDefrostInd_cmd_ISig_4 "x0000001D04405ABB";
BA_ "SeToolItemID_SIGNAL" SG_ 928 WindscreenDefrostInd_cmd_ISig_4 "x0000001D04405ABB";
BA_ "SeToolName_SIGNAL" SG_ 928 WindscreenDefrostInd_cmd_ISig_4 "WindscreenDefrost_IndicationCmd";
BA_ "SeToolVersion_SIGNAL" SG_ 928 WindscreenDefrostInd_cmd_ISig_4 "1";
BA_ "GenSigSendType" SG_ 928 ACCoolingFanSpeedRequest_UB 7;
BA_ "Platform_VMCU1_Sig" SG_ 928 ACCoolingFanSpeedRequest_UB 1;
BA_ "GenSigCycleTime" SG_ 928 SRSAirbagStatus_ISig_4 100;
BA_ "GenSigCycleTimeActive" SG_ 928 SRSAirbagStatus_ISig_4 100;
BA_ "GenSigStartValue" SG_ 928 SRSAirbagStatus_ISig_4 3;
BA_ "GenSigMaxLatency" SG_ 928 SRSAirbagStatus_ISig_4 110;
BA_ "Platform_VMCU1_Sig" SG_ 928 SRSAirbagStatus_ISig_4 1;
BA_ "SeToolAncestorID_SIGNAL" SG_ 928 SRSAirbagStatus_ISig_4 "x0000001D04147207";
BA_ "SeToolItemID_SIGNAL" SG_ 928 SRSAirbagStatus_ISig_4 "x0000001D042F372C";
BA_ "SeToolName_SIGNAL" SG_ 928 SRSAirbagStatus_ISig_4 "SRSAirbagStatus";
BA_ "SeToolVersion_SIGNAL" SG_ 928 SRSAirbagStatus_ISig_4 "2";
BA_ "GenSigCycleTime" SG_ 928 FrontLidAjar_Stat 100;
BA_ "GenSigCycleTimeActive" SG_ 928 FrontLidAjar_Stat 100;
BA_ "GenSigStartValue" SG_ 928 FrontLidAjar_Stat 3;
BA_ "Platform_VMCU1_Sig" SG_ 928 FrontLidAjar_Stat 1;
BA_ "GenSigCycleTime" SG_ 928 ParkingHeaterCleaning_Rqst_ISig_ 100;
BA_ "GenSigCycleTimeActive" SG_ 928 ParkingHeaterCleaning_Rqst_ISig_ 100;
BA_ "GenSigStartValue" SG_ 928 ParkingHeaterCleaning_Rqst_ISig_ 3;
BA_ "Platform_VMCU1_Sig" SG_ 928 ParkingHeaterCleaning_Rqst_ISig_ 1;
BA_ "SystemSignalLongSymbol" SG_ 928 ParkingHeaterCleaning_Rqst_ISig_ "ParkingHeaterCleaning_Rqst_ISig_4";
BA_ "GenSigCycleTime" SG_ 928 Pto2CabRequest 100;
BA_ "GenSigCycleTimeActive" SG_ 928 Pto2CabRequest 100;
BA_ "GenSigStartValue" SG_ 928 Pto2CabRequest 3;
BA_ "GenSigMaxLatency" SG_ 928 Pto2CabRequest 110;
BA_ "Platform_VMCU1_Sig" SG_ 928 Pto2CabRequest 1;
BA_ "SeToolAncestorID_SIGNAL" SG_ 928 Pto2CabRequest "x0000001D0439DD75";
BA_ "SeToolItemID_SIGNAL" SG_ 928 Pto2CabRequest "x0000001D0439DD75";
BA_ "SeToolName_SIGNAL" SG_ 928 Pto2CabRequest "Pto2CabRequest";
BA_ "SeToolVersion_SIGNAL" SG_ 928 Pto2CabRequest "1";
BA_ "GenSigCycleTime" SG_ 928 TemporaryRSLSwitchStatus 100;
BA_ "GenSigCycleTimeActive" SG_ 928 TemporaryRSLSwitchStatus 100;
BA_ "GenSigStartValue" SG_ 928 TemporaryRSLSwitchStatus 3;
BA_ "GenSigCycleTime" SG_ 928 SeatSwivelWarning_rqst 100;
BA_ "GenSigCycleTimeActive" SG_ 928 SeatSwivelWarning_rqst 100;
BA_ "GenSigStartValue" SG_ 928 SeatSwivelWarning_rqst 3;
BA_ "GenSigMaxLatency" SG_ 928 SeatSwivelWarning_rqst 110;
BA_ "Platform_VMCU1_Sig" SG_ 928 SeatSwivelWarning_rqst 1;
BA_ "SeToolAncestorID_SIGNAL" SG_ 928 SeatSwivelWarning_rqst "x0000001D0418D487";
BA_ "SeToolItemID_SIGNAL" SG_ 928 SeatSwivelWarning_rqst "x0000001D0418D487";
BA_ "SeToolName_SIGNAL" SG_ 928 SeatSwivelWarning_rqst "SeatSwivelWarning_rqst";
BA_ "SeToolVersion_SIGNAL" SG_ 928 SeatSwivelWarning_rqst "1";
BA_ "GenSigCycleTime" SG_ 928 Pto1CabRequest 100;
BA_ "GenSigCycleTimeActive" SG_ 928 Pto1CabRequest 100;
BA_ "GenSigStartValue" SG_ 928 Pto1CabRequest 3;
BA_ "GenSigMaxLatency" SG_ 928 Pto1CabRequest 110;
BA_ "Platform_VMCU1_Sig" SG_ 928 Pto1CabRequest 1;
BA_ "SeToolAncestorID_SIGNAL" SG_ 928 Pto1CabRequest "x0000001D0439DD73";
BA_ "SeToolItemID_SIGNAL" SG_ 928 Pto1CabRequest "x0000001D0439DD73";
BA_ "SeToolName_SIGNAL" SG_ 928 Pto1CabRequest "Pto1CabRequest";
BA_ "SeToolVersion_SIGNAL" SG_ 928 Pto1CabRequest "1";
BA_ "GenSigCycleTime" SG_ 928 ThreePosDifflockSwitch_stat 100;
BA_ "GenSigCycleTimeActive" SG_ 928 ThreePosDifflockSwitch_stat 100;
BA_ "GenSigStartValue" SG_ 928 ThreePosDifflockSwitch_stat 7;
BA_ "GenSigCycleTime" SG_ 857 LCS_EnableSwitch_rqst 100;
BA_ "GenSigCycleTimeActive" SG_ 857 LCS_EnableSwitch_rqst 100;
BA_ "GenSigStartValue" SG_ 857 LCS_EnableSwitch_rqst 3;
BA_ "GenSigMaxLatency" SG_ 857 LCS_EnableSwitch_rqst 68;
BA_ "Platform_VMCU1_Sig" SG_ 857 LCS_EnableSwitch_rqst 1;
BA_ "SeToolAncestorID_SIGNAL" SG_ 857 LCS_EnableSwitch_rqst "x0000001D041691AD";
BA_ "SeToolItemID_SIGNAL" SG_ 857 LCS_EnableSwitch_rqst "x0000001D041691AD";
BA_ "SeToolName_SIGNAL" SG_ 857 LCS_EnableSwitch_rqst "LCS_EnableSwitch_rqst";
BA_ "SeToolVersion_SIGNAL" SG_ 857 LCS_EnableSwitch_rqst "1";
BA_ "GenSigCycleTime" SG_ 857 EscCrossCountryActivation_rqst 100;
BA_ "GenSigCycleTimeActive" SG_ 857 EscCrossCountryActivation_rqst 100;
BA_ "GenSigStartValue" SG_ 857 EscCrossCountryActivation_rqst 3;
BA_ "GenSigMaxLatency" SG_ 857 EscCrossCountryActivation_rqst 68;
BA_ "Platform_VMCU1_Sig" SG_ 857 EscCrossCountryActivation_rqst 1;
BA_ "SeToolAncestorID_SIGNAL" SG_ 857 EscCrossCountryActivation_rqst "x0000001D041B2E58";
BA_ "SeToolItemID_SIGNAL" SG_ 857 EscCrossCountryActivation_rqst "x0000001D041B2E58";
BA_ "SeToolName_SIGNAL" SG_ 857 EscCrossCountryActivation_rqst "EscCrossCountryActivationRequest";
BA_ "SeToolVersion_SIGNAL" SG_ 857 EscCrossCountryActivation_rqst "1";
BA_ "GenSigCycleTime" SG_ 857 StaticCornerLightMode 100;
BA_ "GenSigCycleTimeActive" SG_ 857 StaticCornerLightMode 100;
BA_ "GenSigStartValue" SG_ 857 StaticCornerLightMode 3;
BA_ "Platform_VMCU1_Sig" SG_ 857 StaticCornerLightMode 1;
BA_ "GenSigCycleTime" SG_ 857 SplitBoxDifflockActvnDrvrRqst_IS 100;
BA_ "GenSigCycleTimeActive" SG_ 857 SplitBoxDifflockActvnDrvrRqst_IS 100;
BA_ "GenSigStartValue" SG_ 857 SplitBoxDifflockActvnDrvrRqst_IS 3;
BA_ "NeedsUpdateBit" SG_ 857 SplitBoxDifflockActvnDrvrRqst_IS 1;
BA_ "Platform_VMCU1_Sig" SG_ 857 SplitBoxDifflockActvnDrvrRqst_IS 1;
BA_ "SystemSignalLongSymbol" SG_ 857 SplitBoxDifflockActvnDrvrRqst_IS "SplitBoxDifflockActvnDrvrRqst_ISig_4";
BA_ "GenSigCycleTime" SG_ 857 ATCFrontWheelDriveRequest 100;
BA_ "GenSigCycleTimeActive" SG_ 857 ATCFrontWheelDriveRequest 100;
BA_ "GenSigStartValue" SG_ 857 ATCFrontWheelDriveRequest 3;
BA_ "GenSigCycleTime" SG_ 857 ConstructionSwitch_stat 100;
BA_ "GenSigCycleTimeActive" SG_ 857 ConstructionSwitch_stat 100;
BA_ "GenSigStartValue" SG_ 857 ConstructionSwitch_stat 3;
BA_ "GenSigMaxLatency" SG_ 857 ConstructionSwitch_stat 26;
BA_ "Platform_VMCU1_Sig" SG_ 857 ConstructionSwitch_stat 1;
BA_ "SeToolAncestorID_SIGNAL" SG_ 857 ConstructionSwitch_stat "x0000001D0423C42C";
BA_ "SeToolItemID_SIGNAL" SG_ 857 ConstructionSwitch_stat "x0000001D0423C42C";
BA_ "SeToolName_SIGNAL" SG_ 857 ConstructionSwitch_stat "ConstructionSwitch_stat";
BA_ "SeToolVersion_SIGNAL" SG_ 857 ConstructionSwitch_stat "1";
BA_ "GenSigCycleTime" SG_ 857 EscCabActionRequest 100;
BA_ "GenSigCycleTimeActive" SG_ 857 EscCabActionRequest 100;
BA_ "GenSigStartValue" SG_ 857 EscCabActionRequest 7;
BA_ "GenSigMaxLatency" SG_ 857 EscCabActionRequest 68;
BA_ "Platform_VMCU1_Sig" SG_ 857 EscCabActionRequest 1;
BA_ "SeToolAncestorID_SIGNAL" SG_ 857 EscCabActionRequest "x0000001D044050FA";
BA_ "SeToolItemID_SIGNAL" SG_ 857 EscCabActionRequest "x0000001D044050FA";
BA_ "SeToolName_SIGNAL" SG_ 857 EscCabActionRequest "EscCabActionRequest";
BA_ "SeToolVersion_SIGNAL" SG_ 857 EscCabActionRequest "1";
BA_ "GenSigCycleTime" SG_ 857 AdjustRequestForIdle 100;
BA_ "GenSigCycleTimeActive" SG_ 857 AdjustRequestForIdle 100;
BA_ "GenSigStartValue" SG_ 857 AdjustRequestForIdle 7;
BA_ "GenSigCycleTime" SG_ 857 SCL_LogicPowerOutput_stat 100;
BA_ "GenSigCycleTimeActive" SG_ 857 SCL_LogicPowerOutput_stat 100;
BA_ "GenSigStartValue" SG_ 857 SCL_LogicPowerOutput_stat 3;
BA_ "GenSigMaxLatency" SG_ 857 SCL_LogicPowerOutput_stat 68;
BA_ "Platform_VMCU1_Sig" SG_ 857 SCL_LogicPowerOutput_stat 1;
BA_ "SeToolAncestorID_SIGNAL" SG_ 857 SCL_LogicPowerOutput_stat "x0000001D04184530";
BA_ "SeToolItemID_SIGNAL" SG_ 857 SCL_LogicPowerOutput_stat "x0000001D04184530";
BA_ "SeToolName_SIGNAL" SG_ 857 SCL_LogicPowerOutput_stat "SCL_LogicPowerOutput_stat";
BA_ "SeToolVersion_SIGNAL" SG_ 857 SCL_LogicPowerOutput_stat "1";
BA_ "GenSigCycleTime" SG_ 857 PinCode_validity_time 100;
BA_ "GenSigCycleTimeActive" SG_ 857 PinCode_validity_time 100;
BA_ "GenSigStartValue" SG_ 857 PinCode_validity_time 255;
BA_ "Platform_VMCU1_Sig" SG_ 857 PinCode_validity_time 1;
BA_ "GenSigCycleTime" SG_ 857 StatTrailerBrakeSwitchStatus 100;
BA_ "GenSigCycleTimeActive" SG_ 857 StatTrailerBrakeSwitchStatus 100;
BA_ "GenSigStartValue" SG_ 857 StatTrailerBrakeSwitchStatus 3;
BA_ "Platform_VMCU1_Sig" SG_ 857 StatTrailerBrakeSwitchStatus 1;
BA_ "GenSigSendType" SG_ 857 SplitBoxDifflockActvnDrvrRqst_UB 7;
BA_ "Platform_VMCU1_Sig" SG_ 857 SplitBoxDifflockActvnDrvrRqst_UB 1;
BA_ "SystemSignalLongSymbol" SG_ 857 SplitBoxDifflockActvnDrvrRqst_UB "SplitBoxDifflockActvnDrvrRqst_UB_ISig_4";
BA_ "GenSigCycleTime" SG_ 857 RoofHatch_HMI_rqst 100;
BA_ "GenSigCycleTimeActive" SG_ 857 RoofHatch_HMI_rqst 100;
BA_ "GenSigStartValue" SG_ 857 RoofHatch_HMI_rqst 7;
BA_ "Platform_VMCU1_Sig" SG_ 857 RoofHatch_HMI_rqst 1;
BA_ "GenSigCycleTime" SG_ 857 EscCabEnable 100;
BA_ "GenSigCycleTimeActive" SG_ 857 EscCabEnable 100;
BA_ "GenSigStartValue" SG_ 857 EscCabEnable 3;
BA_ "GenSigMaxLatency" SG_ 857 EscCabEnable 68;
BA_ "Platform_VMCU1_Sig" SG_ 857 EscCabEnable 1;
BA_ "SeToolAncestorID_SIGNAL" SG_ 857 EscCabEnable "x0000001D043DFB25";
BA_ "SeToolItemID_SIGNAL" SG_ 857 EscCabEnable "x0000001D043DFB25";
BA_ "SeToolName_SIGNAL" SG_ 857 EscCabEnable "EscCabEnable";
BA_ "SeToolVersion_SIGNAL" SG_ 857 EscCabEnable "1";
BA_ "GenSigCycleTime" SG_ 857 ExtraSideMarkers_Rqst 100;
BA_ "GenSigCycleTimeActive" SG_ 857 ExtraSideMarkers_Rqst 100;
BA_ "GenSigStartValue" SG_ 857 ExtraSideMarkers_Rqst 3;
BA_ "Platform_VMCU1_Sig" SG_ 857 ExtraSideMarkers_Rqst 1;
BA_ "GenSigCycleTime" SG_ 857 LevelingThumbwheel_stat 100;
BA_ "GenSigCycleTimeActive" SG_ 857 LevelingThumbwheel_stat 100;
BA_ "GenSigStartValue" SG_ 857 LevelingThumbwheel_stat 31;
BA_ "Platform_VMCU1_Sig" SG_ 857 LevelingThumbwheel_stat 1;
BA_ "GenSigCycleTime" SG_ 857 DASActivation_rqst 100;
BA_ "GenSigCycleTimeActive" SG_ 857 DASActivation_rqst 100;
BA_ "GenSigStartValue" SG_ 857 DASActivation_rqst 3;
BA_ "GenSigMaxLatency" SG_ 857 DASActivation_rqst 68;
BA_ "Platform_VMCU1_Sig" SG_ 857 DASActivation_rqst 1;
BA_ "SeToolAncestorID_SIGNAL" SG_ 857 DASActivation_rqst "x0000001D04169A8A";
BA_ "SeToolItemID_SIGNAL" SG_ 857 DASActivation_rqst "x0000001D04290712";
BA_ "SeToolName_SIGNAL" SG_ 857 DASActivation_rqst "DASActivation_rqst";
BA_ "SeToolVersion_SIGNAL" SG_ 857 DASActivation_rqst "2";
BA_ "GenSigCycleTime" SG_ 857 DriverSeatBeltSwitch_ISig_4 100;
BA_ "GenSigCycleTimeActive" SG_ 857 DriverSeatBeltSwitch_ISig_4 100;
BA_ "GenSigStartValue" SG_ 857 DriverSeatBeltSwitch_ISig_4 3;
BA_ "GenSigMaxLatency" SG_ 857 DriverSeatBeltSwitch_ISig_4 68;
BA_ "Platform_VMCU1_Sig" SG_ 857 DriverSeatBeltSwitch_ISig_4 1;
BA_ "SeToolAncestorID_SIGNAL" SG_ 857 DriverSeatBeltSwitch_ISig_4 "x0000001D0412FE94";
BA_ "SeToolItemID_SIGNAL" SG_ 857 DriverSeatBeltSwitch_ISig_4 "x0000001D0412FE94";
BA_ "SeToolName_SIGNAL" SG_ 857 DriverSeatBeltSwitch_ISig_4 "DriverSeatBeltSwitch";
BA_ "SeToolVersion_SIGNAL" SG_ 857 DriverSeatBeltSwitch_ISig_4 "1";
BA_ "GenSigCycleTime" SG_ 857 PinCode_stat 100;
BA_ "GenSigCycleTimeActive" SG_ 857 PinCode_stat 100;
BA_ "GenSigStartValue" SG_ 857 PinCode_stat 7;
BA_ "Platform_VMCU1_Sig" SG_ 857 PinCode_stat 1;
BA_ "GenSigCycleTime" SG_ 857 WarmUp_Request 100;
BA_ "GenSigCycleTimeActive" SG_ 857 WarmUp_Request 100;
BA_ "GenSigStartValue" SG_ 857 WarmUp_Request 3;
BA_ "Platform_VMCU1_Sig" SG_ 857 WarmUp_Request 1;
BA_ "GenSigCycleTime" SG_ 857 LKSEnableSwitch_rqst 100;
BA_ "GenSigCycleTimeActive" SG_ 857 LKSEnableSwitch_rqst 100;
BA_ "GenSigStartValue" SG_ 857 LKSEnableSwitch_rqst 3;
BA_ "GenSigMaxLatency" SG_ 857 LKSEnableSwitch_rqst 68;
BA_ "Platform_VMCU1_Sig" SG_ 857 LKSEnableSwitch_rqst 1;
BA_ "SeToolAncestorID_SIGNAL" SG_ 857 LKSEnableSwitch_rqst "x0000001D04158E2E";
BA_ "SeToolItemID_SIGNAL" SG_ 857 LKSEnableSwitch_rqst "x0000001D04158E2E";
BA_ "SeToolName_SIGNAL" SG_ 857 LKSEnableSwitch_rqst "LKSEnableSwitch_rqst";
BA_ "SeToolVersion_SIGNAL" SG_ 857 LKSEnableSwitch_rqst "1";
BA_ "GenSigCycleTime" SG_ 1044 AlmClkSnze_LECM_rqst_ID_ISig_4 100;
BA_ "GenSigCycleTimeActive" SG_ 1044 AlmClkSnze_LECM_rqst_ID_ISig_4 100;
BA_ "GenSigStartValue" SG_ 1044 AlmClkSnze_LECM_rqst_ID_ISig_4 127;
BA_ "Platform_VMCU1_Sig" SG_ 1044 AlmClkSnze_LECM_rqst_ID_ISig_4 1;
BA_ "GenSigCycleTime" SG_ 1044 AlmClkSetCurAlm_rqst_ID 100;
BA_ "GenSigCycleTimeActive" SG_ 1044 AlmClkSetCurAlm_rqst_ID 100;
BA_ "GenSigStartValue" SG_ 1044 AlmClkSetCurAlm_rqst_ID 127;
BA_ "Platform_VMCU1_Sig" SG_ 1044 AlmClkSetCurAlm_rqst_ID 1;
BA_ "GenSigCycleTime" SG_ 1044 AlmClkSnze_LECM_rqst_Action_ISig 100;
BA_ "GenSigCycleTimeActive" SG_ 1044 AlmClkSnze_LECM_rqst_Action_ISig 100;
BA_ "GenSigStartValue" SG_ 1044 AlmClkSnze_LECM_rqst_Action_ISig 7;
BA_ "Platform_VMCU1_Sig" SG_ 1044 AlmClkSnze_LECM_rqst_Action_ISig 1;
BA_ "SystemSignalLongSymbol" SG_ 1044 AlmClkSnze_LECM_rqst_Action_ISig "AlmClkSnze_LECM_rqst_Action_ISig_4";
BA_ "GenSigCycleTime" SG_ 1044 AlmClkSetCurAlm_rqst_Stat 100;
BA_ "GenSigCycleTimeActive" SG_ 1044 AlmClkSetCurAlm_rqst_Stat 100;
BA_ "GenSigStartValue" SG_ 1044 AlmClkSetCurAlm_rqst_Stat 3;
BA_ "Platform_VMCU1_Sig" SG_ 1044 AlmClkSetCurAlm_rqst_Stat 1;
BA_ "GenSigCycleTime" SG_ 1044 AlmClkSetCurAlm_rqst_SetMin 100;
BA_ "GenSigCycleTimeActive" SG_ 1044 AlmClkSetCurAlm_rqst_SetMin 100;
BA_ "GenSigStartValue" SG_ 1044 AlmClkSetCurAlm_rqst_SetMin 63;
BA_ "Platform_VMCU1_Sig" SG_ 1044 AlmClkSetCurAlm_rqst_SetMin 1;
BA_ "GenSigCycleTime" SG_ 1044 AlmClkSetCurAlm_rqst_SetHr 100;
BA_ "GenSigCycleTimeActive" SG_ 1044 AlmClkSetCurAlm_rqst_SetHr 100;
BA_ "GenSigStartValue" SG_ 1044 AlmClkSetCurAlm_rqst_SetHr 31;
BA_ "Platform_VMCU1_Sig" SG_ 1044 AlmClkSetCurAlm_rqst_SetHr 1;
BA_ "GenSigCycleTime" SG_ 1044 CollSituationHMICtrlRequestVM 100;
BA_ "GenSigCycleTimeActive" SG_ 1044 CollSituationHMICtrlRequestVM 100;
BA_ "GenSigStartValue" SG_ 1044 CollSituationHMICtrlRequestVM 7;
BA_ "Platform_VMCU1_Sig" SG_ 1044 CollSituationHMICtrlRequestVM 1;
BA_ "GenSigCycleTime" SG_ 1044 AcCoolantPumpEngagementRequest_I 100;
BA_ "GenSigCycleTimeActive" SG_ 1044 AcCoolantPumpEngagementRequest_I 100;
BA_ "GenSigStartValue" SG_ 1044 AcCoolantPumpEngagementRequest_I 255;
BA_ "Platform_VMCU1_Sig" SG_ 1044 AcCoolantPumpEngagementRequest_I 1;
BA_ "SystemSignalLongSymbol" SG_ 1044 AcCoolantPumpEngagementRequest_I "AcCoolantPumpEngagementRequest_ISig_4";
BA_ "GenSigCycleTime" SG_ 1044 AlmClkSetCurAlm_rqst_Type 100;
BA_ "GenSigCycleTimeActive" SG_ 1044 AlmClkSetCurAlm_rqst_Type 100;
BA_ "GenSigStartValue" SG_ 1044 AlmClkSetCurAlm_rqst_Type 7;
BA_ "Platform_VMCU1_Sig" SG_ 1044 AlmClkSetCurAlm_rqst_Type 1;
BA_ "GenSigCycleTime" SG_ 1044 WRC_Docking_stat_ISig_4 100;
BA_ "GenSigCycleTimeActive" SG_ 1044 WRC_Docking_stat_ISig_4 100;
BA_ "GenSigStartValue" SG_ 1044 WRC_Docking_stat_ISig_4 3;
BA_ "Platform_VMCU1_Sig" SG_ 1044 WRC_Docking_stat_ISig_4 1;
BA_ "GenSigSendType" SG_ 847 LiftAxle1DirectControl_UB_ISig_4 7;
BA_ "Platform_VMCU1_Sig" SG_ 847 LiftAxle1DirectControl_UB_ISig_4 1;
BA_ "GenSigCycleTime" SG_ 847 MirrorSelectRightMainBtn_stat_IS 100;
BA_ "GenSigCycleTimeActive" SG_ 847 MirrorSelectRightMainBtn_stat_IS 100;
BA_ "GenSigStartValue" SG_ 847 MirrorSelectRightMainBtn_stat_IS 3;
BA_ "GenSigMaxLatency" SG_ 847 MirrorSelectRightMainBtn_stat_IS 66;
BA_ "Platform_VMCU1_Sig" SG_ 847 MirrorSelectRightMainBtn_stat_IS 1;
BA_ "SeToolAncestorID_SIGNAL" SG_ 847 MirrorSelectRightMainBtn_stat_IS "x0000001D0423D932";
BA_ "SeToolItemID_SIGNAL" SG_ 847 MirrorSelectRightMainBtn_stat_IS "x0000001D0429669B";
BA_ "SeToolName_SIGNAL" SG_ 847 MirrorSelectRightMainBtn_stat_IS "EM_MirrorselectRightMain_ButtonStatus";
BA_ "SeToolVersion_SIGNAL" SG_ 847 MirrorSelectRightMainBtn_stat_IS "4";
BA_ "SystemSignalLongSymbol" SG_ 847 MirrorSelectRightMainBtn_stat_IS "MirrorSelectRightMainBtn_stat_ISig_4";
BA_ "GenSigCycleTime" SG_ 847 WRCEngineStopRequest_ISig_4 100;
BA_ "GenSigCycleTimeActive" SG_ 847 WRCEngineStopRequest_ISig_4 100;
BA_ "GenSigStartValue" SG_ 847 WRCEngineStopRequest_ISig_4 3;
BA_ "GenSigMaxLatency" SG_ 847 WRCEngineStopRequest_ISig_4 28;
BA_ "NeedsUpdateBit" SG_ 847 WRCEngineStopRequest_ISig_4 1;
BA_ "Platform_VMCU1_Sig" SG_ 847 WRCEngineStopRequest_ISig_4 1;
BA_ "GenSigCycleTime" SG_ 847 LiftAxle1DirectControl_ISig_4 100;
BA_ "GenSigCycleTimeActive" SG_ 847 LiftAxle1DirectControl_ISig_4 100;
BA_ "GenSigStartValue" SG_ 847 LiftAxle1DirectControl_ISig_4 7;
BA_ "NeedsUpdateBit" SG_ 847 LiftAxle1DirectControl_ISig_4 1;
BA_ "Platform_VMCU1_Sig" SG_ 847 LiftAxle1DirectControl_ISig_4 1;
BA_ "GenSigCycleTime" SG_ 847 MirrorSelectRightWideBtn_stat_IS 100;
BA_ "GenSigCycleTimeActive" SG_ 847 MirrorSelectRightWideBtn_stat_IS 100;
BA_ "GenSigStartValue" SG_ 847 MirrorSelectRightWideBtn_stat_IS 3;
BA_ "GenSigMaxLatency" SG_ 847 MirrorSelectRightWideBtn_stat_IS 66;
BA_ "Platform_VMCU1_Sig" SG_ 847 MirrorSelectRightWideBtn_stat_IS 1;
BA_ "SeToolAncestorID_SIGNAL" SG_ 847 MirrorSelectRightWideBtn_stat_IS "x0000001D0423D932";
BA_ "SeToolItemID_SIGNAL" SG_ 847 MirrorSelectRightWideBtn_stat_IS "x0000001D0429669B";
BA_ "SeToolName_SIGNAL" SG_ 847 MirrorSelectRightWideBtn_stat_IS "EM_MirrorselectRightWide_ButtonStatus";
BA_ "SeToolVersion_SIGNAL" SG_ 847 MirrorSelectRightWideBtn_stat_IS "4";
BA_ "SystemSignalLongSymbol" SG_ 847 MirrorSelectRightWideBtn_stat_IS "MirrorSelectRightWideBtn_stat_ISig_4";
BA_ "GenSigCycleTime" SG_ 847 PanicAlarmFromKeyfob_rqst 100;
BA_ "GenSigCycleTimeActive" SG_ 847 PanicAlarmFromKeyfob_rqst 100;
BA_ "GenSigStartValue" SG_ 847 PanicAlarmFromKeyfob_rqst 3;
BA_ "GenSigMaxLatency" SG_ 847 PanicAlarmFromKeyfob_rqst 66;
BA_ "Platform_VMCU1_Sig" SG_ 847 PanicAlarmFromKeyfob_rqst 1;
BA_ "GenSigCycleTime" SG_ 847 ParkingClimate_IndicationCmd_ISi 100;
BA_ "GenSigCycleTimeActive" SG_ 847 ParkingClimate_IndicationCmd_ISi 100;
BA_ "GenSigStartValue" SG_ 847 ParkingClimate_IndicationCmd_ISi 7;
BA_ "Platform_VMCU1_Sig" SG_ 847 ParkingClimate_IndicationCmd_ISi 1;
BA_ "SystemSignalLongSymbol" SG_ 847 ParkingClimate_IndicationCmd_ISi "ParkingClimate_IndicationCmd_ISig_4";
BA_ "GenSigCycleTime" SG_ 847 MirrorSelectLeftWideBtn_stat_ISi 100;
BA_ "GenSigCycleTimeActive" SG_ 847 MirrorSelectLeftWideBtn_stat_ISi 100;
BA_ "GenSigStartValue" SG_ 847 MirrorSelectLeftWideBtn_stat_ISi 3;
BA_ "GenSigMaxLatency" SG_ 847 MirrorSelectLeftWideBtn_stat_ISi 66;
BA_ "Platform_VMCU1_Sig" SG_ 847 MirrorSelectLeftWideBtn_stat_ISi 1;
BA_ "SeToolAncestorID_SIGNAL" SG_ 847 MirrorSelectLeftWideBtn_stat_ISi "x0000001D0423D932";
BA_ "SeToolItemID_SIGNAL" SG_ 847 MirrorSelectLeftWideBtn_stat_ISi "x0000001D0429669B";
BA_ "SeToolName_SIGNAL" SG_ 847 MirrorSelectLeftWideBtn_stat_ISi "EM_MirrorselectLeftWide_ButtonStatus";
BA_ "SeToolVersion_SIGNAL" SG_ 847 MirrorSelectLeftWideBtn_stat_ISi "4";
BA_ "SystemSignalLongSymbol" SG_ 847 MirrorSelectLeftWideBtn_stat_ISi "MirrorSelectLeftWideBtn_stat_ISig_4";
BA_ "GenSigCycleTime" SG_ 847 WRCEngineStartRequest_ISig_4 100;
BA_ "GenSigCycleTimeActive" SG_ 847 WRCEngineStartRequest_ISig_4 100;
BA_ "GenSigStartValue" SG_ 847 WRCEngineStartRequest_ISig_4 3;
BA_ "GenSigMaxLatency" SG_ 847 WRCEngineStartRequest_ISig_4 28;
BA_ "NeedsUpdateBit" SG_ 847 WRCEngineStartRequest_ISig_4 1;
BA_ "Platform_VMCU1_Sig" SG_ 847 WRCEngineStartRequest_ISig_4 1;
BA_ "GenSigCycleTime" SG_ 847 PW_Left_DS_SwStatus_ISig_4 100;
BA_ "GenSigCycleTimeActive" SG_ 847 PW_Left_DS_SwStatus_ISig_4 100;
BA_ "GenSigStartValue" SG_ 847 PW_Left_DS_SwStatus_ISig_4 7;
BA_ "GenSigMaxLatency" SG_ 847 PW_Left_DS_SwStatus_ISig_4 66;
BA_ "Platform_VMCU1_Sig" SG_ 847 PW_Left_DS_SwStatus_ISig_4 1;
BA_ "GenSigCycleTime" SG_ 847 RegenerationSwitchStatus 100;
BA_ "GenSigCycleTimeActive" SG_ 847 RegenerationSwitchStatus 100;
BA_ "GenSigStartValue" SG_ 847 RegenerationSwitchStatus 7;
BA_ "Platform_VMCU1_Sig" SG_ 847 RegenerationSwitchStatus 1;
BA_ "GenSigCycleTime" SG_ 847 PW_Right_DS_SwStatus_ISig_4 100;
BA_ "GenSigCycleTimeActive" SG_ 847 PW_Right_DS_SwStatus_ISig_4 100;
BA_ "GenSigStartValue" SG_ 847 PW_Right_DS_SwStatus_ISig_4 7;
BA_ "GenSigMaxLatency" SG_ 847 PW_Right_DS_SwStatus_ISig_4 66;
BA_ "Platform_VMCU1_Sig" SG_ 847 PW_Right_DS_SwStatus_ISig_4 1;
BA_ "GenSigCycleTime" SG_ 847 DoorLock_stat_ISig_4 100;
BA_ "GenSigCycleTimeActive" SG_ 847 DoorLock_stat_ISig_4 100;
BA_ "GenSigStartValue" SG_ 847 DoorLock_stat_ISig_4 15;
BA_ "GenSigMaxLatency" SG_ 847 DoorLock_stat_ISig_4 66;
BA_ "Platform_VMCU1_Sig" SG_ 847 DoorLock_stat_ISig_4 1;
BA_ "GenSigSendType" SG_ 847 WRCEngineStartRequest_UB_ISig_4 7;
BA_ "Platform_VMCU1_Sig" SG_ 847 WRCEngineStartRequest_UB_ISig_4 1;
BA_ "GenSigCycleTime" SG_ 847 LuggageAjar_stat 100;
BA_ "GenSigCycleTimeActive" SG_ 847 LuggageAjar_stat 100;
BA_ "GenSigStartValue" SG_ 847 LuggageAjar_stat 7;
BA_ "Platform_VMCU1_Sig" SG_ 847 LuggageAjar_stat 1;
BA_ "GenSigCycleTime" SG_ 847 AlarmStatus_stat_ISig_4 100;
BA_ "GenSigCycleTimeActive" SG_ 847 AlarmStatus_stat_ISig_4 100;
BA_ "GenSigStartValue" SG_ 847 AlarmStatus_stat_ISig_4 15;
BA_ "Platform_VMCU1_Sig" SG_ 847 AlarmStatus_stat_ISig_4 1;
BA_ "GenSigCycleTime" SG_ 847 AlarmTriggeringCause_stat_ISig_4 100;
BA_ "GenSigCycleTimeActive" SG_ 847 AlarmTriggeringCause_stat_ISig_4 100;
BA_ "GenSigStartValue" SG_ 847 AlarmTriggeringCause_stat_ISig_4 15;
BA_ "GenSigMaxLatency" SG_ 847 AlarmTriggeringCause_stat_ISig_4 66;
BA_ "Platform_VMCU1_Sig" SG_ 847 AlarmTriggeringCause_stat_ISig_4 1;
BA_ "GenSigSendType" SG_ 847 DoorsAjar_stat_UB_ISig_4 7;
BA_ "Platform_VMCU1_Sig" SG_ 847 DoorsAjar_stat_UB_ISig_4 1;
BA_ "GenSigCycleTime" SG_ 847 DoorsAjar_stat_ISig_4 100;
BA_ "GenSigCycleTimeActive" SG_ 847 DoorsAjar_stat_ISig_4 100;
BA_ "GenSigStartValue" SG_ 847 DoorsAjar_stat_ISig_4 7;
BA_ "GenSigMaxLatency" SG_ 847 DoorsAjar_stat_ISig_4 66;
BA_ "NeedsUpdateBit" SG_ 847 DoorsAjar_stat_ISig_4 1;
BA_ "Platform_VMCU1_Sig" SG_ 847 DoorsAjar_stat_ISig_4 1;
BA_ "GenSigSendType" SG_ 847 WRCEngineStopRequest_UB_ISig_4 7;
BA_ "Platform_VMCU1_Sig" SG_ 847 WRCEngineStopRequest_UB_ISig_4 1;
BA_ "GenSigCycleTime" SG_ 847 DoorAutoFunction_rqst 100;
BA_ "GenSigCycleTimeActive" SG_ 847 DoorAutoFunction_rqst 100;
BA_ "GenSigStartValue" SG_ 847 DoorAutoFunction_rqst 3;
BA_ "GenSigMaxLatency" SG_ 847 DoorAutoFunction_rqst 66;
BA_ "Platform_VMCU1_Sig" SG_ 847 DoorAutoFunction_rqst 1;
BA_ "GenSigCycleTime" SG_ 847 MirrorSelectLeftMainBtn_stat_ISi 100;
BA_ "GenSigCycleTimeActive" SG_ 847 MirrorSelectLeftMainBtn_stat_ISi 100;
BA_ "GenSigStartValue" SG_ 847 MirrorSelectLeftMainBtn_stat_ISi 3;
BA_ "GenSigMaxLatency" SG_ 847 MirrorSelectLeftMainBtn_stat_ISi 66;
BA_ "Platform_VMCU1_Sig" SG_ 847 MirrorSelectLeftMainBtn_stat_ISi 1;
BA_ "SeToolAncestorID_SIGNAL" SG_ 847 MirrorSelectLeftMainBtn_stat_ISi "x0000001D0423D932";
BA_ "SeToolItemID_SIGNAL" SG_ 847 MirrorSelectLeftMainBtn_stat_ISi "x0000001D0429669B";
BA_ "SeToolName_SIGNAL" SG_ 847 MirrorSelectLeftMainBtn_stat_ISi "EM_MirrorselectLeftMain_ButtonStatus";
BA_ "SeToolVersion_SIGNAL" SG_ 847 MirrorSelectLeftMainBtn_stat_ISi "4";
BA_ "SystemSignalLongSymbol" SG_ 847 MirrorSelectLeftMainBtn_stat_ISi "MirrorSelectLeftMainBtn_stat_ISig_4";
BA_ "GenSigCycleTime" SG_ 841 FPBRChangeReq_ISig_4 100;
BA_ "GenSigCycleTimeActive" SG_ 841 FPBRChangeReq_ISig_4 100;
BA_ "GenSigStartValue" SG_ 841 FPBRChangeReq_ISig_4 3;
BA_ "Platform_VMCU1_Sig" SG_ 841 FPBRChangeReq_ISig_4 1;
BA_ "GenSigCycleTime" SG_ 841 HeadLampUpDown_SwitchStatus 100;
BA_ "GenSigCycleTimeActive" SG_ 841 HeadLampUpDown_SwitchStatus 100;
BA_ "GenSigStartValue" SG_ 841 HeadLampUpDown_SwitchStatus 7;
BA_ "GenSigMaxLatency" SG_ 841 HeadLampUpDown_SwitchStatus 57;
BA_ "Platform_VMCU1_Sig" SG_ 841 HeadLampUpDown_SwitchStatus 1;
BA_ "GenSigCycleTime" SG_ 841 Recirc_ButtonStatus_ISig_4 100;
BA_ "GenSigCycleTimeActive" SG_ 841 Recirc_ButtonStatus_ISig_4 100;
BA_ "GenSigStartValue" SG_ 841 Recirc_ButtonStatus_ISig_4 3;
BA_ "GenSigMaxLatency" SG_ 841 Recirc_ButtonStatus_ISig_4 57;
BA_ "Platform_VMCU1_Sig" SG_ 841 Recirc_ButtonStatus_ISig_4 1;
BA_ "SeToolAncestorID_SIGNAL" SG_ 841 Recirc_ButtonStatus_ISig_4 "x0000001D0423D932";
BA_ "SeToolItemID_SIGNAL" SG_ 841 Recirc_ButtonStatus_ISig_4 "x0000001D0429669B";
BA_ "SeToolName_SIGNAL" SG_ 841 Recirc_ButtonStatus_ISig_4 "Recirc_ButtonStatus";
BA_ "SeToolVersion_SIGNAL" SG_ 841 Recirc_ButtonStatus_ISig_4 "4";
BA_ "GenSigCycleTime" SG_ 841 Auto_ButtonStatus_ISig_4 100;
BA_ "GenSigCycleTimeActive" SG_ 841 Auto_ButtonStatus_ISig_4 100;
BA_ "GenSigStartValue" SG_ 841 Auto_ButtonStatus_ISig_4 3;
BA_ "GenSigMaxLatency" SG_ 841 Auto_ButtonStatus_ISig_4 57;
BA_ "Platform_VMCU1_Sig" SG_ 841 Auto_ButtonStatus_ISig_4 1;
BA_ "SeToolAncestorID_SIGNAL" SG_ 841 Auto_ButtonStatus_ISig_4 "x0000001D0423D932";
BA_ "SeToolItemID_SIGNAL" SG_ 841 Auto_ButtonStatus_ISig_4 "x0000001D0429669B";
BA_ "SeToolName_SIGNAL" SG_ 841 Auto_ButtonStatus_ISig_4 "Auto_ButtonStatus";
BA_ "SeToolVersion_SIGNAL" SG_ 841 Auto_ButtonStatus_ISig_4 "4";
BA_ "GenSigCycleTime" SG_ 841 AirFlowSelectionFrontBtn_stat_IS 100;
BA_ "GenSigCycleTimeActive" SG_ 841 AirFlowSelectionFrontBtn_stat_IS 100;
BA_ "GenSigStartValue" SG_ 841 AirFlowSelectionFrontBtn_stat_IS 3;
BA_ "GenSigMaxLatency" SG_ 841 AirFlowSelectionFrontBtn_stat_IS 57;
BA_ "Platform_VMCU1_Sig" SG_ 841 AirFlowSelectionFrontBtn_stat_IS 1;
BA_ "SeToolAncestorID_SIGNAL" SG_ 841 AirFlowSelectionFrontBtn_stat_IS "x0000001D0423D932";
BA_ "SeToolItemID_SIGNAL" SG_ 841 AirFlowSelectionFrontBtn_stat_IS "x0000001D0429669B";
BA_ "SeToolName_SIGNAL" SG_ 841 AirFlowSelectionFrontBtn_stat_IS "AirFlowSelectionFront_ButtonStatus";
BA_ "SeToolVersion_SIGNAL" SG_ 841 AirFlowSelectionFrontBtn_stat_IS "4";
BA_ "SystemSignalLongSymbol" SG_ 841 AirFlowSelectionFrontBtn_stat_IS "AirFlowSelectionFrontBtn_stat_ISig_4";
BA_ "GenSigCycleTime" SG_ 841 InteriorLightMode_rqst_IL_Mode 100;
BA_ "GenSigCycleTimeActive" SG_ 841 InteriorLightMode_rqst_IL_Mode 100;
BA_ "GenSigStartValue" SG_ 841 InteriorLightMode_rqst_IL_Mode 7;
BA_ "Platform_VMCU1_Sig" SG_ 841 InteriorLightMode_rqst_IL_Mode 1;
BA_ "GenSigCycleTime" SG_ 841 InteriorLightMode_rqst_EventFlag 100;
BA_ "GenSigCycleTimeActive" SG_ 841 InteriorLightMode_rqst_EventFlag 100;
BA_ "Platform_VMCU1_Sig" SG_ 841 InteriorLightMode_rqst_EventFlag 1;
BA_ "GenSigCycleTime" SG_ 841 BlackOutConvoyModeSwitchStatus 100;
BA_ "GenSigCycleTimeActive" SG_ 841 BlackOutConvoyModeSwitchStatus 100;
BA_ "GenSigStartValue" SG_ 841 BlackOutConvoyModeSwitchStatus 7;
BA_ "GenSigMaxLatency" SG_ 841 BlackOutConvoyModeSwitchStatus 57;
BA_ "Platform_VMCU1_Sig" SG_ 841 BlackOutConvoyModeSwitchStatus 1;
BA_ "GenSigCycleTime" SG_ 841 Indicator_Lights_Alarm_rqst_ISig 100;
BA_ "GenSigCycleTimeActive" SG_ 841 Indicator_Lights_Alarm_rqst_ISig 100;
BA_ "GenSigStartValue" SG_ 841 Indicator_Lights_Alarm_rqst_ISig 7;
BA_ "GenSigMaxLatency" SG_ 841 Indicator_Lights_Alarm_rqst_ISig 57;
BA_ "Platform_VMCU1_Sig" SG_ 841 Indicator_Lights_Alarm_rqst_ISig 1;
BA_ "SystemSignalLongSymbol" SG_ 841 Indicator_Lights_Alarm_rqst_ISig "Indicator_Lights_Alarm_rqst_ISig_4";
BA_ "GenSigCycleTime" SG_ 841 AirFlowSelectionDownBtn_stat_ISi 100;
BA_ "GenSigCycleTimeActive" SG_ 841 AirFlowSelectionDownBtn_stat_ISi 100;
BA_ "GenSigStartValue" SG_ 841 AirFlowSelectionDownBtn_stat_ISi 3;
BA_ "GenSigMaxLatency" SG_ 841 AirFlowSelectionDownBtn_stat_ISi 57;
BA_ "Platform_VMCU1_Sig" SG_ 841 AirFlowSelectionDownBtn_stat_ISi 1;
BA_ "SeToolAncestorID_SIGNAL" SG_ 841 AirFlowSelectionDownBtn_stat_ISi "x0000001D0423D932";
BA_ "SeToolItemID_SIGNAL" SG_ 841 AirFlowSelectionDownBtn_stat_ISi "x0000001D0429669B";
BA_ "SeToolName_SIGNAL" SG_ 841 AirFlowSelectionDownBtn_stat_ISi "AirFlowSelectionDown_ButtonStatus";
BA_ "SeToolVersion_SIGNAL" SG_ 841 AirFlowSelectionDownBtn_stat_ISi "4";
BA_ "SystemSignalLongSymbol" SG_ 841 AirFlowSelectionDownBtn_stat_ISi "AirFlowSelectionDownBtn_stat_ISig_4";
BA_ "GenSigCycleTime" SG_ 841 ParkingHeater_IndicationCmd_ISig 100;
BA_ "GenSigCycleTimeActive" SG_ 841 ParkingHeater_IndicationCmd_ISig 100;
BA_ "GenSigMaxLatency" SG_ 841 ParkingHeater_IndicationCmd_ISig 57;
BA_ "Platform_VMCU1_Sig" SG_ 841 ParkingHeater_IndicationCmd_ISig 1;
BA_ "SystemSignalLongSymbol" SG_ 841 ParkingHeater_IndicationCmd_ISig "ParkingHeater_IndicationCmd_ISig_4";
BA_ "GenSigCycleTime" SG_ 841 AirFlowSelectionUpBtn_stat_ISig_ 100;
BA_ "GenSigCycleTimeActive" SG_ 841 AirFlowSelectionUpBtn_stat_ISig_ 100;
BA_ "GenSigStartValue" SG_ 841 AirFlowSelectionUpBtn_stat_ISig_ 3;
BA_ "GenSigMaxLatency" SG_ 841 AirFlowSelectionUpBtn_stat_ISig_ 57;
BA_ "Platform_VMCU1_Sig" SG_ 841 AirFlowSelectionUpBtn_stat_ISig_ 1;
BA_ "SeToolAncestorID_SIGNAL" SG_ 841 AirFlowSelectionUpBtn_stat_ISig_ "x0000001D0423D932";
BA_ "SeToolItemID_SIGNAL" SG_ 841 AirFlowSelectionUpBtn_stat_ISig_ "x0000001D0429669B";
BA_ "SeToolName_SIGNAL" SG_ 841 AirFlowSelectionUpBtn_stat_ISig_ "AirFlowSelectionUp_ButtonStatus";
BA_ "SeToolVersion_SIGNAL" SG_ 841 AirFlowSelectionUpBtn_stat_ISig_ "4";
BA_ "SystemSignalLongSymbol" SG_ 841 AirFlowSelectionUpBtn_stat_ISig_ "AirFlowSelectionUpBtn_stat_ISig_4";
BA_ "GenSigCycleTime" SG_ 841 ApproachLight_HMI_rqst 100;
BA_ "GenSigCycleTimeActive" SG_ 841 ApproachLight_HMI_rqst 100;
BA_ "GenSigStartValue" SG_ 841 ApproachLight_HMI_rqst 3;
BA_ "GenSigMaxLatency" SG_ 841 ApproachLight_HMI_rqst 57;
BA_ "Platform_VMCU1_Sig" SG_ 841 ApproachLight_HMI_rqst 1;
BA_ "GenSigCycleTime" SG_ 841 Temperature_FreeWheelStatus_ISig 100;
BA_ "GenSigCycleTimeActive" SG_ 841 Temperature_FreeWheelStatus_ISig 100;
BA_ "GenSigStartValue" SG_ 841 Temperature_FreeWheelStatus_ISig 15;
BA_ "GenSigMaxLatency" SG_ 841 Temperature_FreeWheelStatus_ISig 57;
BA_ "Platform_VMCU1_Sig" SG_ 841 Temperature_FreeWheelStatus_ISig 1;
BA_ "SeToolAncestorID_SIGNAL" SG_ 841 Temperature_FreeWheelStatus_ISig "x0000001D0425F9AD";
BA_ "SeToolItemID_SIGNAL" SG_ 841 Temperature_FreeWheelStatus_ISig "x0000001D043FC230";
BA_ "SeToolName_SIGNAL" SG_ 841 Temperature_FreeWheelStatus_ISig "Temperature_FreeWheelStatus";
BA_ "SeToolVersion_SIGNAL" SG_ 841 Temperature_FreeWheelStatus_ISig "3";
BA_ "SystemSignalLongSymbol" SG_ 841 Temperature_FreeWheelStatus_ISig "Temperature_FreeWheelStatus_ISig_4";
BA_ "GenSigCycleTime" SG_ 841 AirBlowerSpeed_FreeWheelStatus_I 100;
BA_ "GenSigCycleTimeActive" SG_ 841 AirBlowerSpeed_FreeWheelStatus_I 100;
BA_ "GenSigStartValue" SG_ 841 AirBlowerSpeed_FreeWheelStatus_I 15;
BA_ "GenSigMaxLatency" SG_ 841 AirBlowerSpeed_FreeWheelStatus_I 57;
BA_ "Platform_VMCU1_Sig" SG_ 841 AirBlowerSpeed_FreeWheelStatus_I 1;
BA_ "SeToolAncestorID_SIGNAL" SG_ 841 AirBlowerSpeed_FreeWheelStatus_I "x0000001D0425F9AD";
BA_ "SeToolItemID_SIGNAL" SG_ 841 AirBlowerSpeed_FreeWheelStatus_I "x0000001D043FC230";
BA_ "SeToolName_SIGNAL" SG_ 841 AirBlowerSpeed_FreeWheelStatus_I "AirBlowerSpeed_FreeWheelStatus";
BA_ "SeToolVersion_SIGNAL" SG_ 841 AirBlowerSpeed_FreeWheelStatus_I "3";
BA_ "SystemSignalLongSymbol" SG_ 841 AirBlowerSpeed_FreeWheelStatus_I "AirBlowerSpeed_FreeWheelStatus_ISig_4";
BA_ "GenSigCycleTime" SG_ 841 CabInteriorTempVentilated_Stat_I 100;
BA_ "GenSigCycleTimeActive" SG_ 841 CabInteriorTempVentilated_Stat_I 100;
BA_ "GenSigStartValue" SG_ 841 CabInteriorTempVentilated_Stat_I 1023;
BA_ "GenSigMaxLatency" SG_ 841 CabInteriorTempVentilated_Stat_I 57;
BA_ "Platform_VMCU1_Sig" SG_ 841 CabInteriorTempVentilated_Stat_I 1;
BA_ "SeToolAncestorID_SIGNAL" SG_ 841 CabInteriorTempVentilated_Stat_I "x0000001D043C9954";
BA_ "SeToolItemID_SIGNAL" SG_ 841 CabInteriorTempVentilated_Stat_I "x0000001D043C9954";
BA_ "SeToolName_SIGNAL" SG_ 841 CabInteriorTempVentilated_Stat_I "CabInteriorTempVentilated_Stat";
BA_ "SeToolVersion_SIGNAL" SG_ 841 CabInteriorTempVentilated_Stat_I "1";
BA_ "SystemSignalLongSymbol" SG_ 841 CabInteriorTempVentilated_Stat_I "CabInteriorTempVentilated_Stat_ISig_4";
BA_ "GenSigCycleTime" SG_ 841 PreTrip_ButtonStat3 100;
BA_ "GenSigCycleTimeActive" SG_ 841 PreTrip_ButtonStat3 100;
BA_ "GenSigStartValue" SG_ 841 PreTrip_ButtonStat3 3;
BA_ "GenSigCycleTime" SG_ 841 ParkHeaterCooler_ButtonStatus_IS 100;
BA_ "GenSigCycleTimeActive" SG_ 841 ParkHeaterCooler_ButtonStatus_IS 100;
BA_ "GenSigStartValue" SG_ 841 ParkHeaterCooler_ButtonStatus_IS 3;
BA_ "GenSigMaxLatency" SG_ 841 ParkHeaterCooler_ButtonStatus_IS 57;
BA_ "Platform_VMCU1_Sig" SG_ 841 ParkHeaterCooler_ButtonStatus_IS 1;
BA_ "SystemSignalLongSymbol" SG_ 841 ParkHeaterCooler_ButtonStatus_IS "ParkHeaterCooler_ButtonStatus_ISig_4";
BA_ "GenSigCycleTime" SG_ 841 WindscreenDefrost_ButtonStatus_I 100;
BA_ "GenSigCycleTimeActive" SG_ 841 WindscreenDefrost_ButtonStatus_I 100;
BA_ "GenSigStartValue" SG_ 841 WindscreenDefrost_ButtonStatus_I 3;
BA_ "GenSigMaxLatency" SG_ 841 WindscreenDefrost_ButtonStatus_I 57;
BA_ "Platform_VMCU1_Sig" SG_ 841 WindscreenDefrost_ButtonStatus_I 1;
BA_ "SeToolAncestorID_SIGNAL" SG_ 841 WindscreenDefrost_ButtonStatus_I "x0000001D0423D932";
BA_ "SeToolItemID_SIGNAL" SG_ 841 WindscreenDefrost_ButtonStatus_I "x0000001D0429669B";
BA_ "SeToolName_SIGNAL" SG_ 841 WindscreenDefrost_ButtonStatus_I "WindscreenDefroster_ButtonStatus";
BA_ "SeToolVersion_SIGNAL" SG_ 841 WindscreenDefrost_ButtonStatus_I "4";
BA_ "SystemSignalLongSymbol" SG_ 841 WindscreenDefrost_ButtonStatus_I "WindscreenDefrost_ButtonStatus_ISig_4";
BA_ "GenSigCycleTime" SG_ 841 AC_ButtonStatus_ISig_4 100;
BA_ "GenSigCycleTimeActive" SG_ 841 AC_ButtonStatus_ISig_4 100;
BA_ "GenSigStartValue" SG_ 841 AC_ButtonStatus_ISig_4 3;
BA_ "GenSigMaxLatency" SG_ 841 AC_ButtonStatus_ISig_4 57;
BA_ "Platform_VMCU1_Sig" SG_ 841 AC_ButtonStatus_ISig_4 1;
BA_ "SeToolAncestorID_SIGNAL" SG_ 841 AC_ButtonStatus_ISig_4 "x0000001D0423D932";
BA_ "SeToolItemID_SIGNAL" SG_ 841 AC_ButtonStatus_ISig_4 "x0000001D0429669B";
BA_ "SeToolName_SIGNAL" SG_ 841 AC_ButtonStatus_ISig_4 "AC_ButtonStatus";
BA_ "SeToolVersion_SIGNAL" SG_ 841 AC_ButtonStatus_ISig_4 "4";
BA_REL_ "GenSigFirstTimeoutTime" BU_SG_REL_ VMCU SG_ 528 FASHapticFeedbackRequest_ISig_4 3000;
BA_REL_ "GenSigTimeoutTime" BU_SG_REL_ VMCU SG_ 528 FASHapticFeedbackRequest_ISig_4 120;
BA_REL_ "GenSigFirstTimeoutTime" BU_SG_REL_ VMCU SG_ 528 FASCurvatureRequest_ISig_4 3000;
BA_REL_ "GenSigTimeoutTime" BU_SG_REL_ VMCU SG_ 528 FASCurvatureRequest_ISig_4 120;
BA_REL_ "GenSigFirstTimeoutTime" BU_SG_REL_ VMCU SG_ 528 FASControlMode_ISig_4 3000;
BA_REL_ "GenSigTimeoutTime" BU_SG_REL_ VMCU SG_ 528 FASControlMode_ISig_4 120;
BA_REL_ "GenSigFirstTimeoutTime" BU_SG_REL_ VMCU SG_ 528 FASExtCtrlMsgChecksum_ISig_4 3000;
BA_REL_ "GenSigTimeoutTime" BU_SG_REL_ VMCU SG_ 528 FASExtCtrlMsgChecksum_ISig_4 120;
BA_REL_ "GenSigFirstTimeoutTime" BU_SG_REL_ VMCU SG_ 528 ReferencePathCurvature_ISig_4 3000;
BA_REL_ "GenSigTimeoutTime" BU_SG_REL_ VMCU SG_ 528 ReferencePathCurvature_ISig_4 120;
BA_REL_ "GenSigFirstTimeoutTime" BU_SG_REL_ VMCU SG_ 528 FASExtCtrlMsgCounter_ISig_4 3000;
BA_REL_ "GenSigTimeoutTime" BU_SG_REL_ VMCU SG_ 528 FASExtCtrlMsgCounter_ISig_4 120;
BA_REL_ "GenSigFirstTimeoutTime" BU_SG_REL_ VMCU SG_ 528 FASRoadWheelAngleRequest_ISig_4 3000;
BA_REL_ "GenSigTimeoutTime" BU_SG_REL_ VMCU SG_ 528 FASRoadWheelAngleRequest_ISig_4 120;
BA_REL_ "GenSigFirstTimeoutTime" BU_SG_REL_ IC3 SG_ 524 TSAMIntervntionCapabilityLeft 3000;
BA_REL_ "GenSigTimeoutTime" BU_SG_REL_ IC3 SG_ 524 TSAMIntervntionCapabilityLeft 120;
BA_REL_ "GenSigFirstTimeoutTime" BU_SG_REL_ IC3 SG_ 524 TSAMIntervntionCapabilityRight 3000;
BA_REL_ "GenSigTimeoutTime" BU_SG_REL_ IC3 SG_ 524 TSAMIntervntionCapabilityRight 120;
BA_REL_ "GenSigFirstTimeoutTime" BU_SG_REL_ VMCU SG_ 524 GlareFreeArea02_LeftAngle_ISig_4 3000;
BA_REL_ "GenSigTimeoutTime" BU_SG_REL_ VMCU SG_ 524 GlareFreeArea02_LeftAngle_ISig_4 120;
BA_REL_ "GenSigFirstTimeoutTime" BU_SG_REL_ VMCU SG_ 524 GlareFreeArea02_RightAngle_ISig_ 3000;
BA_REL_ "GenSigTimeoutTime" BU_SG_REL_ VMCU SG_ 524 GlareFreeArea02_RightAngle_ISig_ 120;
BA_REL_ "GenSigFirstTimeoutTime" BU_SG_REL_ IC3 SG_ 524 PathDeviationSteeringStatus 3000;
BA_REL_ "GenSigTimeoutTime" BU_SG_REL_ IC3 SG_ 524 PathDeviationSteeringStatus 120;
BA_REL_ "GenSigFirstTimeoutTime" BU_SG_REL_ VMCU SG_ 524 GlareFreeArea02_Distance_ISig_4 3000;
BA_REL_ "GenSigTimeoutTime" BU_SG_REL_ VMCU SG_ 524 GlareFreeArea02_Distance_ISig_4 120;
BA_REL_ "GenSigFirstTimeoutTime" BU_SG_REL_ VMCU SG_ 522 GlareFreeArea01_LeftAngle_ISig_4 3000;
BA_REL_ "GenSigTimeoutTime" BU_SG_REL_ VMCU SG_ 522 GlareFreeArea01_LeftAngle_ISig_4 120;
BA_REL_ "GenSigFirstTimeoutTime" BU_SG_REL_ VMCU SG_ 522 GlareFreeArea03_Distance_ISig_4 3000;
BA_REL_ "GenSigTimeoutTime" BU_SG_REL_ VMCU SG_ 522 GlareFreeArea03_Distance_ISig_4 120;
BA_REL_ "GenSigFirstTimeoutTime" BU_SG_REL_ VMCU SG_ 522 GlareFreeArea03_LeftAngle_ISig_4 3000;
BA_REL_ "GenSigTimeoutTime" BU_SG_REL_ VMCU SG_ 522 GlareFreeArea03_LeftAngle_ISig_4 120;
BA_REL_ "GenSigFirstTimeoutTime" BU_SG_REL_ VMCU SG_ 522 GlareFreeArea03_RightAngle_ISig_ 3000;
BA_REL_ "GenSigTimeoutTime" BU_SG_REL_ VMCU SG_ 522 GlareFreeArea03_RightAngle_ISig_ 120;
BA_REL_ "GenSigFirstTimeoutTime" BU_SG_REL_ VMCU SG_ 522 GlareFreeArea01_Distance_ISig_4 3000;
BA_REL_ "GenSigTimeoutTime" BU_SG_REL_ VMCU SG_ 522 GlareFreeArea01_Distance_ISig_4 120;
BA_REL_ "GenSigFirstTimeoutTime" BU_SG_REL_ VMCU SG_ 522 GlareFreeArea01_RightAngle_ISig_ 3000;
BA_REL_ "GenSigTimeoutTime" BU_SG_REL_ VMCU SG_ 522 GlareFreeArea01_RightAngle_ISig_ 120;
BA_REL_ "GenSigFirstTimeoutTime" BU_SG_REL_ VMCU SG_ 946 PSC_RequestedPresetSpeed 3000;
BA_REL_ "GenSigTimeoutTime" BU_SG_REL_ VMCU SG_ 946 PSC_RequestedPresetSpeed 600;
BA_REL_ "GenSigFirstTimeoutTime" BU_SG_REL_ IC3 SG_ 946 CACCStatus 3000;
BA_REL_ "GenSigTimeoutTime" BU_SG_REL_ IC3 SG_ 946 CACCStatus 600;
BA_REL_ "GenSigFirstTimeoutTime" BU_SG_REL_ TECU SG_ 946 CACCStatus 3000;
BA_REL_ "GenSigTimeoutTime" BU_SG_REL_ TECU SG_ 946 CACCStatus 600;
BA_REL_ "GenSigFirstTimeoutTime" BU_SG_REL_ VMCU SG_ 946 PSC_DriverBrakingAllowed 3000;
BA_REL_ "GenSigTimeoutTime" BU_SG_REL_ VMCU SG_ 946 PSC_DriverBrakingAllowed 600;
BA_REL_ "GenSigFirstTimeoutTime" BU_SG_REL_ IC3 SG_ 946 TrafficSituationCriticality 3000;
BA_REL_ "GenSigTimeoutTime" BU_SG_REL_ IC3 SG_ 946 TrafficSituationCriticality 600;
BA_REL_ "GenSigFirstTimeoutTime" BU_SG_REL_ VMCU SG_ 946 VisionLight_stat 3000;
BA_REL_ "GenSigTimeoutTime" BU_SG_REL_ VMCU SG_ 946 VisionLight_stat 600;
BA_REL_ "GenSigFirstTimeoutTime" BU_SG_REL_ BBM SG_ 946 BBSteeringStatus 3000;
BA_REL_ "GenSigTimeoutTime" BU_SG_REL_ BBM SG_ 946 BBSteeringStatus 600;
BA_REL_ "GenSigFirstTimeoutTime" BU_SG_REL_ VMCU SG_ 946 PSC_SetSpeedChangeRqst 3000;
BA_REL_ "GenSigTimeoutTime" BU_SG_REL_ VMCU SG_ 946 PSC_SetSpeedChangeRqst 600;
BA_REL_ "GenSigFirstTimeoutTime" BU_SG_REL_ TECU SG_ 946 ACCiSeeDistanceGap 3000;
BA_REL_ "GenSigTimeoutTime" BU_SG_REL_ TECU SG_ 946 ACCiSeeDistanceGap 600;
BA_REL_ "GenSigFirstTimeoutTime" BU_SG_REL_ VMCU SG_ 946 LSMS_SpeedLimit 3000;
BA_REL_ "GenSigTimeoutTime" BU_SG_REL_ VMCU SG_ 946 LSMS_SpeedLimit 600;
BA_REL_ "GenSigFirstTimeoutTime" BU_SG_REL_ IC3 SG_ 744 ForwardLookingCameraStatus_ISig_ 3000;
BA_REL_ "GenSigTimeoutTime" BU_SG_REL_ IC3 SG_ 744 ForwardLookingCameraStatus_ISig_ 240;
BA_REL_ "GenSigFirstTimeoutTime" BU_SG_REL_ EMS SG_ 744 XARDACU_ControlMode 3000;
BA_REL_ "GenSigTimeoutTime" BU_SG_REL_ EMS SG_ 744 XARDACU_ControlMode 240;
BA_REL_ "GenSigFirstTimeoutTime" BU_SG_REL_ TECU SG_ 744 XARDACU_ControlMode 3000;
BA_REL_ "GenSigTimeoutTime" BU_SG_REL_ TECU SG_ 744 XARDACU_ControlMode 240;
BA_REL_ "GenSigFirstTimeoutTime" BU_SG_REL_ TECU SG_ 744 ACCiRollInhibit 3000;
BA_REL_ "GenSigTimeoutTime" BU_SG_REL_ TECU SG_ 744 ACCiRollInhibit 240;
BA_REL_ "GenSigFirstTimeoutTime" BU_SG_REL_ IC3 SG_ 744 CMReducedAbilityStatus 3000;
BA_REL_ "GenSigTimeoutTime" BU_SG_REL_ IC3 SG_ 744 CMReducedAbilityStatus 240;
BA_REL_ "GenSigFirstTimeoutTime" BU_SG_REL_ VMCU SG_ 744 CollisionSituationAliveAck 3000;
BA_REL_ "GenSigTimeoutTime" BU_SG_REL_ VMCU SG_ 744 CollisionSituationAliveAck 240;
BA_REL_ "GenSigFirstTimeoutTime" BU_SG_REL_ IC3 SG_ 744 ForwardLookingRadarStatus_ISig_4 3000;
BA_REL_ "GenSigTimeoutTime" BU_SG_REL_ IC3 SG_ 744 ForwardLookingRadarStatus_ISig_4 240;
BA_REL_ "GenSigFirstTimeoutTime" BU_SG_REL_ VMCU SG_ 744 XPRRequest_CM_ISig_4 3000;
BA_REL_ "GenSigTimeoutTime" BU_SG_REL_ VMCU SG_ 744 XPRRequest_CM_ISig_4 240;
BA_REL_ "GenSigFirstTimeoutTime" BU_SG_REL_ IC3 SG_ 744 LPOSBlocked 3000;
BA_REL_ "GenSigTimeoutTime" BU_SG_REL_ IC3 SG_ 744 LPOSBlocked 240;
BA_REL_ "GenSigFirstTimeoutTime" BU_SG_REL_ EMS SG_ 744 XARDACU_AccelDemand 3000;
BA_REL_ "GenSigTimeoutTime" BU_SG_REL_ EMS SG_ 744 XARDACU_AccelDemand 240;
BA_REL_ "GenSigFirstTimeoutTime" BU_SG_REL_ TECU SG_ 744 XARDACU_AccelDemand 3000;
BA_REL_ "GenSigTimeoutTime" BU_SG_REL_ TECU SG_ 744 XARDACU_AccelDemand 240;
BA_REL_ "GenSigFirstTimeoutTime" BU_SG_REL_ VMCU SG_ 744 CollSituationHazardLightReq 3000;
BA_REL_ "GenSigTimeoutTime" BU_SG_REL_ VMCU SG_ 744 CollSituationHazardLightReq 240;
BA_REL_ "GenSigFirstTimeoutTime" BU_SG_REL_ IC3 SG_ 560 PathDeviationDriverAlert 3000;
BA_REL_ "GenSigTimeoutTime" BU_SG_REL_ IC3 SG_ 560 PathDeviationDriverAlert 240;
BA_REL_ "GenSigFirstTimeoutTime" BU_SG_REL_ VMCU SG_ 560 PathDeviationDriverAlert 3000;
BA_REL_ "GenSigTimeoutTime" BU_SG_REL_ VMCU SG_ 560 PathDeviationDriverAlert 240;
BA_REL_ "GenSigFirstTimeoutTime" BU_SG_REL_ TECU SG_ 560 CM_DisengageDrivelineRequest 3000;
BA_REL_ "GenSigTimeoutTime" BU_SG_REL_ TECU SG_ 560 CM_DisengageDrivelineRequest 240;
BA_REL_ "GenSigFirstTimeoutTime" BU_SG_REL_ VMCU SG_ 560 ACCBrakeRequestStatus 3000;
BA_REL_ "GenSigTimeoutTime" BU_SG_REL_ VMCU SG_ 560 ACCBrakeRequestStatus 240;
BA_REL_ "GenSigFirstTimeoutTime" BU_SG_REL_ IC3 SG_ 560 FrontalCollisionDriverAlert_ISig 3000;
BA_REL_ "GenSigTimeoutTime" BU_SG_REL_ IC3 SG_ 560 FrontalCollisionDriverAlert_ISig 240;
BA_REL_ "GenSigFirstTimeoutTime" BU_SG_REL_ VMCU SG_ 560 FrontalCollisionDriverAlert_ISig 3000;
BA_REL_ "GenSigTimeoutTime" BU_SG_REL_ VMCU SG_ 560 FrontalCollisionDriverAlert_ISig 120;
BA_REL_ "GenSigFirstTimeoutTime" BU_SG_REL_ IC3 SG_ 560 ACC_SGOFaultCondStat_SeatBelt 3000;
BA_REL_ "GenSigTimeoutTime" BU_SG_REL_ IC3 SG_ 560 ACC_SGOFaultCondStat_SeatBelt 240;
BA_REL_ "GenSigFirstTimeoutTime" BU_SG_REL_ CIOM SG_ 560 CM_Status_ISig_4 3000;
BA_REL_ "GenSigTimeoutTime" BU_SG_REL_ CIOM SG_ 560 CM_Status_ISig_4 240;
BA_REL_ "GenSigFirstTimeoutTime" BU_SG_REL_ VMCU SG_ 560 CM_Status_ISig_4 3000;
BA_REL_ "GenSigTimeoutTime" BU_SG_REL_ VMCU SG_ 560 CM_Status_ISig_4 240;
BA_REL_ "GenSigFirstTimeoutTime" BU_SG_REL_ IC3 SG_ 560 CM_Status_ISig_4 3000;
BA_REL_ "GenSigTimeoutTime" BU_SG_REL_ IC3 SG_ 560 CM_Status_ISig_4 240;
BA_REL_ "GenSigFirstTimeoutTime" BU_SG_REL_ IC3 SG_ 560 DASApplicationStatus_ISig_4 3000;
BA_REL_ "GenSigTimeoutTime" BU_SG_REL_ IC3 SG_ 560 DASApplicationStatus_ISig_4 240;
BA_REL_ "GenSigFirstTimeoutTime" BU_SG_REL_ VMCU SG_ 560 DASApplicationStatus_ISig_4 3000;
BA_REL_ "GenSigTimeoutTime" BU_SG_REL_ VMCU SG_ 560 DASApplicationStatus_ISig_4 120;
BA_REL_ "GenSigFirstTimeoutTime" BU_SG_REL_ CIOM SG_ 560 DASApplicationStatus_ISig_4 3000;
BA_REL_ "GenSigTimeoutTime" BU_SG_REL_ CIOM SG_ 560 DASApplicationStatus_ISig_4 240;
BA_REL_ "GenSigFirstTimeoutTime" BU_SG_REL_ VMCU SG_ 560 ACC_Status 3000;
BA_REL_ "GenSigTimeoutTime" BU_SG_REL_ VMCU SG_ 560 ACC_Status 240;
BA_REL_ "GenSigFirstTimeoutTime" BU_SG_REL_ IC3 SG_ 560 ACC_Status 3000;
BA_REL_ "GenSigTimeoutTime" BU_SG_REL_ IC3 SG_ 560 ACC_Status 240;
BA_REL_ "GenSigFirstTimeoutTime" BU_SG_REL_ TECU SG_ 560 ACC_Status 3000;
BA_REL_ "GenSigTimeoutTime" BU_SG_REL_ TECU SG_ 560 ACC_Status 240;
BA_REL_ "GenSigFirstTimeoutTime" BU_SG_REL_ CIOM SG_ 560 LKSApplicationStatus_ISig_4 3000;
BA_REL_ "GenSigTimeoutTime" BU_SG_REL_ CIOM SG_ 560 LKSApplicationStatus_ISig_4 240;
BA_REL_ "GenSigFirstTimeoutTime" BU_SG_REL_ VMCU SG_ 560 LKSApplicationStatus_ISig_4 3000;
BA_REL_ "GenSigTimeoutTime" BU_SG_REL_ VMCU SG_ 560 LKSApplicationStatus_ISig_4 120;
BA_REL_ "GenSigFirstTimeoutTime" BU_SG_REL_ IC3 SG_ 560 LKSApplicationStatus_ISig_4 3000;
BA_REL_ "GenSigTimeoutTime" BU_SG_REL_ IC3 SG_ 560 LKSApplicationStatus_ISig_4 240;
BA_REL_ "GenSigFirstTimeoutTime" BU_SG_REL_ IC3 SG_ 560 LCSSystemStatus 3000;
BA_REL_ "GenSigTimeoutTime" BU_SG_REL_ IC3 SG_ 560 LCSSystemStatus 240;
BA_REL_ "GenSigFirstTimeoutTime" BU_SG_REL_ CIOM SG_ 560 LCSSystemStatus 3000;
BA_REL_ "GenSigTimeoutTime" BU_SG_REL_ CIOM SG_ 560 LCSSystemStatus 240;
BA_REL_ "GenSigFirstTimeoutTime" BU_SG_REL_ IC3 SG_ 560 ACC_SGOFaultCondStat_SigStat 3000;
BA_REL_ "GenSigTimeoutTime" BU_SG_REL_ IC3 SG_ 560 ACC_SGOFaultCondStat_SigStat 240;
BA_REL_ "GenSigFirstTimeoutTime" BU_SG_REL_ IC3 SG_ 560 ACC_SGOFaultCondStat_Target 3000;
BA_REL_ "GenSigTimeoutTime" BU_SG_REL_ IC3 SG_ 560 ACC_SGOFaultCondStat_Target 240;
BA_REL_ "GenSigFirstTimeoutTime" BU_SG_REL_ IC3 SG_ 560 FCW_Status 3000;
BA_REL_ "GenSigTimeoutTime" BU_SG_REL_ IC3 SG_ 560 FCW_Status 240;
BA_REL_ "GenSigFirstTimeoutTime" BU_SG_REL_ CIOM SG_ 560 FCW_Status 3000;
BA_REL_ "GenSigTimeoutTime" BU_SG_REL_ CIOM SG_ 560 FCW_Status 240;
BA_REL_ "GenSigFirstTimeoutTime" BU_SG_REL_ VMCU SG_ 560 FCW_Status 3000;
BA_REL_ "GenSigTimeoutTime" BU_SG_REL_ VMCU SG_ 560 FCW_Status 120;
BA_REL_ "GenSigFirstTimeoutTime" BU_SG_REL_ IC3 SG_ 560 DriverImpairedDriverAlert_ISig_4 3000;
BA_REL_ "GenSigTimeoutTime" BU_SG_REL_ IC3 SG_ 560 DriverImpairedDriverAlert_ISig_4 240;
BA_REL_ "GenSigFirstTimeoutTime" BU_SG_REL_ VMCU SG_ 560 DriverImpairedDriverAlert_ISig_4 3000;
BA_REL_ "GenSigTimeoutTime" BU_SG_REL_ VMCU SG_ 560 DriverImpairedDriverAlert_ISig_4 240;
BA_REL_ "GenSigFirstTimeoutTime" BU_SG_REL_ IC3 SG_ 560 DriverVigilanceLevel 3000;
BA_REL_ "GenSigTimeoutTime" BU_SG_REL_ IC3 SG_ 560 DriverVigilanceLevel 240;
BA_REL_ "GenSigFirstTimeoutTime" BU_SG_REL_ VMCU SG_ 560 DriverVigilanceLevel 3000;
BA_REL_ "GenSigTimeoutTime" BU_SG_REL_ VMCU SG_ 560 DriverVigilanceLevel 240;
BA_REL_ "GenSigFirstTimeoutTime" BU_SG_REL_ TECU SG_ 560 ACCForwardVehicleSpeed_ISig_4 3000;
BA_REL_ "GenSigTimeoutTime" BU_SG_REL_ TECU SG_ 560 ACCForwardVehicleSpeed_ISig_4 120;
BA_REL_ "GenSigFirstTimeoutTime" BU_SG_REL_ IC3 SG_ 560 ACCForwardVehicleSpeed_ISig_4 3000;
BA_REL_ "GenSigTimeoutTime" BU_SG_REL_ IC3 SG_ 560 ACCForwardVehicleSpeed_ISig_4 240;
BA_REL_ "GenSigFirstTimeoutTime" BU_SG_REL_ IC3 SG_ 560 ACC_SGOFaultCondStat_Door 3000;
BA_REL_ "GenSigTimeoutTime" BU_SG_REL_ IC3 SG_ 560 ACC_SGOFaultCondStat_Door 240;
BA_REL_ "GenSigFirstTimeoutTime" BU_SG_REL_ IC3 SG_ 560 ACCTargetDetected 3000;
BA_REL_ "GenSigTimeoutTime" BU_SG_REL_ IC3 SG_ 560 ACCTargetDetected 240;
BA_REL_ "GenSigFirstTimeoutTime" BU_SG_REL_ IC3 SG_ 560 ACCForwardVehicleDistance_ISig_4 3000;
BA_REL_ "GenSigTimeoutTime" BU_SG_REL_ IC3 SG_ 560 ACCForwardVehicleDistance_ISig_4 240;
BA_REL_ "GenSigFirstTimeoutTime" BU_SG_REL_ TECU SG_ 560 ACCForwardVehicleDistance_ISig_4 3000;
BA_REL_ "GenSigTimeoutTime" BU_SG_REL_ TECU SG_ 560 ACCForwardVehicleDistance_ISig_4 120;
BA_REL_ "GenSigFirstTimeoutTime" BU_SG_REL_ IC3 SG_ 560 LKSCorrectiveSteeringStatus 3000;
BA_REL_ "GenSigTimeoutTime" BU_SG_REL_ IC3 SG_ 560 LKSCorrectiveSteeringStatus 240;
BA_REL_ "GenSigFirstTimeoutTime" BU_SG_REL_ VMCU SG_ 560 LKSCorrectiveSteeringStatus 3000;
BA_REL_ "GenSigTimeoutTime" BU_SG_REL_ VMCU SG_ 560 LKSCorrectiveSteeringStatus 120;
BA_REL_ "GenSigFirstTimeoutTime" BU_SG_REL_ CIOM SG_ 560 LKSCorrectiveSteeringStatus 3000;
BA_REL_ "GenSigTimeoutTime" BU_SG_REL_ CIOM SG_ 560 LKSCorrectiveSteeringStatus 120;
BA_REL_ "GenSigFirstTimeoutTime" BU_SG_REL_ IC3 SG_ 560 ACC_SGOFaultCondStat_Other 3000;
BA_REL_ "GenSigTimeoutTime" BU_SG_REL_ IC3 SG_ 560 ACC_SGOFaultCondStat_Other 240;
BA_REL_ "GenSigFirstTimeoutTime" BU_SG_REL_ IC3 SG_ 560 LCSSoundSettingStatus 3000;
BA_REL_ "GenSigTimeoutTime" BU_SG_REL_ IC3 SG_ 560 LCSSoundSettingStatus 240;
BA_REL_ "GenSigFirstTimeoutTime" BU_SG_REL_ IC3 SG_ 560 ACC_SGOFaultCondStat_Speed 3000;
BA_REL_ "GenSigTimeoutTime" BU_SG_REL_ IC3 SG_ 560 ACC_SGOFaultCondStat_Speed 240;
BA_REL_ "GenSigFirstTimeoutTime" BU_SG_REL_ HPCU SG_ 1460 ESSFnRqst_FnNum_ISig_4 24000;
BA_REL_ "GenSigTimeoutTime" BU_SG_REL_ HPCU SG_ 1460 ESSFnRqst_FnNum_ISig_4 6000;
BA_REL_ "GenSigFirstTimeoutTime" BU_SG_REL_ HPCU SG_ 1460 ESSFnRqst_FnPower_ISig_4 24000;
BA_REL_ "GenSigTimeoutTime" BU_SG_REL_ HPCU SG_ 1460 ESSFnRqst_FnPower_ISig_4 6000;
BA_REL_ "GenSigFirstTimeoutTime" BU_SG_REL_ HPCU SG_ 1460 ChlrVlvPsnRqst_ISig_4 24000;
BA_REL_ "GenSigTimeoutTime" BU_SG_REL_ HPCU SG_ 1460 ChlrVlvPsnRqst_ISig_4 6000;
BA_REL_ "GenSigFirstTimeoutTime" BU_SG_REL_ IC3 SG_ 551 BunkH1Next_ButtonStatus_ISig_4 3000;
BA_REL_ "GenSigTimeoutTime" BU_SG_REL_ IC3 SG_ 551 BunkH1Next_ButtonStatus_ISig_4 240;
BA_REL_ "GenSigFirstTimeoutTime" BU_SG_REL_ IC3 SG_ 551 BunkH1AudioOnOff_ButtonStatus_IS 3000;
BA_REL_ "GenSigTimeoutTime" BU_SG_REL_ IC3 SG_ 551 BunkH1AudioOnOff_ButtonStatus_IS 240;
BA_REL_ "GenSigFirstTimeoutTime" BU_SG_REL_ IC3 SG_ 551 BunkH1AudioSource_rqst_ISig_4 3000;
BA_REL_ "GenSigTimeoutTime" BU_SG_REL_ IC3 SG_ 551 BunkH1AudioSource_rqst_ISig_4 240;
BA_REL_ "GenSigFirstTimeoutTime" BU_SG_REL_ IC3 SG_ 551 BunkH1VolumeUp_ButtonStatus_ISig 3000;
BA_REL_ "GenSigTimeoutTime" BU_SG_REL_ IC3 SG_ 551 BunkH1VolumeUp_ButtonStatus_ISig 240;
BA_REL_ "GenSigFirstTimeoutTime" BU_SG_REL_ IC3 SG_ 551 BunkH1VolumeDown_ButtonStatus_IS 3000;
BA_REL_ "GenSigTimeoutTime" BU_SG_REL_ IC3 SG_ 551 BunkH1VolumeDown_ButtonStatus_IS 240;
BA_REL_ "GenSigFirstTimeoutTime" BU_SG_REL_ IC3 SG_ 551 BunkH1AudioSource_rqst2_ISig_4 3000;
BA_REL_ "GenSigTimeoutTime" BU_SG_REL_ IC3 SG_ 551 BunkH1AudioSource_rqst2_ISig_4 240;
BA_REL_ "GenSigFirstTimeoutTime" BU_SG_REL_ IC3 SG_ 551 BunkH1Mute_ButtonStatus_ISig_4 3000;
BA_REL_ "GenSigTimeoutTime" BU_SG_REL_ IC3 SG_ 551 BunkH1Mute_ButtonStatus_ISig_4 240;
BA_REL_ "GenSigFirstTimeoutTime" BU_SG_REL_ IC3 SG_ 551 BunkH1Prev_ButtonStatus_ISig_4 3000;
BA_REL_ "GenSigTimeoutTime" BU_SG_REL_ IC3 SG_ 551 BunkH1Prev_ButtonStatus_ISig_4 240;
BA_REL_ "GenSigFirstTimeoutTime" BU_SG_REL_ IC3 SG_ 551 AutoBlowerLevel_Status_ISig_4 3000;
BA_REL_ "GenSigTimeoutTime" BU_SG_REL_ IC3 SG_ 551 AutoBlowerLevel_Status_ISig_4 240;
BA_REL_ "GenSigFirstTimeoutTime" BU_SG_REL_ IC3 SG_ 551 AutoDefogmode_Status_ISig_4 3000;
BA_REL_ "GenSigTimeoutTime" BU_SG_REL_ IC3 SG_ 551 AutoDefogmode_Status_ISig_4 240;
BA_REL_ "GenSigFirstTimeoutTime" BU_SG_REL_ IC3 SG_ 551 AQSmode_Status_ISig_4 3000;
BA_REL_ "GenSigTimeoutTime" BU_SG_REL_ IC3 SG_ 551 AQSmode_Status_ISig_4 240;
BA_REL_ "GenSigFirstTimeoutTime" BU_SG_REL_ IC3 SG_ 551 ACmode_Status_ISig_4 3000;
BA_REL_ "GenSigTimeoutTime" BU_SG_REL_ IC3 SG_ 551 ACmode_Status_ISig_4 240;
BA_REL_ "GenSigFirstTimeoutTime" BU_SG_REL_ DACU SG_ 550 LKSCSEnableSwitch_rqst 3000;
BA_REL_ "GenSigTimeoutTime" BU_SG_REL_ DACU SG_ 550 LKSCSEnableSwitch_rqst 240;
BA_REL_ "GenSigFirstTimeoutTime" BU_SG_REL_ IC3 SG_ 1371 SRSWarningLamp_ISig_4 3000;
BA_REL_ "GenSigTimeoutTime" BU_SG_REL_ IC3 SG_ 1371 SRSWarningLamp_ISig_4 600;
BA_REL_ "GenSigFirstTimeoutTime" BU_SG_REL_ HPCU SG_ 1371 EvChargingConnectorUnlock_rqst 3000;
BA_REL_ "GenSigTimeoutTime" BU_SG_REL_ HPCU SG_ 1371 EvChargingConnectorUnlock_rqst 600;
BA_REL_ "GenSigFirstTimeoutTime" BU_SG_REL_ VMCU SG_ 1371 TrafficAccidentHazardLightRqst_I 3000;
BA_REL_ "GenSigTimeoutTime" BU_SG_REL_ VMCU SG_ 1371 TrafficAccidentHazardLightRqst_I 600;
BA_REL_ "GenSigFirstTimeoutTime" BU_SG_REL_ VMCU SG_ 1371 TrafficAccidentHzdActvRqst_SqC_I 3000;
BA_REL_ "GenSigTimeoutTime" BU_SG_REL_ VMCU SG_ 1371 TrafficAccidentHzdActvRqst_SqC_I 600;
BA_REL_ "GenSigFirstTimeoutTime" BU_SG_REL_ IC3 SG_ 1371 PHCleanStatFeedback_ISig_4 3000;
BA_REL_ "GenSigTimeoutTime" BU_SG_REL_ IC3 SG_ 1371 PHCleanStatFeedback_ISig_4 600;
BA_REL_ "GenSigFirstTimeoutTime" BU_SG_REL_ IC3 SG_ 1371 SRSWarningLamp_CRC_ISig_4 3000;
BA_REL_ "GenSigTimeoutTime" BU_SG_REL_ IC3 SG_ 1371 SRSWarningLamp_CRC_ISig_4 600;
BA_REL_ "GenSigFirstTimeoutTime" BU_SG_REL_ TECU SG_ 1371 GearboxUnlockAuth_stat 3000;
BA_REL_ "GenSigTimeoutTime" BU_SG_REL_ TECU SG_ 1371 GearboxUnlockAuth_stat 600;
BA_REL_ "GenSigFirstTimeoutTime" BU_SG_REL_ IC3 SG_ 1371 TemperatureRqstIndication_cmd_IS 3000;
BA_REL_ "GenSigTimeoutTime" BU_SG_REL_ IC3 SG_ 1371 TemperatureRqstIndication_cmd_IS 600;
BA_REL_ "GenSigFirstTimeoutTime" BU_SG_REL_ VMCU SG_ 1371 TrafficAccidentHzdActvRqst_CRC_I 3000;
BA_REL_ "GenSigTimeoutTime" BU_SG_REL_ VMCU SG_ 1371 TrafficAccidentHzdActvRqst_CRC_I 600;
BA_REL_ "GenSigFirstTimeoutTime" BU_SG_REL_ IC3 SG_ 1371 SRSWarningLamp_SqC_ISig_4 3000;
BA_REL_ "GenSigTimeoutTime" BU_SG_REL_ IC3 SG_ 1371 SRSWarningLamp_SqC_ISig_4 600;
BA_REL_ "GenSigFirstTimeoutTime" BU_SG_REL_ IC3 SG_ 1371 PassengersSeatBelt_ISig_4 3000;
BA_REL_ "GenSigTimeoutTime" BU_SG_REL_ IC3 SG_ 1371 PassengersSeatBelt_ISig_4 600;
BA_REL_ "GenSigFirstTimeoutTime" BU_SG_REL_ BBM SG_ 1371 PassengersSeatBelt_ISig_4 3000;
BA_REL_ "GenSigTimeoutTime" BU_SG_REL_ BBM SG_ 1371 PassengersSeatBelt_ISig_4 600;
BA_REL_ "GenSigFirstTimeoutTime" BU_SG_REL_ DACU SG_ 1371 PassengersSeatBelt_ISig_4 3000;
BA_REL_ "GenSigTimeoutTime" BU_SG_REL_ DACU SG_ 1371 PassengersSeatBelt_ISig_4 600;
BA_REL_ "GenSigFirstTimeoutTime" BU_SG_REL_ IC3 SG_ 964 AlmClkSetAlm_LECM_rq_Type_ISig_4 10000;
BA_REL_ "GenSigTimeoutTime" BU_SG_REL_ IC3 SG_ 964 AlmClkSetAlm_LECM_rq_Type_ISig_4 3000;
BA_REL_ "GenSigFirstTimeoutTime" BU_SG_REL_ IC3 SG_ 964 AlmClkSetAlm_LECM_rq_ID_ISig_4 10000;
BA_REL_ "GenSigTimeoutTime" BU_SG_REL_ IC3 SG_ 964 AlmClkSetAlm_LECM_rq_ID_ISig_4 3000;
BA_REL_ "GenSigFirstTimeoutTime" BU_SG_REL_ IC3 SG_ 964 AlmClkSetAlm_LECM_rq_SetHr_ISig_ 10000;
BA_REL_ "GenSigTimeoutTime" BU_SG_REL_ IC3 SG_ 964 AlmClkSetAlm_LECM_rq_SetHr_ISig_ 3000;
BA_REL_ "GenSigFirstTimeoutTime" BU_SG_REL_ IC3 SG_ 964 AlmClkSetAlm_LECM_rq_Stat_ISig_4 10000;
BA_REL_ "GenSigTimeoutTime" BU_SG_REL_ IC3 SG_ 964 AlmClkSetAlm_LECM_rq_Stat_ISig_4 3000;
BA_REL_ "GenSigFirstTimeoutTime" BU_SG_REL_ IC3 SG_ 964 AlmClkSetAlm_LECM_rq_SetMin_ISig 10000;
BA_REL_ "GenSigTimeoutTime" BU_SG_REL_ IC3 SG_ 964 AlmClkSetAlm_LECM_rq_SetMin_ISig 3000;
BA_REL_ "GenSigFirstTimeoutTime" BU_SG_REL_ IC3 SG_ 964 AlmClkSetAlm_LECM_rq_DaySet_ISig 10000;
BA_REL_ "GenSigTimeoutTime" BU_SG_REL_ IC3 SG_ 964 AlmClkSetAlm_LECM_rq_DaySet_ISig 3000;
BA_REL_ "GenSigFirstTimeoutTime" BU_SG_REL_ IC3 SG_ 964 AlmClkSetAlm_LECM_rq_Mode_ISig_4 10000;
BA_REL_ "GenSigTimeoutTime" BU_SG_REL_ IC3 SG_ 964 AlmClkSetAlm_LECM_rq_Mode_ISig_4 3000;
BA_REL_ "GenSigFirstTimeoutTime" BU_SG_REL_ VMCU SG_ 845 TrafficAccShutDownReq_CRC_ISig_4 3000;
BA_REL_ "GenSigTimeoutTime" BU_SG_REL_ VMCU SG_ 845 TrafficAccShutDownReq_CRC_ISig_4 300;
BA_REL_ "GenSigFirstTimeoutTime" BU_SG_REL_ IC3 SG_ 845 ExtraHeating_status_ISig_4 3000;
BA_REL_ "GenSigTimeoutTime" BU_SG_REL_ IC3 SG_ 845 ExtraHeating_status_ISig_4 300;
BA_REL_ "GenSigFirstTimeoutTime" BU_SG_REL_ DACU SG_ 845 FrontalCollisionAccidentStatus_I 3000;
BA_REL_ "GenSigTimeoutTime" BU_SG_REL_ DACU SG_ 845 FrontalCollisionAccidentStatus_I 300;
BA_REL_ "GenSigFirstTimeoutTime" BU_SG_REL_ BBM SG_ 845 TipperUpDownRequest_ISig_4 3000;
BA_REL_ "GenSigTimeoutTime" BU_SG_REL_ BBM SG_ 845 TipperUpDownRequest_ISig_4 500;
BA_REL_ "GenSigFirstTimeoutTime" BU_SG_REL_ VMCU SG_ 845 LoadDistributionRequested_ISig_4 3000;
BA_REL_ "GenSigTimeoutTime" BU_SG_REL_ VMCU SG_ 845 LoadDistributionRequested_ISig_4 500;
BA_REL_ "GenSigFirstTimeoutTime" BU_SG_REL_ BBM SG_ 845 TipperTailGateRequest_ISig_4 3000;
BA_REL_ "GenSigTimeoutTime" BU_SG_REL_ BBM SG_ 845 TipperTailGateRequest_ISig_4 500;
BA_REL_ "GenSigFirstTimeoutTime" BU_SG_REL_ BBM SG_ 845 TipperTippingBodySelection_ISig_ 3000;
BA_REL_ "GenSigTimeoutTime" BU_SG_REL_ BBM SG_ 845 TipperTippingBodySelection_ISig_ 500;
BA_REL_ "GenSigFirstTimeoutTime" BU_SG_REL_ BBM SG_ 845 TipperEmergencyStop_ISig_4 3000;
BA_REL_ "GenSigTimeoutTime" BU_SG_REL_ BBM SG_ 845 TipperEmergencyStop_ISig_4 500;
BA_REL_ "GenSigFirstTimeoutTime" BU_SG_REL_ BBM SG_ 845 ExtraBbWrcWatchdog_ISig_4 3000;
BA_REL_ "GenSigTimeoutTime" BU_SG_REL_ BBM SG_ 845 ExtraBbWrcWatchdog_ISig_4 500;
BA_REL_ "GenSigFirstTimeoutTime" BU_SG_REL_ VMCU SG_ 845 AutoFrontWheelDriveDrvReq 3000;
BA_REL_ "GenSigTimeoutTime" BU_SG_REL_ VMCU SG_ 845 AutoFrontWheelDriveDrvReq 300;
BA_REL_ "GenSigFirstTimeoutTime" BU_SG_REL_ VMCU SG_ 845 ShortStopHeater_cmd_ISig_4 3000;
BA_REL_ "GenSigTimeoutTime" BU_SG_REL_ VMCU SG_ 845 ShortStopHeater_cmd_ISig_4 300;
BA_REL_ "GenSigFirstTimeoutTime" BU_SG_REL_ BBM SG_ 845 TailLiftMotionRequest_ISig_4 3000;
BA_REL_ "GenSigTimeoutTime" BU_SG_REL_ BBM SG_ 845 TailLiftMotionRequest_ISig_4 500;
BA_REL_ "GenSigFirstTimeoutTime" BU_SG_REL_ BBM SG_ 845 TipperShakerRequest_ISig_4 3000;
BA_REL_ "GenSigTimeoutTime" BU_SG_REL_ BBM SG_ 845 TipperShakerRequest_ISig_4 500;
BA_REL_ "GenSigFirstTimeoutTime" BU_SG_REL_ VMCU SG_ 845 TrafficAccShutDownReq_Rqst_ISig_ 3000;
BA_REL_ "GenSigTimeoutTime" BU_SG_REL_ VMCU SG_ 845 TrafficAccShutDownReq_Rqst_ISig_ 300;
BA_REL_ "GenSigFirstTimeoutTime" BU_SG_REL_ BBM SG_ 845 TipperTarpaulinRequest_ISig_4 3000;
BA_REL_ "GenSigTimeoutTime" BU_SG_REL_ BBM SG_ 845 TipperTarpaulinRequest_ISig_4 500;
BA_REL_ "GenSigFirstTimeoutTime" BU_SG_REL_ VMCU SG_ 845 TrafficAccShutDownReq_SqC_ISig_4 3000;
BA_REL_ "GenSigTimeoutTime" BU_SG_REL_ VMCU SG_ 845 TrafficAccShutDownReq_SqC_ISig_4 300;
BA_REL_ "GenSigFirstTimeoutTime" BU_SG_REL_ IC3 SG_ 845 ABSInhibitRqstDenied 3000;
BA_REL_ "GenSigTimeoutTime" BU_SG_REL_ IC3 SG_ 845 ABSInhibitRqstDenied 300;
BA_REL_ "GenSigFirstTimeoutTime" BU_SG_REL_ EMS SG_ 928 ACCoolingFanSpeedRequest 3000;
BA_REL_ "GenSigTimeoutTime" BU_SG_REL_ EMS SG_ 928 ACCoolingFanSpeedRequest 570;
BA_REL_ "GenSigFirstTimeoutTime" BU_SG_REL_ VMCU SG_ 928 CabTilt_rqst 3000;
BA_REL_ "GenSigTimeoutTime" BU_SG_REL_ VMCU SG_ 928 CabTilt_rqst 570;
BA_REL_ "GenSigFirstTimeoutTime" BU_SG_REL_ BBM SG_ 928 Pto3CabRequest 3000;
BA_REL_ "GenSigTimeoutTime" BU_SG_REL_ BBM SG_ 928 Pto3CabRequest 570;
BA_REL_ "GenSigFirstTimeoutTime" BU_SG_REL_ VMCU SG_ 928 Pto3CabRequest 3000;
BA_REL_ "GenSigTimeoutTime" BU_SG_REL_ VMCU SG_ 928 Pto3CabRequest 570;
BA_REL_ "GenSigFirstTimeoutTime" BU_SG_REL_ VMCU SG_ 928 Pto4CabRequest 3000;
BA_REL_ "GenSigTimeoutTime" BU_SG_REL_ VMCU SG_ 928 Pto4CabRequest 570;
BA_REL_ "GenSigFirstTimeoutTime" BU_SG_REL_ BBM SG_ 928 Pto4CabRequest 3000;
BA_REL_ "GenSigTimeoutTime" BU_SG_REL_ BBM SG_ 928 Pto4CabRequest 600;
BA_REL_ "GenSigFirstTimeoutTime" BU_SG_REL_ BBM SG_ 928 WindscreenDefrostInd_cmd_ISig_4 3000;
BA_REL_ "GenSigTimeoutTime" BU_SG_REL_ BBM SG_ 928 WindscreenDefrostInd_cmd_ISig_4 600;
BA_REL_ "GenSigFirstTimeoutTime" BU_SG_REL_ DACU SG_ 928 SRSAirbagStatus_ISig_4 3000;
BA_REL_ "GenSigTimeoutTime" BU_SG_REL_ DACU SG_ 928 SRSAirbagStatus_ISig_4 600;
BA_REL_ "GenSigFirstTimeoutTime" BU_SG_REL_ IC3 SG_ 928 SRSAirbagStatus_ISig_4 3000;
BA_REL_ "GenSigTimeoutTime" BU_SG_REL_ IC3 SG_ 928 SRSAirbagStatus_ISig_4 570;
BA_REL_ "GenSigFirstTimeoutTime" BU_SG_REL_ VMCU SG_ 928 SRSAirbagStatus_ISig_4 3000;
BA_REL_ "GenSigTimeoutTime" BU_SG_REL_ VMCU SG_ 928 SRSAirbagStatus_ISig_4 570;
BA_REL_ "GenSigFirstTimeoutTime" BU_SG_REL_ VMCU SG_ 928 FrontLidAjar_Stat 3000;
BA_REL_ "GenSigTimeoutTime" BU_SG_REL_ VMCU SG_ 928 FrontLidAjar_Stat 570;
BA_REL_ "GenSigFirstTimeoutTime" BU_SG_REL_ IC3 SG_ 928 ParkingHeaterCleaning_Rqst_ISig_ 3000;
BA_REL_ "GenSigTimeoutTime" BU_SG_REL_ IC3 SG_ 928 ParkingHeaterCleaning_Rqst_ISig_ 570;
BA_REL_ "GenSigFirstTimeoutTime" BU_SG_REL_ BBM SG_ 928 Pto2CabRequest 3000;
BA_REL_ "GenSigTimeoutTime" BU_SG_REL_ BBM SG_ 928 Pto2CabRequest 570;
BA_REL_ "GenSigFirstTimeoutTime" BU_SG_REL_ VMCU SG_ 928 Pto2CabRequest 3000;
BA_REL_ "GenSigTimeoutTime" BU_SG_REL_ VMCU SG_ 928 Pto2CabRequest 570;
BA_REL_ "GenSigFirstTimeoutTime" BU_SG_REL_ IC3 SG_ 928 TemporaryRSLSwitchStatus 3000;
BA_REL_ "GenSigTimeoutTime" BU_SG_REL_ IC3 SG_ 928 TemporaryRSLSwitchStatus 570;
BA_REL_ "GenSigFirstTimeoutTime" BU_SG_REL_ IC3 SG_ 928 SeatSwivelWarning_rqst 3000;
BA_REL_ "GenSigTimeoutTime" BU_SG_REL_ IC3 SG_ 928 SeatSwivelWarning_rqst 570;
BA_REL_ "GenSigFirstTimeoutTime" BU_SG_REL_ VMCU SG_ 928 Pto1CabRequest 3000;
BA_REL_ "GenSigTimeoutTime" BU_SG_REL_ VMCU SG_ 928 Pto1CabRequest 570;
BA_REL_ "GenSigFirstTimeoutTime" BU_SG_REL_ BBM SG_ 928 Pto1CabRequest 3000;
BA_REL_ "GenSigTimeoutTime" BU_SG_REL_ BBM SG_ 928 Pto1CabRequest 570;
BA_REL_ "GenSigFirstTimeoutTime" BU_SG_REL_ IC3 SG_ 928 ThreePosDifflockSwitch_stat 3000;
BA_REL_ "GenSigTimeoutTime" BU_SG_REL_ IC3 SG_ 928 ThreePosDifflockSwitch_stat 570;
BA_REL_ "GenSigFirstTimeoutTime" BU_SG_REL_ DACU SG_ 857 LCS_EnableSwitch_rqst 3000;
BA_REL_ "GenSigTimeoutTime" BU_SG_REL_ DACU SG_ 857 LCS_EnableSwitch_rqst 330;
BA_REL_ "GenSigFirstTimeoutTime" BU_SG_REL_ VMCU SG_ 857 EscCrossCountryActivation_rqst 3000;
BA_REL_ "GenSigTimeoutTime" BU_SG_REL_ VMCU SG_ 857 EscCrossCountryActivation_rqst 330;
BA_REL_ "GenSigFirstTimeoutTime" BU_SG_REL_ VMCU SG_ 857 StaticCornerLightMode 3000;
BA_REL_ "GenSigTimeoutTime" BU_SG_REL_ VMCU SG_ 857 StaticCornerLightMode 330;
BA_REL_ "GenSigFirstTimeoutTime" BU_SG_REL_ EMS SG_ 857 SplitBoxDifflockActvnDrvrRqst_IS 3000;
BA_REL_ "GenSigTimeoutTime" BU_SG_REL_ EMS SG_ 857 SplitBoxDifflockActvnDrvrRqst_IS 500;
BA_REL_ "GenSigFirstTimeoutTime" BU_SG_REL_ VMCU SG_ 857 SplitBoxDifflockActvnDrvrRqst_IS 3000;
BA_REL_ "GenSigTimeoutTime" BU_SG_REL_ VMCU SG_ 857 SplitBoxDifflockActvnDrvrRqst_IS 500;
BA_REL_ "GenSigFirstTimeoutTime" BU_SG_REL_ IC3 SG_ 857 SplitBoxDifflockActvnDrvrRqst_IS 3000;
BA_REL_ "GenSigTimeoutTime" BU_SG_REL_ IC3 SG_ 857 SplitBoxDifflockActvnDrvrRqst_IS 330;
BA_REL_ "GenSigFirstTimeoutTime" BU_SG_REL_ TECU SG_ 857 SplitBoxDifflockActvnDrvrRqst_IS 3000;
BA_REL_ "GenSigTimeoutTime" BU_SG_REL_ TECU SG_ 857 SplitBoxDifflockActvnDrvrRqst_IS 500;
BA_REL_ "GenSigFirstTimeoutTime" BU_SG_REL_ VMCU SG_ 857 ATCFrontWheelDriveRequest 3000;
BA_REL_ "GenSigTimeoutTime" BU_SG_REL_ VMCU SG_ 857 ATCFrontWheelDriveRequest 330;
BA_REL_ "GenSigFirstTimeoutTime" BU_SG_REL_ TECU SG_ 857 ConstructionSwitch_stat 3000;
BA_REL_ "GenSigTimeoutTime" BU_SG_REL_ TECU SG_ 857 ConstructionSwitch_stat 330;
BA_REL_ "GenSigFirstTimeoutTime" BU_SG_REL_ VMCU SG_ 857 EscCabActionRequest 3000;
BA_REL_ "GenSigTimeoutTime" BU_SG_REL_ VMCU SG_ 857 EscCabActionRequest 330;
BA_REL_ "GenSigFirstTimeoutTime" BU_SG_REL_ VMCU SG_ 857 AdjustRequestForIdle 3000;
BA_REL_ "GenSigTimeoutTime" BU_SG_REL_ VMCU SG_ 857 AdjustRequestForIdle 330;
BA_REL_ "GenSigFirstTimeoutTime" BU_SG_REL_ VMCU SG_ 857 SCL_LogicPowerOutput_stat 3000;
BA_REL_ "GenSigTimeoutTime" BU_SG_REL_ VMCU SG_ 857 SCL_LogicPowerOutput_stat 330;
BA_REL_ "GenSigFirstTimeoutTime" BU_SG_REL_ IC3 SG_ 857 PinCode_validity_time 3000;
BA_REL_ "GenSigTimeoutTime" BU_SG_REL_ IC3 SG_ 857 PinCode_validity_time 330;
BA_REL_ "GenSigFirstTimeoutTime" BU_SG_REL_ VMCU SG_ 857 StatTrailerBrakeSwitchStatus 3000;
BA_REL_ "GenSigTimeoutTime" BU_SG_REL_ VMCU SG_ 857 StatTrailerBrakeSwitchStatus 330;
BA_REL_ "GenSigFirstTimeoutTime" BU_SG_REL_ VMCU SG_ 857 RoofHatch_HMI_rqst 3000;
BA_REL_ "GenSigTimeoutTime" BU_SG_REL_ VMCU SG_ 857 RoofHatch_HMI_rqst 330;
BA_REL_ "GenSigFirstTimeoutTime" BU_SG_REL_ VMCU SG_ 857 EscCabEnable 3000;
BA_REL_ "GenSigTimeoutTime" BU_SG_REL_ VMCU SG_ 857 EscCabEnable 330;
BA_REL_ "GenSigFirstTimeoutTime" BU_SG_REL_ VMCU SG_ 857 ExtraSideMarkers_Rqst 3000;
BA_REL_ "GenSigTimeoutTime" BU_SG_REL_ VMCU SG_ 857 ExtraSideMarkers_Rqst 330;
BA_REL_ "GenSigFirstTimeoutTime" BU_SG_REL_ VMCU SG_ 857 LevelingThumbwheel_stat 3000;
BA_REL_ "GenSigTimeoutTime" BU_SG_REL_ VMCU SG_ 857 LevelingThumbwheel_stat 330;
BA_REL_ "GenSigFirstTimeoutTime" BU_SG_REL_ DACU SG_ 857 DASActivation_rqst 3000;
BA_REL_ "GenSigTimeoutTime" BU_SG_REL_ DACU SG_ 857 DASActivation_rqst 330;
BA_REL_ "GenSigFirstTimeoutTime" BU_SG_REL_ VMCU SG_ 857 DriverSeatBeltSwitch_ISig_4 3000;
BA_REL_ "GenSigTimeoutTime" BU_SG_REL_ VMCU SG_ 857 DriverSeatBeltSwitch_ISig_4 330;
BA_REL_ "GenSigFirstTimeoutTime" BU_SG_REL_ DACU SG_ 857 DriverSeatBeltSwitch_ISig_4 3000;
BA_REL_ "GenSigTimeoutTime" BU_SG_REL_ DACU SG_ 857 DriverSeatBeltSwitch_ISig_4 330;
BA_REL_ "GenSigFirstTimeoutTime" BU_SG_REL_ BBM SG_ 857 DriverSeatBeltSwitch_ISig_4 3000;
BA_REL_ "GenSigTimeoutTime" BU_SG_REL_ BBM SG_ 857 DriverSeatBeltSwitch_ISig_4 330;
BA_REL_ "GenSigFirstTimeoutTime" BU_SG_REL_ IC3 SG_ 857 DriverSeatBeltSwitch_ISig_4 3000;
BA_REL_ "GenSigTimeoutTime" BU_SG_REL_ IC3 SG_ 857 DriverSeatBeltSwitch_ISig_4 330;
BA_REL_ "GenSigFirstTimeoutTime" BU_SG_REL_ IC3 SG_ 857 PinCode_stat 3000;
BA_REL_ "GenSigTimeoutTime" BU_SG_REL_ IC3 SG_ 857 PinCode_stat 330;
BA_REL_ "GenSigFirstTimeoutTime" BU_SG_REL_ EMS SG_ 857 WarmUp_Request 3000;
BA_REL_ "GenSigTimeoutTime" BU_SG_REL_ EMS SG_ 857 WarmUp_Request 330;
BA_REL_ "GenSigFirstTimeoutTime" BU_SG_REL_ DACU SG_ 857 LKSEnableSwitch_rqst 3000;
BA_REL_ "GenSigTimeoutTime" BU_SG_REL_ DACU SG_ 857 LKSEnableSwitch_rqst 330;
BA_REL_ "GenSigFirstTimeoutTime" BU_SG_REL_ IC3 SG_ 1044 AlmClkSnze_LECM_rqst_ID_ISig_4 3000;
BA_REL_ "GenSigTimeoutTime" BU_SG_REL_ IC3 SG_ 1044 AlmClkSnze_LECM_rqst_ID_ISig_4 600;
BA_REL_ "GenSigFirstTimeoutTime" BU_SG_REL_ VMCU SG_ 1044 AlmClkSetCurAlm_rqst_ID 3000;
BA_REL_ "GenSigTimeoutTime" BU_SG_REL_ VMCU SG_ 1044 AlmClkSetCurAlm_rqst_ID 600;
BA_REL_ "GenSigFirstTimeoutTime" BU_SG_REL_ IC3 SG_ 1044 AlmClkSnze_LECM_rqst_Action_ISig 3000;
BA_REL_ "GenSigTimeoutTime" BU_SG_REL_ IC3 SG_ 1044 AlmClkSnze_LECM_rqst_Action_ISig 600;
BA_REL_ "GenSigFirstTimeoutTime" BU_SG_REL_ VMCU SG_ 1044 AlmClkSetCurAlm_rqst_Stat 3000;
BA_REL_ "GenSigTimeoutTime" BU_SG_REL_ VMCU SG_ 1044 AlmClkSetCurAlm_rqst_Stat 600;
BA_REL_ "GenSigFirstTimeoutTime" BU_SG_REL_ VMCU SG_ 1044 AlmClkSetCurAlm_rqst_SetMin 3000;
BA_REL_ "GenSigTimeoutTime" BU_SG_REL_ VMCU SG_ 1044 AlmClkSetCurAlm_rqst_SetMin 600;
BA_REL_ "GenSigFirstTimeoutTime" BU_SG_REL_ VMCU SG_ 1044 AlmClkSetCurAlm_rqst_SetHr 3000;
BA_REL_ "GenSigTimeoutTime" BU_SG_REL_ VMCU SG_ 1044 AlmClkSetCurAlm_rqst_SetHr 600;
BA_REL_ "GenSigFirstTimeoutTime" BU_SG_REL_ IC3 SG_ 1044 CollSituationHMICtrlRequestVM 3000;
BA_REL_ "GenSigTimeoutTime" BU_SG_REL_ IC3 SG_ 1044 CollSituationHMICtrlRequestVM 600;
BA_REL_ "GenSigFirstTimeoutTime" BU_SG_REL_ EMS SG_ 1044 AcCoolantPumpEngagementRequest_I 3000;
BA_REL_ "GenSigTimeoutTime" BU_SG_REL_ EMS SG_ 1044 AcCoolantPumpEngagementRequest_I 600;
BA_REL_ "GenSigFirstTimeoutTime" BU_SG_REL_ VMCU SG_ 1044 AlmClkSetCurAlm_rqst_Type 3000;
BA_REL_ "GenSigTimeoutTime" BU_SG_REL_ VMCU SG_ 1044 AlmClkSetCurAlm_rqst_Type 600;
BA_REL_ "GenSigFirstTimeoutTime" BU_SG_REL_ IC3 SG_ 1044 WRC_Docking_stat_ISig_4 3000;
BA_REL_ "GenSigTimeoutTime" BU_SG_REL_ IC3 SG_ 1044 WRC_Docking_stat_ISig_4 600;
BA_REL_ "GenSigFirstTimeoutTime" BU_SG_REL_ IC3 SG_ 847 MirrorSelectRightMainBtn_stat_IS 3000;
BA_REL_ "GenSigTimeoutTime" BU_SG_REL_ IC3 SG_ 847 MirrorSelectRightMainBtn_stat_IS 300;
BA_REL_ "GenSigFirstTimeoutTime" BU_SG_REL_ BBM SG_ 847 WRCEngineStopRequest_ISig_4 3000;
BA_REL_ "GenSigTimeoutTime" BU_SG_REL_ BBM SG_ 847 WRCEngineStopRequest_ISig_4 500;
BA_REL_ "GenSigFirstTimeoutTime" BU_SG_REL_ VMCU SG_ 847 LiftAxle1DirectControl_ISig_4 3000;
BA_REL_ "GenSigTimeoutTime" BU_SG_REL_ VMCU SG_ 847 LiftAxle1DirectControl_ISig_4 500;
BA_REL_ "GenSigFirstTimeoutTime" BU_SG_REL_ IC3 SG_ 847 MirrorSelectRightWideBtn_stat_IS 3000;
BA_REL_ "GenSigTimeoutTime" BU_SG_REL_ IC3 SG_ 847 MirrorSelectRightWideBtn_stat_IS 300;
BA_REL_ "GenSigFirstTimeoutTime" BU_SG_REL_ VMCU SG_ 847 PanicAlarmFromKeyfob_rqst 3000;
BA_REL_ "GenSigTimeoutTime" BU_SG_REL_ VMCU SG_ 847 PanicAlarmFromKeyfob_rqst 300;
BA_REL_ "GenSigFirstTimeoutTime" BU_SG_REL_ IC3 SG_ 847 ParkingClimate_IndicationCmd_ISi 3000;
BA_REL_ "GenSigTimeoutTime" BU_SG_REL_ IC3 SG_ 847 ParkingClimate_IndicationCmd_ISi 300;
BA_REL_ "GenSigFirstTimeoutTime" BU_SG_REL_ IC3 SG_ 847 MirrorSelectLeftWideBtn_stat_ISi 3000;
BA_REL_ "GenSigTimeoutTime" BU_SG_REL_ IC3 SG_ 847 MirrorSelectLeftWideBtn_stat_ISi 300;
BA_REL_ "GenSigFirstTimeoutTime" BU_SG_REL_ BBM SG_ 847 WRCEngineStartRequest_ISig_4 3000;
BA_REL_ "GenSigTimeoutTime" BU_SG_REL_ BBM SG_ 847 WRCEngineStartRequest_ISig_4 500;
BA_REL_ "GenSigFirstTimeoutTime" BU_SG_REL_ IC3 SG_ 847 PW_Left_DS_SwStatus_ISig_4 3000;
BA_REL_ "GenSigTimeoutTime" BU_SG_REL_ IC3 SG_ 847 PW_Left_DS_SwStatus_ISig_4 300;
BA_REL_ "GenSigFirstTimeoutTime" BU_SG_REL_ IC3 SG_ 847 RegenerationSwitchStatus 3000;
BA_REL_ "GenSigTimeoutTime" BU_SG_REL_ IC3 SG_ 847 RegenerationSwitchStatus 300;
BA_REL_ "GenSigFirstTimeoutTime" BU_SG_REL_ IC3 SG_ 847 PW_Right_DS_SwStatus_ISig_4 3000;
BA_REL_ "GenSigTimeoutTime" BU_SG_REL_ IC3 SG_ 847 PW_Right_DS_SwStatus_ISig_4 300;
BA_REL_ "GenSigFirstTimeoutTime" BU_SG_REL_ BBM SG_ 847 DoorLock_stat_ISig_4 3000;
BA_REL_ "GenSigTimeoutTime" BU_SG_REL_ BBM SG_ 847 DoorLock_stat_ISig_4 300;
BA_REL_ "GenSigFirstTimeoutTime" BU_SG_REL_ IC3 SG_ 847 DoorLock_stat_ISig_4 3000;
BA_REL_ "GenSigTimeoutTime" BU_SG_REL_ IC3 SG_ 847 DoorLock_stat_ISig_4 300;
BA_REL_ "GenSigFirstTimeoutTime" BU_SG_REL_ IC3 SG_ 847 LuggageAjar_stat 3000;
BA_REL_ "GenSigTimeoutTime" BU_SG_REL_ IC3 SG_ 847 LuggageAjar_stat 300;
BA_REL_ "GenSigFirstTimeoutTime" BU_SG_REL_ IC3 SG_ 847 AlarmStatus_stat_ISig_4 3000;
BA_REL_ "GenSigTimeoutTime" BU_SG_REL_ IC3 SG_ 847 AlarmStatus_stat_ISig_4 300;
BA_REL_ "GenSigFirstTimeoutTime" BU_SG_REL_ BBM SG_ 847 AlarmTriggeringCause_stat_ISig_4 3000;
BA_REL_ "GenSigTimeoutTime" BU_SG_REL_ BBM SG_ 847 AlarmTriggeringCause_stat_ISig_4 300;
BA_REL_ "GenSigFirstTimeoutTime" BU_SG_REL_ IC3 SG_ 847 AlarmTriggeringCause_stat_ISig_4 3000;
BA_REL_ "GenSigTimeoutTime" BU_SG_REL_ IC3 SG_ 847 AlarmTriggeringCause_stat_ISig_4 300;
BA_REL_ "GenSigFirstTimeoutTime" BU_SG_REL_ IC3 SG_ 847 DoorsAjar_stat_ISig_4 3000;
BA_REL_ "GenSigTimeoutTime" BU_SG_REL_ IC3 SG_ 847 DoorsAjar_stat_ISig_4 500;
BA_REL_ "GenSigFirstTimeoutTime" BU_SG_REL_ VMCU SG_ 847 DoorsAjar_stat_ISig_4 3000;
BA_REL_ "GenSigTimeoutTime" BU_SG_REL_ VMCU SG_ 847 DoorsAjar_stat_ISig_4 500;
BA_REL_ "GenSigFirstTimeoutTime" BU_SG_REL_ DACU SG_ 847 DoorsAjar_stat_ISig_4 3000;
BA_REL_ "GenSigTimeoutTime" BU_SG_REL_ DACU SG_ 847 DoorsAjar_stat_ISig_4 500;
BA_REL_ "GenSigFirstTimeoutTime" BU_SG_REL_ BBM SG_ 847 DoorsAjar_stat_ISig_4 3000;
BA_REL_ "GenSigTimeoutTime" BU_SG_REL_ BBM SG_ 847 DoorsAjar_stat_ISig_4 500;
BA_REL_ "GenSigFirstTimeoutTime" BU_SG_REL_ VMCU SG_ 847 DoorAutoFunction_rqst 3000;
BA_REL_ "GenSigTimeoutTime" BU_SG_REL_ VMCU SG_ 847 DoorAutoFunction_rqst 300;
BA_REL_ "GenSigFirstTimeoutTime" BU_SG_REL_ IC3 SG_ 847 MirrorSelectLeftMainBtn_stat_ISi 3000;
BA_REL_ "GenSigTimeoutTime" BU_SG_REL_ IC3 SG_ 847 MirrorSelectLeftMainBtn_stat_ISi 300;
BA_REL_ "GenSigFirstTimeoutTime" BU_SG_REL_ VMCU SG_ 841 FPBRChangeReq_ISig_4 3000;
BA_REL_ "GenSigTimeoutTime" BU_SG_REL_ VMCU SG_ 841 FPBRChangeReq_ISig_4 300;
BA_REL_ "GenSigFirstTimeoutTime" BU_SG_REL_ VMCU SG_ 841 HeadLampUpDown_SwitchStatus 3000;
BA_REL_ "GenSigTimeoutTime" BU_SG_REL_ VMCU SG_ 841 HeadLampUpDown_SwitchStatus 300;
BA_REL_ "GenSigFirstTimeoutTime" BU_SG_REL_ IC3 SG_ 841 Recirc_ButtonStatus_ISig_4 3000;
BA_REL_ "GenSigTimeoutTime" BU_SG_REL_ IC3 SG_ 841 Recirc_ButtonStatus_ISig_4 300;
BA_REL_ "GenSigFirstTimeoutTime" BU_SG_REL_ IC3 SG_ 841 Auto_ButtonStatus_ISig_4 3000;
BA_REL_ "GenSigTimeoutTime" BU_SG_REL_ IC3 SG_ 841 Auto_ButtonStatus_ISig_4 300;
BA_REL_ "GenSigFirstTimeoutTime" BU_SG_REL_ IC3 SG_ 841 AirFlowSelectionFrontBtn_stat_IS 3000;
BA_REL_ "GenSigTimeoutTime" BU_SG_REL_ IC3 SG_ 841 AirFlowSelectionFrontBtn_stat_IS 300;
BA_REL_ "GenSigFirstTimeoutTime" BU_SG_REL_ VMCU SG_ 841 InteriorLightMode_rqst_IL_Mode 3000;
BA_REL_ "GenSigTimeoutTime" BU_SG_REL_ VMCU SG_ 841 InteriorLightMode_rqst_IL_Mode 300;
BA_REL_ "GenSigFirstTimeoutTime" BU_SG_REL_ VMCU SG_ 841 InteriorLightMode_rqst_EventFlag 3000;
BA_REL_ "GenSigTimeoutTime" BU_SG_REL_ VMCU SG_ 841 InteriorLightMode_rqst_EventFlag 300;
BA_REL_ "GenSigFirstTimeoutTime" BU_SG_REL_ VMCU SG_ 841 BlackOutConvoyModeSwitchStatus 3000;
BA_REL_ "GenSigTimeoutTime" BU_SG_REL_ VMCU SG_ 841 BlackOutConvoyModeSwitchStatus 300;
BA_REL_ "GenSigFirstTimeoutTime" BU_SG_REL_ VMCU SG_ 841 Indicator_Lights_Alarm_rqst_ISig 3000;
BA_REL_ "GenSigTimeoutTime" BU_SG_REL_ VMCU SG_ 841 Indicator_Lights_Alarm_rqst_ISig 300;
BA_REL_ "GenSigFirstTimeoutTime" BU_SG_REL_ IC3 SG_ 841 AirFlowSelectionDownBtn_stat_ISi 3000;
BA_REL_ "GenSigTimeoutTime" BU_SG_REL_ IC3 SG_ 841 AirFlowSelectionDownBtn_stat_ISi 300;
BA_REL_ "GenSigFirstTimeoutTime" BU_SG_REL_ BBM SG_ 841 ParkingHeater_IndicationCmd_ISig 3000;
BA_REL_ "GenSigTimeoutTime" BU_SG_REL_ BBM SG_ 841 ParkingHeater_IndicationCmd_ISig 300;
BA_REL_ "GenSigFirstTimeoutTime" BU_SG_REL_ IC3 SG_ 841 AirFlowSelectionUpBtn_stat_ISig_ 3000;
BA_REL_ "GenSigTimeoutTime" BU_SG_REL_ IC3 SG_ 841 AirFlowSelectionUpBtn_stat_ISig_ 300;
BA_REL_ "GenSigFirstTimeoutTime" BU_SG_REL_ VMCU SG_ 841 ApproachLight_HMI_rqst 3000;
BA_REL_ "GenSigTimeoutTime" BU_SG_REL_ VMCU SG_ 841 ApproachLight_HMI_rqst 300;
BA_REL_ "GenSigFirstTimeoutTime" BU_SG_REL_ IC3 SG_ 841 Temperature_FreeWheelStatus_ISig 3000;
BA_REL_ "GenSigTimeoutTime" BU_SG_REL_ IC3 SG_ 841 Temperature_FreeWheelStatus_ISig 300;
BA_REL_ "GenSigFirstTimeoutTime" BU_SG_REL_ IC3 SG_ 841 AirBlowerSpeed_FreeWheelStatus_I 3000;
BA_REL_ "GenSigTimeoutTime" BU_SG_REL_ IC3 SG_ 841 AirBlowerSpeed_FreeWheelStatus_I 300;
BA_REL_ "GenSigFirstTimeoutTime" BU_SG_REL_ BBM SG_ 841 CabInteriorTempVentilated_Stat_I 3000;
BA_REL_ "GenSigTimeoutTime" BU_SG_REL_ BBM SG_ 841 CabInteriorTempVentilated_Stat_I 300;
BA_REL_ "GenSigFirstTimeoutTime" BU_SG_REL_ IC3 SG_ 841 PreTrip_ButtonStat3 3000;
BA_REL_ "GenSigTimeoutTime" BU_SG_REL_ IC3 SG_ 841 PreTrip_ButtonStat3 300;
BA_REL_ "GenSigFirstTimeoutTime" BU_SG_REL_ IC3 SG_ 841 ParkHeaterCooler_ButtonStatus_IS 3000;
BA_REL_ "GenSigTimeoutTime" BU_SG_REL_ IC3 SG_ 841 ParkHeaterCooler_ButtonStatus_IS 300;
BA_REL_ "GenSigFirstTimeoutTime" BU_SG_REL_ IC3 SG_ 841 WindscreenDefrost_ButtonStatus_I 3000;
BA_REL_ "GenSigTimeoutTime" BU_SG_REL_ IC3 SG_ 841 WindscreenDefrost_ButtonStatus_I 300;
BA_REL_ "GenSigFirstTimeoutTime" BU_SG_REL_ IC3 SG_ 841 AC_ButtonStatus_ISig_4 3000;
BA_REL_ "GenSigTimeoutTime" BU_SG_REL_ IC3 SG_ 841 AC_ButtonStatus_ISig_4 300;
VAL_ 528 FASHapticFeedbackRequest_ISig_4 15 "FASHapticFeedbackRequest_NotAvailable" 14 "FASHapticFeedbackRequest_Error" 13 "FASHapticFeedbackRequest_Spare3" 12 "FASHapticFeedbackRequest_Spare2" 11 "FASHapticFeedbackRequest_Spare1" 10 "FASHapticFeedbackRequest_PredefinedFreqAndAmpl10" 9 "FASHapticFeedbackRequest_PredefinedFreqAndAmpl9" 8 "FASHapticFeedbackRequest_PredefinedFreqAndAmpl8" 7 "FASHapticFeedbackRequest_PredefinedFreqAndAmpl7" 6 "FASHapticFeedbackRequest_PredefinedFreqAndAmpl6" 5 "FASHapticFeedbackRequest_PredefinedFreqAndAmpl5" 4 "FASHapticFeedbackRequest_PredefinedFreqAndAmpl4" 3 "FASHapticFeedbackRequest_PredefinedFreqAndAmpl3" 2 "FASHapticFeedbackRequest_PredefinedFreqAndAmpl2" 1 "FASHapticFeedbackRequest_PredefinedFreqAndAmpl1" 0 "FASHapticFeedbackRequest_NoHapticFeedback" ;
VAL_ 524 TSAMIntervntionCapabilityLeft 3 "TSAMIntervntionCapability_NotAvailable" 2 "TSAMIntervntionCapability_LBDetectedWarningsSteeringPossible" 1 "TSAMIntervntionCapability_LBDetectedWarningsPossible" 0 "TSAMIntervntionCapability_LBNotDetected" ;
VAL_ 524 TSAMIntervntionCapabilityRight 3 "TSAMIntervntionCapability_NotAvailable" 2 "TSAMIntervntionCapability_LBDetectedWarningsSteeringPossible" 1 "TSAMIntervntionCapability_LBDetectedWarningsPossible" 0 "TSAMIntervntionCapability_LBNotDetected" ;
VAL_ 524 PathDeviationSteeringStatus 7 "PathDeviationSteeringStatus_NotAvailable" 6 "PathDeviationSteeringStatus_Error" 5 "PathDeviationSteeringStatus_AvoidingRightSideCollision" 4 "PathDeviationSteeringStatus_AvoidingLeftSideCollision" 3 "PathDeviationSteeringStatus_AvoidingRightLaneDeparture" 2 "PathDeviationSteeringStatus_AvoidingLeftLaneDeparture" 1 "PathDeviationSteeringStatus_SteeringNotPossible" 0 "PathDeviationSteeringStatus_NoSteering" ;
VAL_ 946 CACCStatus 7 "CACCStatus_NotAvailable" 6 "CACCStatus_Error" 5 "CACCStatus_Spare3" 4 "CACCStatus_Spare2" 3 "CACCStatus_Spare1" 2 "CACCStatus_Active" 1 "CACCStatus_Available" 0 "CACCStatus_Unavailable" ;
VAL_ 946 PSC_DriverBrakingAllowed 3 "NotAllowedAllowed_NotAvailable" 2 "NotAllowedAllowed_Error" 1 "NotAllowedAllowed_Allowed" 0 "NotAllowedAllowed_NotAllowed" ;
VAL_ 946 VisionLight_stat 7 "VisionLight_stat_NotAvailable" 6 "VisionLight_stat_Error" 5 "VisionLight_stat_Spare02" 4 "VisionLight_stat_Spare01" 3 "VisionLight_stat_CameraBlockedCondition" 2 "VisionLight_stat_NightSufficientLight" 1 "VisionLight_stat_NightNotSufficientLight" 0 "VisionLight_stat_Day" ;
VAL_ 946 BBSteeringStatus 3 "InactiveActive_NotAvailable" 2 "InactiveActive_Error" 1 "InactiveActive_Active" 0 "InactiveActive_Inactive" ;
VAL_ 946 PSC_SetSpeedChangeRqst 3 "NoChangeChange_NotAvailable" 2 "NoChangeChange_Error" 1 "NoChangeChange_Change" 0 "NoChangeChange_NoChange" ;
VAL_ 744 ForwardLookingCameraStatus_ISig_ 15 "CameraStatus_NotAvailable" 14 "CameraStatus_Error" 13 "CameraStatus_Spare08" 12 "CameraStatus_Spare07" 11 "CameraStatus_Spare06" 10 "CameraStatus_Spare05" 9 "CameraStatus_Spare04" 8 "CameraStatus_Failure" 7 "CameraStatus_ShutDownCompleted" 6 "CameraStatus_ShutDownInitiated" 5 "CameraStatus_CalibrationOngoing" 4 "CameraStatus_NotCalibrated" 3 "CameraStatus_Misaligned" 2 "CameraStatus_Blocked" 1 "CameraStatus_WarmingUp" 0 "CameraStatus_FullyOperational" ;
VAL_ 744 XARDACU_ControlMode 3 "XARControlMode_NotDefined" 2 "XARControlMode_CoastingModeRequest" 1 "XARControlMode_AccelerationControlWithMaximumMode" 0 "XARControlMode_OverrideDisabled" ;
VAL_ 744 ACCiRollInhibit 3 "Inhibit_NotAvailable" 2 "Inhibit_Error" 1 "Inhibit_InhibitActive" 0 "Inhibit_NoInhibit" ;
VAL_ 744 CMReducedAbilityStatus 7 "ReducedAbilityStatus_NotAvailable" 6 "ReducedAbilityStatus_Error" 5 "ReducedAbilityStatus_Spare4" 4 "ReducedAbilityStatus_ReducedAbilityTrailer" 3 "ReducedAbilityStatus_ReducedAbilityABSVDC" 2 "ReducedAbilityStatus_ReducedAbilityCamera" 1 "ReducedAbilityStatus_ReducedAbilityHUD" 0 "ReducedAbilityStatus_NoReducedAbility" ;
VAL_ 744 ForwardLookingRadarStatus_ISig_4 15 "RadarStatus_NotAvailable" 14 "RadarStatus_Error" 13 "RadarStatus_Spare05" 12 "RadarStatus_Spare04" 11 "RadarStatus_Spare03" 10 "RadarStatus_Spare02" 9 "RadarStatus_Spare01" 8 "RadarStatus_Failure" 7 "RadarStatus_ShutDownCompleted" 6 "RadarStatus_ShutDownInitiated" 5 "RadarStatus_CalibrationOngoing" 4 "RadarStatus_NotCalibrated" 3 "RadarStatus_Misaligned" 2 "RadarStatus_Blocked" 1 "RadarStatus_WarmingUp" 0 "RadarStatus_FullyOperational" ;
VAL_ 744 LPOSBlocked 3 "FalseTrue_NotAvaiable" 2 "FalseTrue_Error" 1 "FalseTrue_True" 0 "FalseTrue_False" ;
VAL_ 744 CollSituationHazardLightReq 7 "ActivateDeactivateRqst3bit_NotAvailable" 6 "ActivateDeactivateRqst3bit_Error" 5 "ActivateDeactivateRqst3bit_Spare3" 4 "ActivateDeactivateRqst3bit_Spare2" 3 "ActivateDeactivateRqst3bit_Spare1" 2 "ActivateDeactivateRqst3bit_DeactivationRequest" 1 "ActivateDeactivateRqst3bit_ActivationRequest" 0 "ActivateDeactivateRqst3bit_NoRequest" ;
VAL_ 560 PathDeviationDriverAlert 7 "LKSDepartureWarningStatus_NotAvailable" 6 "LKSDepartureWarningStatus_ErrorIndication" 5 "LKSDepartureWarningStatus_MajorDepartureWarning_Right" 4 "LKSDepartureWarningStatus_MajorDepartureWarning_Left" 3 "LKSDepartureWarningStatus_MinorDepartureWarning_Right" 2 "LKSDepartureWarningStatus_MinorDepartureWarning_Left" 1 "LKSDepartureWarningStatus_WarningNotPossible" 0 "LKSDepartureWarningStatus_NoWarning" ;
VAL_ 560 CM_DisengageDrivelineRequest 3 "CM_DisengageDrivelineRequest_TakeNoAction" 2 "CM_DisengageDrivelineRequest_Reserved" 1 "CM_DisengageDrivelineRequest_DisengageDriveline" 0 "CM_DisengageDrivelineRequest_AllowDrivelineEngagement" ;
VAL_ 560 ACCBrakeRequestStatus 3 "InactiveActive_NotAvailable" 2 "InactiveActive_Error" 1 "InactiveActive_Active" 0 "InactiveActive_Inactive" ;
VAL_ 560 FrontalCollisionDriverAlert_ISig 7 "FCW_Warning_NotAvailable" 6 "FCW_Warning_ErrorIndicator" 5 "FCW_Warning_SpareValue_01" 4 "FCW_Warning_SpareValue" 3 "FCW_Warning_CMbBActiveWarning" 2 "FCW_Warning_CollisionWarning" 1 "FCW_Warning_PreliminaryCollisionWarning" 0 "FCW_Warning_NoWarning" ;
VAL_ 560 ACC_SGOFaultCondStat_SeatBelt 1 "SeatBeltIndicationRqst_IndicationRequested" 0 "SeatBeltIndicationRqst_NoIndicationRequested" ;
VAL_ 560 CM_Status_ISig_4 7 "CM_Status_NotAvailable" 6 "CM_Status_ErrorIndicator" 5 "CM_Status_CM_DisabledBySystem" 4 "CM_Status_CM_MitigationBrakingFinished" 3 "CM_Status_CM_MitigationBraking" 2 "CM_Status_CM_PreMitigationBraking" 1 "CM_Status_CM_Enabled" 0 "CM_Status_CM_Disabled" ;
VAL_ 560 DASApplicationStatus_ISig_4 7 "DASSystemStatus_NA" 6 "DASSystemStatus_Error" 5 "DASSystemStatus_SpareValue_01" 4 "DASSystemStatus_SpareValue" 3 "DASSystemStatus_Limited_func" 2 "DASSystemStatus_INACTIVE" 1 "DASSystemStatus_ACTIVE" 0 "DASSystemStatus_OFF" ;
VAL_ 560 ACC_Status 7 "ACC_Status_NotAvailable" 6 "ACC_Status_Error" 5 "ACC_Status_ACCFailureAndInactive" 4 "ACC_Status_Reserved" 3 "ACC_Status_ActiveWithLimitedBrakeCapacity" 2 "ACC_Status_ActiveECONOMYMODE" 1 "ACC_Status_ActiveSTANDARDMODE" 0 "ACC_Status_Inactive" ;
VAL_ 560 LKSApplicationStatus_ISig_4 7 "LKSStatus_NotAvailable" 6 "LKSStatus_Error" 5 "LKSStatus_Spare_02" 4 "LKSStatus_Spare_01" 3 "LKSStatus_Spare" 2 "LKSStatus_ACTIVE" 1 "LKSStatus_INACTIVE" 0 "LKSStatus_OFF" ;
VAL_ 560 LCSSystemStatus 7 "LCSSystemStatus_NotAvailable" 6 "LCSSystemStatus_Error" 5 "LCSSystemStatus_NotUsed" 4 "LCSSystemStatus_WarningRight" 3 "LCSSystemStatus_WarningLeft" 2 "LCSSystemStatus_EnabledAndActive" 1 "LCSSystemStatus_EnabledAndInactive" 0 "LCSSystemStatus_Disabled" ;
VAL_ 560 ACC_SGOFaultCondStat_SigStat 1 "SigStat_SignalNotAvailable" 0 "SigStat_SignalOK" ;
VAL_ 560 ACC_SGOFaultCondStat_Target 1 "TargetIndicationRqst_IndicationRequested" 0 "TargetIndicationRqst_NoIndicationRequested" ;
VAL_ 560 FCW_Status 3 "DisableEnable_NotAvailable" 2 "DisableEnable_Error" 1 "DisableEnable_Enable" 0 "DisableEnable_Disable" ;
VAL_ 560 DriverImpairedDriverAlert_ISig_4 7 "DASImpairmentWarningStatus_NotAvailable" 6 "DASImpairmentWarningStatus_ErrorIndicator" 5 "DASImpairmentWarningStatus_SPAREValue_02" 4 "DASImpairmentWarningStatus_SPAREValue_01" 3 "DASImpairmentWarningStatus_SPAREValue" 2 "DASImpairmentWarningStatus_MajorImpairmentWarning" 1 "DASImpairmentWarningStatus_MinorImpairmentWarning" 0 "DASImpairmentWarningStatus_NoWarning" ;
VAL_ 560 DriverVigilanceLevel 7 "DASVigilanceLevelStatus_NotAvailable" 6 "DASVigilanceLevelStatus_Error" 5 "DASVigilanceLevelStatus_VigilanceLevel5" 4 "DASVigilanceLevelStatus_VigilanceLevel4" 3 "DASVigilanceLevelStatus_VigilanceLevel3" 2 "DASVigilanceLevelStatus_VigilanceLevel2" 1 "DASVigilanceLevelStatus_VigilanceLevel1" 0 "DASVigilanceLevelStatus_DASUnavailable" ;
VAL_ 560 ACC_SGOFaultCondStat_Door 1 "DoorIndicationRqst_IndicationRequested" 0 "DoorIndicationRqst_NoIndicationRequested" ;
VAL_ 560 ACCTargetDetected 3 "ACCTargetDetected_TakeNoAction" 2 "ACCTargetDetected_Reserved" 1 "ACCTargetDetected_TargetDetected" 0 "ACCTargetDetected_NoTargetsDetected" ;
VAL_ 560 LKSCorrectiveSteeringStatus 7 "LKSCorrectiveSteeringStatus_NotAvailable" 6 "LKSCorrectiveSteeringStatus_Error" 5 "LKSCorrectiveSteeringStatus_Spare2" 4 "LKSCorrectiveSteeringStatus_TempUnavailable" 3 "LKSCorrectiveSteeringStatus_DriverTakeOverRqst" 2 "LKSCorrectiveSteeringStatus_Steering" 1 "LKSCorrectiveSteeringStatus_Available" 0 "LKSCorrectiveSteeringStatus_Off" ;
VAL_ 560 ACC_SGOFaultCondStat_Other 1 "IndicationRqst_IndicationRequested" 0 "IndicationRqst_NoIndicationRequested" ;
VAL_ 560 LCSSoundSettingStatus 3 "LCSSoundSettingStatus_NotAvailable" 2 "LCSSoundSettingStatus_Error" 1 "LCSSoundSettingStatus_LCSSoundAnabled" 0 "LCSSoundSettingStatus_LCSSoundDisabled" ;
VAL_ 560 ACC_SGOFaultCondStat_Speed 1 "SpeedIndicationRqst_IndicationRequested" 0 "SpeedIndicationRqst_NoIndicationRequested" ;
VAL_ 1369 ParkClimTimerStat_Tue_ISig_4 1 "NotSelectedSelected_Selected" 0 "NotSelectedSelected_NotSelected" ;
VAL_ 1369 ParkClimTimerStat_Mon_ISig_4 1 "NotSelectedSelected_Selected" 0 "NotSelectedSelected_NotSelected" ;
VAL_ 1369 ParkClimTimerStat_Thu_ISig_4 1 "NotSelectedSelected_Selected" 0 "NotSelectedSelected_NotSelected" ;
VAL_ 1369 ParkClimTimerStat_MinRes_ISig_4 7 "MinRes_NotAvailable" 6 "MinRes_Error" 5 "MinRes_NoMinutesResolution" 4 "MinRes_30Minutes" 3 "MinRes_15Minutes" 2 "MinRes_10Minutes" 1 "MinRes_5Minutes" 0 "MinRes_1Minutes" ;
VAL_ 1369 ParkClimTimerStat_Status_ISig_4 3 "ParkHeaterTimer_Status_NotAvailable" 2 "ParkHeaterTimer_Status_TimerDeleted" 1 "ParkHeaterTimer_Status_TimerNotActivated" 0 "ParkHeaterTimer_Status_TimerActivated" ;
VAL_ 1369 ParkClimTimerStat_Sun_ISig_4 1 "NotSelectedSelected_Selected" 0 "NotSelectedSelected_NotSelected" ;
VAL_ 1369 ParkClimTimerStat_Rec_ISig_4 1 "Rec_Recurrent" 0 "Rec_Once" ;
VAL_ 1369 ParkClimTimerStat_Wed_ISig_4 1 "NotSelectedSelected_Selected" 0 "NotSelectedSelected_NotSelected" ;
VAL_ 1369 ParkClimTimerStat_Type_ISig_4 7 "TimerType_NotAvailable" 6 "TimerType_Error" 5 "TimerType_Spare3" 4 "TimerType_Spare2" 3 "TimerType_Spare1" 2 "TimerType_CabClimateTimerWithStartTime" 1 "TimerType_EngineTimerWithReadyTime" 0 "TimerType_CabClimateTimerWithReadyTime" ;
VAL_ 1369 ParkClimTimerStat_Sat_ISig_4 1 "NotSelectedSelected_Selected" 0 "NotSelectedSelected_NotSelected" ;
VAL_ 1369 ParkClimTimerStat_Fri_ISig_4 1 "NotSelectedSelected_Selected" 0 "NotSelectedSelected_NotSelected" ;
VAL_ 551 BunkH1Next_ButtonStatus_ISig_4 3 "PushButtonStatus_NotAvailable" 2 "PushButtonStatus_Error" 1 "PushButtonStatus_Pushed" 0 "PushButtonStatus_Neutral" ;
VAL_ 551 BunkH1AudioOnOff_ButtonStatus_IS 3 "PushButtonStatus_NotAvailable" 2 "PushButtonStatus_Error" 1 "PushButtonStatus_Pushed" 0 "PushButtonStatus_Neutral" ;
VAL_ 551 BunkH1AudioSource_rqst_ISig_4 7 "BunkH1AudioSource_rqst_NotAvailable" 6 "BunkH1AudioSource_rqst_Error" 5 "BunkH1AudioSource_rqst_AUX1" 4 "BunkH1AudioSource_rqst_iPod" 3 "BunkH1AudioSource_rqst_AUX2" 2 "BunkH1AudioSource_rqst_USB" 1 "BunkH1AudioSource_rqst_CD" 0 "BunkH1AudioSource_rqst_Radio" ;
VAL_ 551 BunkH1VolumeUp_ButtonStatus_ISig 3 "PushButtonStatus_NotAvailable" 2 "PushButtonStatus_Error" 1 "PushButtonStatus_Pushed" 0 "PushButtonStatus_Neutral" ;
VAL_ 551 BunkH1VolumeDown_ButtonStatus_IS 3 "PushButtonStatus_NotAvailable" 2 "PushButtonStatus_Error" 1 "PushButtonStatus_Pushed" 0 "PushButtonStatus_Neutral" ;
VAL_ 551 BunkH1AudioSource_rqst2_ISig_4 15 "AudioSource_rqst4bit_NotAvailable" 14 "AudioSource_rqst4bit_Error" 13 "AudioSource_rqst4bit_Spare7" 12 "AudioSource_rqst4bit_Spare6" 11 "AudioSource_rqst4bit_Spare5" 10 "AudioSource_rqst4bit_Spare4" 9 "AudioSource_rqst4bit_Spare3" 8 "AudioSource_rqst4bit_Spare2" 7 "AudioSource_rqst4bit_Spare1" 6 "AudioSource_rqst4bit_BtStream" 5 "AudioSource_rqst4bit_AUX1" 4 "AudioSource_rqst4bit_IPOD" 3 "AudioSource_rqst4bit_AUX2" 2 "AudioSource_rqst4bit_USB" 1 "AudioSource_rqst4bit_CD" 0 "AudioSource_rqst4bit_Radio" ;
VAL_ 551 BunkH1Mute_ButtonStatus_ISig_4 3 "PushButtonStatus_NotAvailable" 2 "PushButtonStatus_Error" 1 "PushButtonStatus_Pushed" 0 "PushButtonStatus_Neutral" ;
VAL_ 551 BunkH1Prev_ButtonStatus_ISig_4 3 "PushButtonStatus_NotAvailable" 2 "PushButtonStatus_Error" 1 "PushButtonStatus_Pushed" 0 "PushButtonStatus_Neutral" ;
VAL_ 551 AutoBlowerLevel_Status_ISig_4 7 "AutoBlowerLevel_NotAvailable" 6 "AutoBlowerLevel_Error" 5 "AutoBlowerLevel_Spare_02" 4 "AutoBlowerLevel_Spare_01" 3 "AutoBlowerLevel_Spare" 2 "AutoBlowerLevel_Low" 1 "AutoBlowerLevel_Normal" 0 "AutoBlowerLevel_High" ;
VAL_ 551 AutoDefogmode_Status_ISig_4 7 "AutoDefogmode_NotAvailable" 6 "AutoDefogmode_Error" 5 "AutoDefogmode_Spare_01" 4 "AutoDefogmode_Spare" 3 "AutoDefogmode_Moderate" 2 "AutoDefogmode_Normal" 1 "AutoDefogmode_Sensitive" 0 "AutoDefogmode_OFF" ;
VAL_ 551 AQSmode_Status_ISig_4 3 "AQSMode_NotAvailable" 2 "AQSMode_Error" 1 "AQSMode_Auto" 0 "AQSMode_OFF" ;
VAL_ 551 ACmode_Status_ISig_4 7 "ACMode_NotAvailable" 6 "ACMode_Error" 5 "ACMode_Spare_01" 4 "ACMode_Spare" 3 "ACMode_ExtraDryCabAir" 2 "ACMode_HumidCabAir" 1 "ACMode_Standard" 0 "ACMode_Economy" ;
VAL_ 550 LKSCSEnableSwitch_rqst 3 "OffOn_NotAvailable" 2 "OffOn_Error" 1 "OffOn_On" 0 "OffOn_Off" ;
VAL_ 1371 SRSWarningLamp_ISig_4 3 "OffOnSpare_NotAvailable" 2 "OffOnSpare_Spare" 1 "OffOnSpare_On" 0 "OffOnSpare_Off" ;
VAL_ 1371 EvChargingConnectorUnlock_rqst 3 "UnlockAllowed_NotAvailable" 2 "UnlockAllowed_Error" 1 "UnlockAllowed_UnlockingAllowed" 0 "UnlockAllowed_Idle" ;
VAL_ 1371 TrafficAccidentHazardLightRqst_I 3 "Request_NotAvailable" 2 "Request_Error" 1 "Request_RequestActive" 0 "Request_NotRequested" ;
VAL_ 1371 PHCleanStatFeedback_ISig_4 3 "ActiveStatus_NotAvailable" 2 "ActiveStatus_Error" 1 "ActiveStatus_Active" 0 "ActiveStatus_NotActive" ;
VAL_ 1371 GearboxUnlockAuth_stat 7 "GearboxUnlockAuth_stat_NotAvaiable" 6 "GearboxUnlockAuth_stat_Error" 5 "GearboxUnlockAuth_stat_Spare3" 4 "GearboxUnlockAuth_stat_Spare2" 3 "GearboxUnlockAuth_stat_Spare1" 2 "GearboxUnlockAuth_stat_GearEngagementRefused" 1 "GearboxUnlockAuth_stat_GearEngagementAllowed" 0 "GearboxUnlockAuth_stat_Idle" ;
VAL_ 1371 TemperatureRqstIndication_cmd_IS 31 "TemperatureRqstIndication_cmd_NotAvailable" 30 "TemperatureRqstIndication_cmd_Error" 29 "TemperatureRqstIndication_cmd_Spare_01" 28 "TemperatureRqstIndication_cmd_Spare" 27 "TemperatureRqstIndication_cmd_Max" 26 "TemperatureRqstIndication_cmd_29C" 25 "TemperatureRqstIndication_cmd_28C" 24 "TemperatureRqstIndication_cmd_27C" 23 "TemperatureRqstIndication_cmd_26C" 22 "TemperatureRqstIndication_cmd_25_5C" 21 "TemperatureRqstIndication_cmd_25C" 20 "TemperatureRqstIndication_cmd_24_5C" 19 "TemperatureRqstIndication_cmd_24C" 18 "TemperatureRqstIndication_cmd_23_5C" 17 "TemperatureRqstIndication_cmd_23C" 16 "TemperatureRqstIndication_cmd_22_5C" 15 "TemperatureRqstIndication_cmd_22C" 14 "TemperatureRqstIndication_cmd_21_5C" 13 "TemperatureRqstIndication_cmd_21C" 12 "TemperatureRqstIndication_cmd_20_5C" 11 "TemperatureRqstIndication_cmd_20C" 10 "TemperatureRqstIndication_cmd_19_5C" 9 "TemperatureRqstIndication_cmd_19C" 8 "TemperatureRqstIndication_cmd_18_5C" 7 "TemperatureRqstIndication_cmd_18C" 6 "TemperatureRqstIndication_cmd_17_5C" 5 "TemperatureRqstIndication_cmd_17C" 4 "TemperatureRqstIndication_cmd_16_5C" 3 "TemperatureRqstIndication_cmd_16C" 2 "TemperatureRqstIndication_cmd_15C" 1 "TemperatureRqstIndication_cmd_Min" 0 "TemperatureRqstIndication_cmd_NoTempDisplayed" ;
VAL_ 1371 PassengersSeatBelt_ISig_4 7 "PassengersSeatBelt_NotAvailable" 6 "PassengersSeatBelt_Error" 5 "PassengersSeatBelt_Spare3" 4 "PassengersSeatBelt_Spare2" 3 "PassengersSeatBelt_Spare1" 2 "PassengersSeatBelt_PassengersNotSeated" 1 "PassengersSeatBelt_PassengersFastened" 0 "PassengersSeatBelt_AtLeastOnePassengerSeatedNotFastened" ;
VAL_ 922 MediaSourcesListReq_SInfo_ISig_4 3 "SignalInfo2bitType_NotAvailable" 2 "SignalInfo2bitType_ErrorIndication" 1 "SignalInfo2bitType_Spare" 0 "SignalInfo2bitType_Valid" ;
VAL_ 964 AlmClkSetAlm_LECM_rq_Type_ISig_4 7 "AlarmClkType_NotAvailable" 6 "AlarmClkType_Error" 5 "AlarmClkType_Reserved_02" 4 "AlarmClkType_Reserved_01" 3 "AlarmClkType_Reserved" 2 "AlarmClkType_Radio" 1 "AlarmClkType_Buzzer" 0 "AlarmClkType_NoAudibleNotification" ;
VAL_ 964 AlmClkSetAlm_LECM_rq_ID_ISig_4 127 "AlarmClkID_NotAvailable" 126 "AlarmClkID_Error" 10 "AlarmClkID_Alarm10" 9 "AlarmClkID_Alarm9" 8 "AlarmClkID_Alarm8" 7 "AlarmClkID_Alarm7" 6 "AlarmClkID_Alarm6" 5 "AlarmClkID_Alarm5" 4 "AlarmClkID_Alarm4" 3 "AlarmClkID_Alarm3" 2 "AlarmClkID_Alarm2" 1 "AlarmClkID_Alarm1" 0 "AlarmClkID_NotUsed" ;
VAL_ 964 AlmClkSetAlm_LECM_rq_Stat_ISig_4 3 "AlarmClkStat2_Snoozed" 2 "AlarmClkStat2_Ringing" 1 "AlarmClkStat2_Active" 0 "AlarmClkStat2_Inactive" ;
VAL_ 964 AlmClkSetAlm_LECM_rq_Mode_ISig_4 3 "AlarmClkMode_Spare" 2 "AlarmClkMode_Timer" 1 "AlarmClkMode_Recurrent" 0 "AlarmClkMode_OneTime" ;
VAL_ 845 ExtraHeating_status_ISig_4 3 "OffAuto_NotAvailable" 2 "OffAuto_Error" 1 "OffAuto_AutoStart" 0 "OffAuto_Off" ;
VAL_ 845 FrontalCollisionAccidentStatus_I 3 "NotDetected_NotAvaliable" 2 "NotDetected_Error" 1 "NotDetected_Detected" 0 "NotDetected_NotDetected" ;
VAL_ 845 TipperUpDownRequest_ISig_4 7 "UpDown_NotAvailable" 6 "UpDown_Error" 5 "UpDown_Spare2" 4 "UpDown_Spare1" 3 "UpDown_RequestDownAuto" 2 "UpDown_RequestDown" 1 "UpDown_RequestUp" 0 "UpDown_NoRequest" ;
VAL_ 845 LoadDistributionRequested_ISig_4 15 "LoadDistributionRequested_NotAvailable" 14 "LoadDistributionRequested_Error" 13 "LoadDistributionRequested_Reserved5" 12 "LoadDistributionRequested_Reserved4" 11 "LoadDistributionRequested_Reserved3" 10 "LoadDistributionRequested_Reserved2" 9 "LoadDistributionRequested_Reserved1" 8 "LoadDistributionRequested_DelpressLoadDistribution" 7 "LoadDistributionRequested_VariableLoadDistribution" 6 "LoadDistributionRequested_AlternativeLoadDistribution" 5 "LoadDistributionRequested_MaximumTraction2" 4 "LoadDistributionRequested_MaximumTraction1" 3 "LoadDistributionRequested_OptimizedTraction" 2 "LoadDistributionRequested_NormalLoadDistribution" 1 "LoadDistributionRequested_DefaultLoadDistribution" 0 "LoadDistributionRequested_NoAction" ;
VAL_ 845 TipperTailGateRequest_ISig_4 7 "OpenCloseRqst_NotAvailable" 6 "OpenCloseRqst_Error" 5 "OpenCloseRqst_Spare3" 4 "OpenCloseRqst_Spare2" 3 "OpenCloseRqst_Spare1" 2 "OpenCloseRqst_Close" 1 "OpenCloseRqst_Open" 0 "OpenCloseRqst_NoRequest" ;
VAL_ 845 TipperTippingBodySelection_ISig_ 3 "PrimarySecondary_NotAvailable" 2 "PrimarySecondary_Error" 1 "PrimarySecondary_Secondary" 0 "PrimarySecondary_Primary" ;
VAL_ 845 TipperEmergencyStop_ISig_4 3 "StopRqst_NotAvailable" 2 "StopRqst_Error" 1 "StopRqst_Stop" 0 "StopRqst_NoRequest" ;
VAL_ 845 ExtraBbWrcWatchdog_ISig_4 3 "LowHigh_NotAvailable" 2 "LowHigh_Error" 1 "LowHigh_High" 0 "LowHigh_Low" ;
VAL_ 845 AutoFrontWheelDriveDrvReq 3 "DisengageEngage_NotAvailable" 2 "DisengageEngage_Error" 1 "DisengageEngage_Engage" 0 "DisengageEngage_Disengage" ;
VAL_ 845 ShortStopHeater_cmd_ISig_4 3 "Request_NotAvailable" 2 "Request_Error" 1 "Request_RequestActive" 0 "Request_NotRequested" ;
VAL_ 845 TailLiftMotionRequest_ISig_4 7 "RqstTiltUpDown_NotAvailable" 6 "RqstTiltUpDown_Error" 5 "RqstTiltUpDown_Spare" 4 "RqstTiltUpDown_TiltDown" 3 "RqstTiltUpDown_TiltUp" 2 "RqstTiltUpDown_RequestDown" 1 "RqstTiltUpDown_RequestUp" 0 "RqstTiltUpDown_NoRequest" ;
VAL_ 845 TipperShakerRequest_ISig_4 3 "ShakeRqst_NotAvailable" 2 "ShakeRqst_Error" 1 "ShakeRqst_Shake" 0 "ShakeRqst_NoRequest" ;
VAL_ 845 TrafficAccShutDownReq_Rqst_ISig_ 3 "Request_NotAvailable" 2 "Request_Error" 1 "Request_RequestActive" 0 "Request_NotRequested" ;
VAL_ 845 TipperTarpaulinRequest_ISig_4 7 "CoverUncoverRqst_NotAvailable" 6 "CoverUncoverRqst_Error" 5 "CoverUncoverRqst_Spare3" 4 "CoverUncoverRqst_Spare2" 3 "CoverUncoverRqst_Spare1" 2 "CoverUncoverRqst_Uncover" 1 "CoverUncoverRqst_Cover" 0 "CoverUncoverRqst_NoRequest" ;
VAL_ 845 ABSInhibitRqstDenied 3 "InactiveActive_NotAvailable" 2 "InactiveActive_Error" 1 "InactiveActive_Active" 0 "InactiveActive_Inactive" ;
VAL_ 982 PHTimer_rqst_SetAlarmOper_ISig_4 7 "SetAlarmOperation_NotAvailable" 6 "SetAlarmOperation_Error" 5 "SetAlarmOperation_Spare_02" 4 "SetAlarmOperation_Spare_01" 3 "SetAlarmOperation_Reset" 2 "SetAlarmOperation_Continue" 1 "SetAlarmOperation_Stop" 0 "SetAlarmOperation_Start" ;
VAL_ 982 PHTimer_rqst_DayOfWeekRq_ISig_4 15 "DayOfWeekRq_NotAvailable" 14 "DayOfWeekRq_Error" 13 "DayOfWeekRq_Spare_7" 12 "DayOfWeekRq_Spare_6" 11 "DayOfWeekRq_Spare_5" 10 "DayOfWeekRq_Spare_4" 9 "DayOfWeekRq_Spare_3" 8 "DayOfWeekRq_Spare_2" 7 "DayOfWeekRq_NoDay" 6 "DayOfWeekRq_Sunday" 5 "DayOfWeekRq_Saturday" 4 "DayOfWeekRq_Friday" 3 "DayOfWeekRq_Thursday" 2 "DayOfWeekRq_Wednesday" 1 "DayOfWeekRq_Tuesday" 0 "DayOfWeekRq_Monday" ;
VAL_ 928 CabTilt_rqst 3 "InactiveActive_NotAvailable" 2 "InactiveActive_Error" 1 "InactiveActive_Active" 0 "InactiveActive_Inactive" ;
VAL_ 928 Pto3CabRequest 3 "OffOn_NotAvailable" 2 "OffOn_Error" 1 "OffOn_On" 0 "OffOn_Off" ;
VAL_ 928 Pto4CabRequest 3 "OffOn_NotAvailable" 2 "OffOn_Error" 1 "OffOn_On" 0 "OffOn_Off" ;
VAL_ 928 WindscreenDefrostInd_cmd_ISig_4 1 "IndicationCmd_ONLEDActivated" 0 "IndicationCmd_OFFLEDNotActivated" ;
VAL_ 928 SRSAirbagStatus_ISig_4 3 "SRSAirbagStatus_NotAvailable" 2 "SRSAirbagStatus_ErrorIndicator" 1 "SRSAirbagStatus_DriverAirbagDeployed" 0 "SRSAirbagStatus_NoAirbagDeployed" ;
VAL_ 928 FrontLidAjar_Stat 3 "ClosedOpen_NotAvailable" 2 "ClosedOpen_Error" 1 "ClosedOpen_Open" 0 "ClosedOpen_Closed" ;
VAL_ 928 ParkingHeaterCleaning_Rqst_ISig_ 3 "Request_NotAvailable" 2 "Request_Error" 1 "Request_RequestActive" 0 "Request_NotRequested" ;
VAL_ 928 Pto2CabRequest 3 "OffOn_NotAvailable" 2 "OffOn_Error" 1 "OffOn_On" 0 "OffOn_Off" ;
VAL_ 928 TemporaryRSLSwitchStatus 3 "A2PosSwitchStatus_NotAvailable" 2 "A2PosSwitchStatus_Error" 1 "A2PosSwitchStatus_On" 0 "A2PosSwitchStatus_Off" ;
VAL_ 928 SeatSwivelWarning_rqst 3 "InactiveActive_NotAvailable" 2 "InactiveActive_Error" 1 "InactiveActive_Active" 0 "InactiveActive_Inactive" ;
VAL_ 928 Pto1CabRequest 3 "OffOn_NotAvailable" 2 "OffOn_Error" 1 "OffOn_On" 0 "OffOn_Off" ;
VAL_ 928 ThreePosDifflockSwitch_stat 7 "A3PosSwitchStatus_NotAvailable" 6 "A3PosSwitchStatus_Error" 5 "A3PosSwitchStatus_Spare_02" 4 "A3PosSwitchStatus_Spare_01" 3 "A3PosSwitchStatus_Spare" 2 "A3PosSwitchStatus_Upper" 1 "A3PosSwitchStatus_Lower" 0 "A3PosSwitchStatus_Middle" ;
VAL_ 857 LCS_EnableSwitch_rqst 3 "OffOn_NotAvailable" 2 "OffOn_Error" 1 "OffOn_On" 0 "OffOn_Off" ;
VAL_ 857 EscCrossCountryActivation_rqst 3 "DisableEnable_NotAvailable" 2 "DisableEnable_Error" 1 "DisableEnable_Enable" 0 "DisableEnable_Disable" ;
VAL_ 857 StaticCornerLightMode 3 "DisableEnable_NotAvailable" 2 "DisableEnable_Error" 1 "DisableEnable_Enable" 0 "DisableEnable_Disable" ;
VAL_ 857 SplitBoxDifflockActvnDrvrRqst_IS 3 "DisengageEngage_NotAvailable" 2 "DisengageEngage_Error" 1 "DisengageEngage_Engage" 0 "DisengageEngage_Disengage" ;
VAL_ 857 ATCFrontWheelDriveRequest 3 "AutomaticOffOn_NotAvailable" 2 "AutomaticOffOn_Error" 1 "AutomaticOffOn_AutomaticOn" 0 "AutomaticOffOn_AutomaticOff" ;
VAL_ 857 ConstructionSwitch_stat 3 "OffOn_NotAvailable" 2 "OffOn_Error" 1 "OffOn_On" 0 "OffOn_Off" ;
VAL_ 857 EscCabActionRequest 7 "EscActionRequest_NotAvailable" 6 "EscActionRequest_Error" 5 "EscActionRequest_Spare" 4 "EscActionRequest_Set" 3 "EscActionRequest_Decrease" 2 "EscActionRequest_Increase" 1 "EscActionRequest_Resume" 0 "EscActionRequest_NoRequest" ;
VAL_ 857 AdjustRequestForIdle 7 "EngineSpeedRequest_NotAvailable" 6 "EngineSpeedRequest_Error" 5 "EngineSpeedRequest_Spare" 4 "EngineSpeedRequest_Decrease" 3 "EngineSpeedRequest_Increase" 2 "EngineSpeedRequest_Activate" 1 "EngineSpeedRequest_Off" 0 "EngineSpeedRequest_NoRequest" ;
VAL_ 857 SCL_LogicPowerOutput_stat 3 "SCL_PowerOutput_stat_NotAvailable" 2 "SCL_PowerOutput_stat_Error" 1 "SCL_PowerOutput_stat_FaultDetected" 0 "SCL_PowerOutput_stat_NoFaultDetected" ;
VAL_ 857 StatTrailerBrakeSwitchStatus 3 "PushButtonStatus_NotAvailable" 2 "PushButtonStatus_Error" 1 "PushButtonStatus_Pushed" 0 "PushButtonStatus_Neutral" ;
VAL_ 857 RoofHatch_HMI_rqst 7 "RoofHatch_HMI_rqst_NotAvailable" 6 "RoofHatch_HMI_rqst_ErrorIndicator" 5 "RoofHatch_HMI_rqst_SpareValue_02" 4 "RoofHatch_HMI_rqst_SpareValue_01" 3 "RoofHatch_HMI_rqst_SpareValue" 2 "RoofHatch_HMI_rqst_Open" 1 "RoofHatch_HMI_rqst_Close" 0 "RoofHatch_HMI_rqst_NoAction" ;
VAL_ 857 EscCabEnable 3 "DisableEnable_NotAvailable" 2 "DisableEnable_Error" 1 "DisableEnable_Enable" 0 "DisableEnable_Disable" ;
VAL_ 857 ExtraSideMarkers_Rqst 3 "NeutralPushed_NotAvailable" 2 "NeutralPushed_Error" 1 "NeutralPushed_Pushed" 0 "NeutralPushed_Neutral" ;
VAL_ 857 LevelingThumbwheel_stat 31 "Thumbwheel_stat_NotAvaliable" 30 "Thumbwheel_stat_Error" 29 "Thumbwheel_stat_Spare_12" 28 "Thumbwheel_stat_Spare_11" 27 "Thumbwheel_stat_Spare_10" 26 "Thumbwheel_stat_Spare_09" 25 "Thumbwheel_stat_Spare_08" 24 "Thumbwheel_stat_Spare_07" 23 "Thumbwheel_stat_Spare_06" 22 "Thumbwheel_stat_Spare_05" 21 "Thumbwheel_stat_Spare_04" 20 "Thumbwheel_stat_Spare_03" 19 "Thumbwheel_stat_Spare_02" 18 "Thumbwheel_stat_Spare_01" 17 "Thumbwheel_stat_Spare" 16 "Thumbwheel_stat_ThumbWheelPos16" 15 "Thumbwheel_stat_ThumbWheelPos15" 14 "Thumbwheel_stat_ThumbWheelPos14" 13 "Thumbwheel_stat_ThumbWheelPos13" 12 "Thumbwheel_stat_ThumbWheelPos12" 11 "Thumbwheel_stat_ThumbWheelPos11" 10 "Thumbwheel_stat_ThumbWheelPos10" 9 "Thumbwheel_stat_ThumbWheelPos9" 8 "Thumbwheel_stat_ThumbWheelPos8" 7 "Thumbwheel_stat_ThumbWheelPos7" 6 "Thumbwheel_stat_ThumbWheelPos6" 5 "Thumbwheel_stat_ThumbWheelPos5" 4 "Thumbwheel_stat_ThumbWheelPos4" 3 "Thumbwheel_stat_ThumbWheelPos3" 2 "Thumbwheel_stat_ThumbWheelPos2" 1 "Thumbwheel_stat_ThumbWheelPos1" 0 "Thumbwheel_stat_ThumbWheelPos0" ;
VAL_ 857 DASActivation_rqst 3 "OffOn_NotAvailable" 2 "OffOn_Error" 1 "OffOn_On" 0 "OffOn_Off" ;
VAL_ 857 DriverSeatBeltSwitch_ISig_4 3 "DriverSeatBeltSwitch_NotAvailable" 2 "DriverSeatBeltSwitch_Error" 1 "DriverSeatBeltSwitch_SeatBeltBuckledFastened" 0 "DriverSeatBeltSwitch_SeatBeltUnbuckledUnfastened" ;
VAL_ 857 PinCode_stat 7 "PinCode_stat_NotAvailable" 6 "PinCode_stat_Error" 3 "PinCode_stat_GoodPinCode" 2 "PinCode_stat_WrongPinCode" 1 "PinCode_stat_NoPinCodeEntered" 0 "PinCode_stat_Idle" ;
VAL_ 857 WarmUp_Request 3 "DisableEnable_NotAvailable" 2 "DisableEnable_Error" 1 "DisableEnable_Enable" 0 "DisableEnable_Disable" ;
VAL_ 857 LKSEnableSwitch_rqst 3 "OffOn_NotAvailable" 2 "OffOn_Error" 1 "OffOn_On" 0 "OffOn_Off" ;
VAL_ 1044 AlmClkSnze_LECM_rqst_ID_ISig_4 127 "AlarmClkID_NotAvailable" 126 "AlarmClkID_Error" 10 "AlarmClkID_Alarm10" 9 "AlarmClkID_Alarm9" 8 "AlarmClkID_Alarm8" 7 "AlarmClkID_Alarm7" 6 "AlarmClkID_Alarm6" 5 "AlarmClkID_Alarm5" 4 "AlarmClkID_Alarm4" 3 "AlarmClkID_Alarm3" 2 "AlarmClkID_Alarm2" 1 "AlarmClkID_Alarm1" 0 "AlarmClkID_NotUsed" ;
VAL_ 1044 AlmClkSetCurAlm_rqst_ID 127 "AlarmClkID_NotAvailable" 126 "AlarmClkID_Error" 10 "AlarmClkID_Alarm10" 9 "AlarmClkID_Alarm9" 8 "AlarmClkID_Alarm8" 7 "AlarmClkID_Alarm7" 6 "AlarmClkID_Alarm6" 5 "AlarmClkID_Alarm5" 4 "AlarmClkID_Alarm4" 3 "AlarmClkID_Alarm3" 2 "AlarmClkID_Alarm2" 1 "AlarmClkID_Alarm1" 0 "AlarmClkID_NotUsed" ;
VAL_ 1044 AlmClkSnze_LECM_rqst_Action_ISig 7 "AlmClkSnzeAction_NotAvailable" 6 "AlmClkSnzeAction_Error" 5 "AlmClkSnzeAction_Spare02" 4 "AlmClkSnzeAction_Spare01" 3 "AlmClkSnzeAction_RequestToContinuePlay" 2 "AlmClkSnzeAction_RequestToTurnAlarmOff" 1 "AlmClkSnzeAction_RequestToSnoozeAlarm" 0 "AlmClkSnzeAction_NoRequest" ;
VAL_ 1044 AlmClkSetCurAlm_rqst_Stat 3 "AlarmClkStat_Spare" 2 "AlarmClkStat_NoUsed" 1 "AlarmClkStat_Active" 0 "AlarmClkStat_Inactive" ;
VAL_ 1044 CollSituationHMICtrlRequestVM 7 "CollSituationHMICtrlRequestVM_NotAvailable" 6 "CollSituationHMICtrlRequestVM_Spare4" 5 "CollSituationHMICtrlRequestVM_Spare3" 4 "CollSituationHMICtrlRequestVM_Spare2" 3 "CollSituationHMICtrlRequestVM_Spare1" 2 "CollSituationHMICtrlRequestVM_FCWdisabledOnAftermarket" 1 "CollSituationHMICtrlRequestVM_CM_FCWdisabledOnAftermarket" 0 "CollSituationHMICtrlRequestVM_NoIndication" ;
VAL_ 1044 AlmClkSetCurAlm_rqst_Type 7 "AlarmClkType_NotAvailable" 6 "AlarmClkType_Error" 5 "AlarmClkType_Reserved_02" 4 "AlarmClkType_Reserved_01" 3 "AlarmClkType_Reserved" 2 "AlarmClkType_Radio" 1 "AlarmClkType_Buzzer" 0 "AlarmClkType_NoAudibleNotification" ;
VAL_ 1044 WRC_Docking_stat_ISig_4 3 "Docking_stat_NotAvailable" 2 "Docking_stat_Error" 1 "Docking_stat_Docked" 0 "Docking_stat_Undocked" ;
VAL_ 847 MirrorSelectRightMainBtn_stat_IS 3 "PushButtonStatus_NotAvailable" 2 "PushButtonStatus_Error" 1 "PushButtonStatus_Pushed" 0 "PushButtonStatus_Neutral" ;
VAL_ 847 WRCEngineStopRequest_ISig_4 3 "PushButtonStatus_NotAvailable" 2 "PushButtonStatus_Error" 1 "PushButtonStatus_Pushed" 0 "PushButtonStatus_Neutral" ;
VAL_ 847 LiftAxle1DirectControl_ISig_4 7 "LiftAxleLiftPositionRequest_NotAvailable" 6 "LiftAxleLiftPositionRequest_Error" 5 "LiftAxleLiftPositionRequest_Reserved_02" 4 "LiftAxleLiftPositionRequest_Reserved_01" 3 "LiftAxleLiftPositionRequest_Reserved" 2 "LiftAxleLiftPositionRequest_Up" 1 "LiftAxleLiftPositionRequest_Down" 0 "LiftAxleLiftPositionRequest_Idle" ;
VAL_ 847 MirrorSelectRightWideBtn_stat_IS 3 "PushButtonStatus_NotAvailable" 2 "PushButtonStatus_Error" 1 "PushButtonStatus_Pushed" 0 "PushButtonStatus_Neutral" ;
VAL_ 847 PanicAlarmFromKeyfob_rqst 3 "Request_NotAvailable" 2 "Request_Error" 1 "Request_RequestActive" 0 "Request_NotRequested" ;
VAL_ 847 ParkingClimate_IndicationCmd_ISi 7 "ParkingClimate_IndicationCmd_NotAvailable" 6 "ParkingClimate_IndicationCmd_Error" 5 "ParkingClimate_IndicationCmd_Spare_01" 4 "ParkingClimate_IndicationCmd_ShortStopHeaterActivated" 3 "ParkingClimate_IndicationCmd_ParkCoolWithoutCompActivReducedMode" 2 "ParkingClimate_IndicationCmd_ParkCoolWithCompActivFullMode" 1 "ParkingClimate_IndicationCmd_ParkingHeaterActivated" 0 "ParkingClimate_IndicationCmd_NoSystemActivated" ;
VAL_ 847 MirrorSelectLeftWideBtn_stat_ISi 3 "PushButtonStatus_NotAvailable" 2 "PushButtonStatus_Error" 1 "PushButtonStatus_Pushed" 0 "PushButtonStatus_Neutral" ;
VAL_ 847 WRCEngineStartRequest_ISig_4 3 "PushButtonStatus_NotAvailable" 2 "PushButtonStatus_Error" 1 "PushButtonStatus_Pushed" 0 "PushButtonStatus_Neutral" ;
VAL_ 847 PW_Left_DS_SwStatus_ISig_4 7 "A5PosSwitchStatus_NotAvailable" 6 "A5PosSwitchStatus_Error" 5 "A5PosSwitchStatus_Spare" 4 "A5PosSwitchStatus_2StepLower" 3 "A5PosSwitchStatus_Lower" 2 "A5PosSwitchStatus_2StepUpper" 1 "A5PosSwitchStatus_Upper" 0 "A5PosSwitchStatus_Neutral" ;
VAL_ 847 RegenerationSwitchStatus 7 "A3PosSwitchStatus_NotAvailable" 6 "A3PosSwitchStatus_Error" 5 "A3PosSwitchStatus_Spare_02" 4 "A3PosSwitchStatus_Spare_01" 3 "A3PosSwitchStatus_Spare" 2 "A3PosSwitchStatus_Upper" 1 "A3PosSwitchStatus_Lower" 0 "A3PosSwitchStatus_Middle" ;
VAL_ 847 PW_Right_DS_SwStatus_ISig_4 7 "A5PosSwitchStatus_NotAvailable" 6 "A5PosSwitchStatus_Error" 5 "A5PosSwitchStatus_Spare" 4 "A5PosSwitchStatus_2StepLower" 3 "A5PosSwitchStatus_Lower" 2 "A5PosSwitchStatus_2StepUpper" 1 "A5PosSwitchStatus_Upper" 0 "A5PosSwitchStatus_Neutral" ;
VAL_ 847 DoorLock_stat_ISig_4 15 "DoorLock_stat_NotAvailable" 14 "DoorLock_stat_Error" 4 "DoorLock_stat_BothDoorsAreLocked" 3 "DoorLock_stat_PassengerDoorIsUnlocked" 2 "DoorLock_stat_DriverDoorIsUnlocked" 1 "DoorLock_stat_BothDoorsAreUnlocked" 0 "DoorLock_stat_Idle" ;
VAL_ 847 LuggageAjar_stat 7 "DoorAjar_stat_NotAvailable" 6 "DoorAjar_stat_Error" 2 "DoorAjar_stat_DoorOpen" 1 "DoorAjar_stat_DoorClosed" 0 "DoorAjar_stat_Idle" ;
VAL_ 847 AlarmStatus_stat_ISig_4 15 "AlarmStatus_stat_NotAvailable" 14 "AlarmStatus_stat_Error" 13 "AlarmStatus_stat_Spare_06" 12 "AlarmStatus_stat_Spare_05" 11 "AlarmStatus_stat_Spare_04" 10 "AlarmStatus_stat_Spare_03" 9 "AlarmStatus_stat_Spare_02" 8 "AlarmStatus_stat_Spare_01" 7 "AlarmStatus_stat_TamperMode" 6 "AlarmStatus_stat_ServiceMode" 5 "AlarmStatus_stat_AlarmMode" 4 "AlarmStatus_stat_PanicMode" 3 "AlarmStatus_stat_UnsetMode" 2 "AlarmStatus_stat_ReduceSetMode" 1 "AlarmStatus_stat_SetMode" 0 "AlarmStatus_stat_Idle" ;
VAL_ 847 AlarmTriggeringCause_stat_ISig_4 15 "AlarmTriggeringCause_stat_NotAvailable" 14 "AlarmTriggeringCause_stat_Error" 10 "AlarmTriggeringCause_stat_OtherTamperIssues" 9 "AlarmTriggeringCause_stat_DoorsConnectionTampered" 8 "AlarmTriggeringCause_stat_SirenConnectionTampered" 7 "AlarmTriggeringCause_stat_TrailerAlarmTriggered" 6 "AlarmTriggeringCause_stat_FrontHatchOpened" 5 "AlarmTriggeringCause_stat_LuggageCompartementOpened" 4 "AlarmTriggeringCause_stat_CabTilted" 3 "AlarmTriggeringCause_stat_MotionSensorTriggered" 2 "AlarmTriggeringCause_stat_PassengerDoorOpened" 1 "AlarmTriggeringCause_stat_DriverDoorOpened" 0 "AlarmTriggeringCause_stat_Idle" ;
VAL_ 847 DoorsAjar_stat_ISig_4 7 "DoorsAjar_stat_NotAvailable" 6 "DoorsAjar_stat_Error" 5 "DoorsAjar_stat_Spare" 4 "DoorsAjar_stat_BothDoorsAreOpen" 3 "DoorsAjar_stat_PassengerDoorIsOpen" 2 "DoorsAjar_stat_DriverDoorIsOpen" 1 "DoorsAjar_stat_BothDoorsAreClosed" 0 "DoorsAjar_stat_Idle" ;
VAL_ 847 DoorAutoFunction_rqst 3 "OffOn_NotAvailable" 2 "OffOn_Error" 1 "OffOn_On" 0 "OffOn_Off" ;
VAL_ 847 MirrorSelectLeftMainBtn_stat_ISi 3 "PushButtonStatus_NotAvailable" 2 "PushButtonStatus_Error" 1 "PushButtonStatus_Pushed" 0 "PushButtonStatus_Neutral" ;
VAL_ 841 FPBRChangeReq_ISig_4 3 "FPBRChangeReq_NotAvailable" 2 "FPBRChangeReq_Error" 1 "FPBRChangeReq_ChangeFPBRFunction" 0 "FPBRChangeReq_TakeNoAction" ;
VAL_ 841 HeadLampUpDown_SwitchStatus 7 "A3PosSwitchStatus_NotAvailable" 6 "A3PosSwitchStatus_Error" 5 "A3PosSwitchStatus_Spare_02" 4 "A3PosSwitchStatus_Spare_01" 3 "A3PosSwitchStatus_Spare" 2 "A3PosSwitchStatus_Upper" 1 "A3PosSwitchStatus_Lower" 0 "A3PosSwitchStatus_Middle" ;
VAL_ 841 Recirc_ButtonStatus_ISig_4 3 "PushButtonStatus_NotAvailable" 2 "PushButtonStatus_Error" 1 "PushButtonStatus_Pushed" 0 "PushButtonStatus_Neutral" ;
VAL_ 841 Auto_ButtonStatus_ISig_4 3 "PushButtonStatus_NotAvailable" 2 "PushButtonStatus_Error" 1 "PushButtonStatus_Pushed" 0 "PushButtonStatus_Neutral" ;
VAL_ 841 AirFlowSelectionFrontBtn_stat_IS 3 "PushButtonStatus_NotAvailable" 2 "PushButtonStatus_Error" 1 "PushButtonStatus_Pushed" 0 "PushButtonStatus_Neutral" ;
VAL_ 841 InteriorLightMode_rqst_IL_Mode 7 "IL_ModeReq_NotAvailable" 6 "IL_ModeReq_ErrorIndicator" 5 "IL_ModeReq_NonHMIModeMax" 4 "IL_ModeReq_NonHMIModeResting" 3 "IL_ModeReq_Max" 2 "IL_ModeReq_Resting" 1 "IL_ModeReq_NightDriving" 0 "IL_ModeReq_OFF" ;
VAL_ 841 InteriorLightMode_rqst_EventFlag 1 "EventFlag_High" 0 "EventFlag_Low" ;
VAL_ 841 BlackOutConvoyModeSwitchStatus 7 "A3PosSwitchStatus_NotAvailable" 6 "A3PosSwitchStatus_Error" 5 "A3PosSwitchStatus_Spare_02" 4 "A3PosSwitchStatus_Spare_01" 3 "A3PosSwitchStatus_Spare" 2 "A3PosSwitchStatus_Upper" 1 "A3PosSwitchStatus_Lower" 0 "A3PosSwitchStatus_Middle" ;
VAL_ 841 Indicator_Lights_Alarm_rqst_ISig 7 "Indicator_Lights_Alarm_rqst_NotAvailable" 6 "Indicator_Lights_Alarm_rqst_Error" 5 "Indicator_Lights_Alarm_rqst_Spare_02" 4 "Indicator_Lights_Alarm_rqst_Spare_01" 3 "Indicator_Lights_Alarm_rqst_Spare" 2 "Indicator_Lights_Alarm_rqst_DeactivateIndLightsNoWarnings" 1 "Indicator_Lights_Alarm_rqst_ActivateIndicatorLightsWarnings" 0 "Indicator_Lights_Alarm_rqst_Idle" ;
VAL_ 841 AirFlowSelectionDownBtn_stat_ISi 3 "PushButtonStatus_NotAvailable" 2 "PushButtonStatus_Error" 1 "PushButtonStatus_Pushed" 0 "PushButtonStatus_Neutral" ;
VAL_ 841 ParkingHeater_IndicationCmd_ISig 1 "IndicationCmd_ONLEDActivated" 0 "IndicationCmd_OFFLEDNotActivated" ;
VAL_ 841 AirFlowSelectionUpBtn_stat_ISig_ 3 "PushButtonStatus_NotAvailable" 2 "PushButtonStatus_Error" 1 "PushButtonStatus_Pushed" 0 "PushButtonStatus_Neutral" ;
VAL_ 841 ApproachLight_HMI_rqst 3 "InactiveActive_NotAvailable" 2 "InactiveActive_Error" 1 "InactiveActive_Active" 0 "InactiveActive_Inactive" ;
VAL_ 841 Temperature_FreeWheelStatus_ISig 15 "FreeWheel_Status_NotAvailable" 14 "FreeWheel_Status_Error" 13 "FreeWheel_Status_Spare" 12 "FreeWheel_Status_6StepsCounterClockwise" 11 "FreeWheel_Status_5StepsCounterClockwise" 10 "FreeWheel_Status_4StepsCounterClockwise" 9 "FreeWheel_Status_3StepsCounterClockwise" 8 "FreeWheel_Status_2StepsCounterClockwise" 7 "FreeWheel_Status_1StepCounterClockwise" 6 "FreeWheel_Status_6StepsClockwise" 5 "FreeWheel_Status_5StepsClockwise" 4 "FreeWheel_Status_4StepsClockwise" 3 "FreeWheel_Status_3StepsClockwise" 2 "FreeWheel_Status_2StepsClockwise" 1 "FreeWheel_Status_1StepClockwise" 0 "FreeWheel_Status_NoMovement" ;
VAL_ 841 AirBlowerSpeed_FreeWheelStatus_I 15 "FreeWheel_Status_NotAvailable" 14 "FreeWheel_Status_Error" 13 "FreeWheel_Status_Spare" 12 "FreeWheel_Status_6StepsCounterClockwise" 11 "FreeWheel_Status_5StepsCounterClockwise" 10 "FreeWheel_Status_4StepsCounterClockwise" 9 "FreeWheel_Status_3StepsCounterClockwise" 8 "FreeWheel_Status_2StepsCounterClockwise" 7 "FreeWheel_Status_1StepCounterClockwise" 6 "FreeWheel_Status_6StepsClockwise" 5 "FreeWheel_Status_5StepsClockwise" 4 "FreeWheel_Status_4StepsClockwise" 3 "FreeWheel_Status_3StepsClockwise" 2 "FreeWheel_Status_2StepsClockwise" 1 "FreeWheel_Status_1StepClockwise" 0 "FreeWheel_Status_NoMovement" ;
VAL_ 841 PreTrip_ButtonStat3 3 "PushButtonStatus_NotAvailable" 2 "PushButtonStatus_Error" 1 "PushButtonStatus_Pushed" 0 "PushButtonStatus_Neutral" ;
VAL_ 841 ParkHeaterCooler_ButtonStatus_IS 3 "PushButtonStatus_NotAvailable" 2 "PushButtonStatus_Error" 1 "PushButtonStatus_Pushed" 0 "PushButtonStatus_Neutral" ;
VAL_ 841 WindscreenDefrost_ButtonStatus_I 3 "PushButtonStatus_NotAvailable" 2 "PushButtonStatus_Error" 1 "PushButtonStatus_Pushed" 0 "PushButtonStatus_Neutral" ;
VAL_ 841 AC_ButtonStatus_ISig_4 3 "PushButtonStatus_NotAvailable" 2 "PushButtonStatus_Error" 1 "PushButtonStatus_Pushed" 0 "PushButtonStatus_Neutral" ;
SIG_GROUP_ 524 GlareFreeArea02_sg_ISig_4 1 : GlareFreeArea02_LeftAngle_ISig_4 GlareFreeArea02_RightAngle_ISig_ GlareFreeArea02_Distance_ISig_4;
SIG_GROUP_ 522 GlareFreeArea03_sg_ISig_4 1 : GlareFreeArea03_Distance_ISig_4 GlareFreeArea03_LeftAngle_ISig_4 GlareFreeArea03_RightAngle_ISig_;
SIG_GROUP_ 522 GlareFreeArea01_sg_ISig_4 1 : GlareFreeArea01_LeftAngle_ISig_4 GlareFreeArea01_Distance_ISig_4 GlareFreeArea01_RightAngle_ISig_;
SIG_GROUP_ 744 XARDACU_sg 1 : XARDACU_ControlMode XARDACU_AccelDemand;
SIG_GROUP_ 560 ACC_SGOFaultCondStat_sg 1 : ACC_SGOFaultCondStat_SeatBelt ACC_SGOFaultCondStat_SigStat ACC_SGOFaultCondStat_Target ACC_SGOFaultCondStat_Door ACC_SGOFaultCondStat_Other ACC_SGOFaultCondStat_Speed;
SIG_GROUP_ 1460 ESSFnRqst_sg_ISig_4 1 : ESSFnRqst_FnNum_ISig_4 ESSFnRqst_FnPower_ISig_4;
SIG_GROUP_ 1369 ParkClimTimerStat_sg_ISig_4 1 : ParkClimTimerStat_Tue_ISig_4 ParkClimTimerStat_Mon_ISig_4 ParkClimTimerStat_Hrs_ISig_4 ParkClimTimerStat_TotalNoTimers_ ParkClimTimerStat_Thu_ISig_4 ParkClimTimerStat_MinRes_ISig_4 ParkClimTimerStat_Status_ISig_4 ParkClimTimerStat_Sun_ISig_4 ParkClimTimerStat_TimerNr_ISig_4 ParkClimTimerStat_Rec_ISig_4 ParkClimTimerStat_Wed_ISig_4 ParkClimTimerStat_Min_ISig_4 ParkClimTimerStat_Type_ISig_4 ParkClimTimerStat_Sat_ISig_4 ParkClimTimerStat_Temp_ISig_4 ParkClimTimerStat_Dur_ISig_4 ParkClimTimerStat_Fri_ISig_4;
SIG_GROUP_ 922 MediaSourcesListReq_sg_ISig_4 1 : MediaSourcesListReq_SInfo_ISig_4 MediaSourcesListReq_Items_ISig_4 MediaSourcesListReq_ItemID_ISig_;
SIG_GROUP_ 964 AlmClkSetAlm_LECM_rq_sg_ISig_4 1 : AlmClkSetAlm_LECM_rq_Type_ISig_4 AlmClkSetAlm_LECM_rq_ID_ISig_4 AlmClkSetAlm_LECM_rq_SetHr_ISig_ AlmClkSetAlm_LECM_rq_Stat_ISig_4 AlmClkSetAlm_LECM_rq_SetMin_ISig AlmClkSetAlm_LECM_rq_DaySet_ISig AlmClkSetAlm_LECM_rq_Mode_ISig_4;
SIG_GROUP_ 845 TrafficAccShutDownReq_sg_ISig_4 1 : TrafficAccShutDownReq_CRC_ISig_4 TrafficAccShutDownReq_Rqst_ISig_ TrafficAccShutDownReq_SqC_ISig_4;
SIG_GROUP_ 982 PHTimer_rqst_sg_ISig_4 1 : PHTimer_rqst_Hours_ISig_4 PHTimer_rqst_Minutes_ISig_4 PHTimer_rqst_SetAlarmOper_ISig_4 PHTimer_rqst_DayOfWeekRq_ISig_4;
SIG_GROUP_ 1044 AlmClkSnze_LECM_rqst_sg_ISig_4 1 : AlmClkSnze_LECM_rqst_ID_ISig_4 AlmClkSnze_LECM_rqst_Action_ISig;
SIG_GROUP_ 1044 AlmClkSetCurAlm_rqst_sg 1 : AlmClkSetCurAlm_rqst_ID AlmClkSetCurAlm_rqst_Stat AlmClkSetCurAlm_rqst_SetMin AlmClkSetCurAlm_rqst_SetHr AlmClkSetCurAlm_rqst_Type;
SIG_GROUP_ 841 InteriorLightMode_rqst_sg 1 : InteriorLightMode_rqst_IL_Mode InteriorLightMode_rqst_EventFlag;
